VERSION ""

NS_ :

BS_:
BU_: FLR_L FRR_L mADC

BO_ 604 FLR_L_25C: 64 FLR_L
 SG_ FLR_OBJ26_LostCnt : 483|4@0+ (1.0000000000,0.0000000000) [0.0000000000|15.0000000000] ""  FRR_L,mADC
 SG_ FLR_OBJ25_LostCnt : 495|4@0+ (1.0000000000,0.0000000000) [0.0000000000|15.0000000000] ""  FRR_L,mADC
 SG_ FLR_OBJ26_Dx : 230|13@0+ (0.0625000000,-256.0000000000) [-256.0000000000|255.9380000000] "m"  FRR_L,mADC
 SG_ FLR_OBJ26_Dy : 209|11@0+ (0.1250000000,-128.0000000000) [-128.0000000000|127.8750000000] "m"  FRR_L,mADC
 SG_ FLR_OBJ25_Dx : 59|13@0+ (0.0625000000,-256.0000000000) [-256.0000000000|255.9380000000] "m"  FRR_L,mADC
 SG_ FLR_OBJ25_Dy : 54|11@0+ (0.1250000000,-128.0000000000) [-128.0000000000|127.8750000000] "m"  FRR_L,mADC
 SG_ FLR_OBJ26_Vx : 310|12@0+ (0.0625000000,-128.0000000000) [-128.0000000000|127.9380000000] "m/s"  FRR_L,mADC
 SG_ FLR_OBJ26_Vy : 288|10@0+ (0.0625000000,-32.0000000000) [-32.0000000000|31.9375000000] "m/s"  FRR_L,mADC
 SG_ FLR_OBJ26_Convergence : 458|1@0+ (1.0000000000,0.0000000000) [0.0000000000|1.0000000000] ""  FRR_L,mADC
 SG_ FLR_OBJ26_DelayTime : 453|10@0+ (1.0000000000,0.0000000000) [0.0000000000|1023.0000000000] "ms"  FRR_L,mADC
 SG_ FLR_OBJ26_HeightGround : 424|9@0+ (0.1000000000,0.0000000000) [0.0000000000|51.1000000000] "m"  FRR_L,mADC
 SG_ FLR_OBJ26_MotionStatus : 470|3@0+ (1.0000000000,0.0000000000) [0.0000000000|7.0000000000] ""  FRR_L,mADC
 SG_ FLR_OBJ26_RelVx_std : 413|12@0+ (0.0625000000,0.0000000000) [0.0000000000|255.9375000000] "m/s"  FRR_L,mADC
 SG_ FLR_OBJ26_RelVy_std : 407|10@0+ (0.1250000000,0.0000000000) [0.0000000000|127.8750000000] "m/s"  FRR_L,mADC
 SG_ FLR_OBJ26_Dx_Vnce : 389|14@0+ (0.0500000000,0.0000000000) [0.0000000000|50.0000000000] "m2"  FRR_L,mADC
 SG_ FLR_OBJ26_Dy_Vnce : 383|10@0+ (0.0200000000,0.0000000000) [0.0000000000|20.0000000000] "m2"  FRR_L,mADC
 SG_ FLR_OBJ25_Vx : 139|12@0+ (0.0625000000,-128.0000000000) [-128.0000000000|127.9380000000] "m/s"  FRR_L,mADC
 SG_ FLR_OBJ25_Vy : 133|10@0+ (0.0625000000,-32.0000000000) [-32.0000000000|31.9375000000] "m/s"  FRR_L,mADC
 SG_ FLR_OBJ25_Convergence : 459|1@0+ (1.0000000000,0.0000000000) [0.0000000000|1.0000000000] ""  FRR_L,mADC
 SG_ FLR_OBJ25_DelayTime : 447|10@0+ (1.0000000000,0.0000000000) [0.0000000000|1023.0000000000] "ms"  FRR_L,mADC
 SG_ FLR_OBJ25_HeightGround : 417|9@0+ (0.1000000000,0.0000000000) [0.0000000000|51.1000000000] "m"  FRR_L,mADC
 SG_ FLR_OBJ25_MotionStatus : 457|3@0+ (1.0000000000,0.0000000000) [0.0000000000|7.0000000000] ""  FRR_L,mADC
 SG_ FLR_OBJ25_RelVx_std : 363|12@0+ (0.0625000000,0.0000000000) [0.0000000000|255.9375000000] "m/s"  FRR_L,mADC
 SG_ FLR_OBJ25_RelVy_std : 357|10@0+ (0.1250000000,0.0000000000) [0.0000000000|127.8750000000] "m/s"  FRR_L,mADC
 SG_ FLR_OBJ25_Dx_Vnce : 339|14@0+ (0.0500000000,0.0000000000) [0.0000000000|50.0000000000] "m2"  FRR_L,mADC
 SG_ FLR_OBJ25_Dy_Vnce : 333|10@0+ (0.0200000000,0.0000000000) [0.0000000000|20.0000000000] "m2"  FRR_L,mADC
 SG_ FLR_CRCCheck_25C : 503|16@0+ (1.0000000000,0.0000000000) [0.0000000000|65535.0000000000] ""  FRR_L,mADC
 SG_ FLR_RollingCounter_25C : 491|4@0+ (1.0000000000,0.0000000000) [0.0000000000|15.0000000000] ""  FRR_L,mADC
 SG_ FLR_OBJ26_Track_Age : 325|8@0+ (1.0000000000,0.0000000000) [0.0000000000|255.0000000000] ""  FRR_L,mADC
 SG_ FLR_OBJ26_RefPointLoc : 312|3@0+ (1.0000000000,0.0000000000) [0.0000000000|7.0000000000] ""  FRR_L,mADC
 SG_ FLR_OBJ26_ObstacleProb : 294|6@0+ (2.0000000000,0.0000000000) [0.0000000000|100.0000000000] "%"  FRR_L,mADC
 SG_ FLR_OBJ26_Measured : 280|2@0+ (1.0000000000,0.0000000000) [0.0000000000|3.0000000000] ""  FRR_L,mADC
 SG_ FLR_OBJ26_ExistProb : 286|6@0+ (2.0000000000,0.0000000000) [0.0000000000|100.0000000000] "%"  FRR_L,mADC
 SG_ FLR_OBJ26_Location : 272|2@0+ (1.0000000000,0.0000000000) [0.0000000000|3.0000000000] ""  FRR_L,mADC
 SG_ FLR_OBJ26_RelAx : 265|9@0+ (0.0625000000,-16.0000000000) [-16.0000000000|15.9375000000] "m/s2"  FRR_L,mADC
 SG_ FLR_OBJ26_RelAy : 259|10@0+ (0.0312500000,-16.0000000000) [-16.0000000000|15.9688000000] "m/s2"  FRR_L,mADC
 SG_ FLR_OBJ26_RelVx : 255|12@0+ (0.0625000000,-128.0000000000) [-128.0000000000|127.9380000000] "m/s"  FRR_L,mADC
 SG_ FLR_OBJ26_RelVy : 233|10@0+ (0.0625000000,-32.0000000000) [-32.0000000000|63.8750000000] "m/s"  FRR_L,mADC
 SG_ FLR_OBJ26_HeadingAngle : 203|10@0+ (0.0100000000,-3.1400000000) [-3.1400000000|3.1400000000] "rad"  FRR_L,mADC
 SG_ FLR_OBJ26_Length : 196|9@0+ (0.0500000000,0.0000000000) [0.0000000000|25.5000000000] "m"  FRR_L,mADC
 SG_ FLR_OBJ26_Height : 189|9@0+ (0.0100000000,0.0000000000) [0.0000000000|5.1100000000] "m"  FRR_L,mADC
 SG_ FLR_OBJ26_Width : 168|11@0+ (0.0100000000,0.0000000000) [0.0000000000|12.0000000000] "m"  FRR_L,mADC
 SG_ FLR_OBJ26_Type : 171|3@0+ (1.0000000000,0.0000000000) [0.0000000000|7.0000000000] ""  FRR_L,mADC
 SG_ FLR_OBJ26_Track_ID : 162|7@0+ (1.0000000000,0.0000000000) [0.0000000000|127.0000000000] ""  FRR_L,mADC
 SG_ FLR_OBJ25_Track_Age : 154|8@0+ (1.0000000000,0.0000000000) [0.0000000000|255.0000000000] ""  FRR_L,mADC
 SG_ FLR_OBJ25_RefPointLoc : 157|3@0+ (1.0000000000,0.0000000000) [0.0000000000|7.0000000000] ""  FRR_L,mADC
 SG_ FLR_OBJ25_ObstacleProb : 123|6@0+ (2.0000000000,0.0000000000) [0.0000000000|100.0000000000] "%"  FRR_L,mADC
 SG_ FLR_OBJ25_Measured : 125|2@0+ (1.0000000000,0.0000000000) [0.0000000000|3.0000000000] ""  FRR_L,mADC
 SG_ FLR_OBJ25_ExistProb : 115|6@0+ (2.0000000000,0.0000000000) [0.0000000000|100.0000000000] "%"  FRR_L,mADC
 SG_ FLR_OBJ25_Location : 117|2@0+ (1.0000000000,0.0000000000) [0.0000000000|3.0000000000] ""  FRR_L,mADC
 SG_ FLR_OBJ25_RelAx : 110|9@0+ (0.0625000000,-16.0000000000) [-16.0000000000|15.9375000000] "m/s2"  FRR_L,mADC
 SG_ FLR_OBJ25_RelAy : 88|10@0+ (0.0312500000,-16.0000000000) [-16.0000000000|15.9688000000] "m/s2"  FRR_L,mADC
 SG_ FLR_OBJ25_RelVx : 84|12@0+ (0.0625000000,-128.0000000000) [-128.0000000000|127.9380000000] "m/s"  FRR_L,mADC
 SG_ FLR_OBJ25_RelVy : 78|10@0+ (0.0625000000,-32.0000000000) [-32.0000000000|63.8750000000] "m/s"  FRR_L,mADC
 SG_ FLR_OBJ25_HeadingAngle : 32|10@0+ (0.0100000000,-3.1400000000) [-3.1400000000|3.1400000000] "rad"  FRR_L,mADC
 SG_ FLR_OBJ25_Length : 25|9@0+ (0.0500000000,0.0000000000) [0.0000000000|25.5000000000] "m"  FRR_L,mADC
 SG_ FLR_OBJ25_Height : 18|9@0+ (0.0100000000,0.0000000000) [0.0000000000|5.1100000000] "m"  FRR_L,mADC
 SG_ FLR_OBJ25_Width : 13|11@0+ (0.0100000000,0.0000000000) [0.0000000000|12.0000000000] "m"  FRR_L,mADC
 SG_ FLR_OBJ25_Type : 0|3@0+ (1.0000000000,0.0000000000) [0.0000000000|7.0000000000] ""  FRR_L,mADC
 SG_ FLR_OBJ25_Track_ID : 7|7@0+ (1.0000000000,0.0000000000) [0.0000000000|127.0000000000] ""  FRR_L,mADC

BO_ 605 FLR_L_25D: 64 FLR_L
 SG_ FLR_OBJ28_LostCnt : 483|4@0+ (1.0000000000,0.0000000000) [0.0000000000|15.0000000000] ""  FRR_L,mADC
 SG_ FLR_OBJ27_LostCnt : 495|4@0+ (1.0000000000,0.0000000000) [0.0000000000|15.0000000000] ""  FRR_L,mADC
 SG_ FLR_OBJ28_Dx : 230|13@0+ (0.0625000000,-256.0000000000) [-256.0000000000|255.9380000000] "m"  FRR_L,mADC
 SG_ FLR_OBJ28_Dy : 209|11@0+ (0.1250000000,-128.0000000000) [-128.0000000000|127.8750000000] "m"  FRR_L,mADC
 SG_ FLR_OBJ27_Dx : 59|13@0+ (0.0625000000,-256.0000000000) [-256.0000000000|255.9380000000] "m"  FRR_L,mADC
 SG_ FLR_OBJ27_Dy : 54|11@0+ (0.1250000000,-128.0000000000) [-128.0000000000|127.8750000000] "m"  FRR_L,mADC
 SG_ FLR_OBJ28_Vx : 310|12@0+ (0.0625000000,-128.0000000000) [-128.0000000000|127.9380000000] "m/s"  FRR_L,mADC
 SG_ FLR_OBJ28_Vy : 288|10@0+ (0.0625000000,-32.0000000000) [-32.0000000000|31.9375000000] "m/s"  FRR_L,mADC
 SG_ FLR_OBJ28_Convergence : 458|1@0+ (1.0000000000,0.0000000000) [0.0000000000|1.0000000000] ""  FRR_L,mADC
 SG_ FLR_OBJ28_DelayTime : 453|10@0+ (1.0000000000,0.0000000000) [0.0000000000|1023.0000000000] "ms"  FRR_L,mADC
 SG_ FLR_OBJ28_HeightGround : 424|9@0+ (0.1000000000,0.0000000000) [0.0000000000|51.1000000000] "m"  FRR_L,mADC
 SG_ FLR_OBJ28_MotionStatus : 470|3@0+ (1.0000000000,0.0000000000) [0.0000000000|7.0000000000] ""  FRR_L,mADC
 SG_ FLR_OBJ28_RelVx_std : 413|12@0+ (0.0625000000,0.0000000000) [0.0000000000|255.9375000000] "m/s"  FRR_L,mADC
 SG_ FLR_OBJ28_RelVy_std : 407|10@0+ (0.1250000000,0.0000000000) [0.0000000000|127.8750000000] "m/s"  FRR_L,mADC
 SG_ FLR_OBJ28_Dx_Vnce : 389|14@0+ (0.0500000000,0.0000000000) [0.0000000000|50.0000000000] "m2"  FRR_L,mADC
 SG_ FLR_OBJ28_Dy_Vnce : 383|10@0+ (0.0200000000,0.0000000000) [0.0000000000|20.0000000000] "m2"  FRR_L,mADC
 SG_ FLR_OBJ27_Vx : 139|12@0+ (0.0625000000,-128.0000000000) [-128.0000000000|127.9380000000] "m/s"  FRR_L,mADC
 SG_ FLR_OBJ27_Vy : 133|10@0+ (0.0625000000,-32.0000000000) [-32.0000000000|31.9375000000] "m/s"  FRR_L,mADC
 SG_ FLR_OBJ27_Convergence : 459|1@0+ (1.0000000000,0.0000000000) [0.0000000000|1.0000000000] ""  FRR_L,mADC
 SG_ FLR_OBJ27_DelayTime : 447|10@0+ (1.0000000000,0.0000000000) [0.0000000000|1023.0000000000] "ms"  FRR_L,mADC
 SG_ FLR_OBJ27_HeightGround : 417|9@0+ (0.1000000000,0.0000000000) [0.0000000000|51.1000000000] "m"  FRR_L,mADC
 SG_ FLR_OBJ27_MotionStatus : 457|3@0+ (1.0000000000,0.0000000000) [0.0000000000|7.0000000000] ""  FRR_L,mADC
 SG_ FLR_OBJ27_RelVx_std : 363|12@0+ (0.0625000000,0.0000000000) [0.0000000000|255.9375000000] "m/s"  FRR_L,mADC
 SG_ FLR_OBJ27_RelVy_std : 357|10@0+ (0.1250000000,0.0000000000) [0.0000000000|127.8750000000] "m/s"  FRR_L,mADC
 SG_ FLR_OBJ27_Dx_Vnce : 339|14@0+ (0.0500000000,0.0000000000) [0.0000000000|50.0000000000] "m2"  FRR_L,mADC
 SG_ FLR_OBJ27_Dy_Vnce : 333|10@0+ (0.0200000000,0.0000000000) [0.0000000000|20.0000000000] "m2"  FRR_L,mADC
 SG_ FLR_CRCCheck_25D : 503|16@0+ (1.0000000000,0.0000000000) [0.0000000000|65535.0000000000] ""  FRR_L,mADC
 SG_ FLR_RollingCounter_25D : 491|4@0+ (1.0000000000,0.0000000000) [0.0000000000|15.0000000000] ""  FRR_L,mADC
 SG_ FLR_OBJ28_Track_Age : 325|8@0+ (1.0000000000,0.0000000000) [0.0000000000|255.0000000000] ""  FRR_L,mADC
 SG_ FLR_OBJ28_RefPointLoc : 312|3@0+ (1.0000000000,0.0000000000) [0.0000000000|7.0000000000] ""  FRR_L,mADC
 SG_ FLR_OBJ28_ObstacleProb : 294|6@0+ (2.0000000000,0.0000000000) [0.0000000000|100.0000000000] "%"  FRR_L,mADC
 SG_ FLR_OBJ28_Measured : 280|2@0+ (1.0000000000,0.0000000000) [0.0000000000|3.0000000000] ""  FRR_L,mADC
 SG_ FLR_OBJ28_ExistProb : 286|6@0+ (2.0000000000,0.0000000000) [0.0000000000|100.0000000000] "%"  FRR_L,mADC
 SG_ FLR_OBJ28_Location : 272|2@0+ (1.0000000000,0.0000000000) [0.0000000000|3.0000000000] ""  FRR_L,mADC
 SG_ FLR_OBJ28_RelAx : 265|9@0+ (0.0625000000,-16.0000000000) [-16.0000000000|15.9375000000] "m/s2"  FRR_L,mADC
 SG_ FLR_OBJ28_RelAy : 259|10@0+ (0.0312500000,-16.0000000000) [-16.0000000000|15.9688000000] "m/s2"  FRR_L,mADC
 SG_ FLR_OBJ28_RelVx : 255|12@0+ (0.0625000000,-128.0000000000) [-128.0000000000|127.9380000000] "m/s"  FRR_L,mADC
 SG_ FLR_OBJ28_RelVy : 233|10@0+ (0.0625000000,-32.0000000000) [-32.0000000000|63.8750000000] "m/s"  FRR_L,mADC
 SG_ FLR_OBJ28_HeadingAngle : 203|10@0+ (0.0100000000,-3.1400000000) [-3.1400000000|3.1400000000] "rad"  FRR_L,mADC
 SG_ FLR_OBJ28_Length : 196|9@0+ (0.0500000000,0.0000000000) [0.0000000000|25.5000000000] "m"  FRR_L,mADC
 SG_ FLR_OBJ28_Height : 189|9@0+ (0.0100000000,0.0000000000) [0.0000000000|5.1100000000] "m"  FRR_L,mADC
 SG_ FLR_OBJ28_Width : 168|11@0+ (0.0100000000,0.0000000000) [0.0000000000|12.0000000000] "m"  FRR_L,mADC
 SG_ FLR_OBJ28_Type : 171|3@0+ (1.0000000000,0.0000000000) [0.0000000000|7.0000000000] ""  FRR_L,mADC
 SG_ FLR_OBJ28_Track_ID : 162|7@0+ (1.0000000000,0.0000000000) [0.0000000000|127.0000000000] ""  FRR_L,mADC
 SG_ FLR_OBJ27_Track_Age : 154|8@0+ (1.0000000000,0.0000000000) [0.0000000000|255.0000000000] ""  FRR_L,mADC
 SG_ FLR_OBJ27_RefPointLoc : 157|3@0+ (1.0000000000,0.0000000000) [0.0000000000|7.0000000000] ""  FRR_L,mADC
 SG_ FLR_OBJ27_ObstacleProb : 123|6@0+ (2.0000000000,0.0000000000) [0.0000000000|100.0000000000] "%"  FRR_L,mADC
 SG_ FLR_OBJ27_Measured : 125|2@0+ (1.0000000000,0.0000000000) [0.0000000000|3.0000000000] ""  FRR_L,mADC
 SG_ FLR_OBJ27_ExistProb : 115|6@0+ (2.0000000000,0.0000000000) [0.0000000000|100.0000000000] "%"  FRR_L,mADC
 SG_ FLR_OBJ27_Location : 117|2@0+ (1.0000000000,0.0000000000) [0.0000000000|3.0000000000] ""  FRR_L,mADC
 SG_ FLR_OBJ27_RelAx : 110|9@0+ (0.0625000000,-16.0000000000) [-16.0000000000|15.9375000000] "m/s2"  FRR_L,mADC
 SG_ FLR_OBJ27_RelAy : 88|10@0+ (0.0312500000,-16.0000000000) [-16.0000000000|15.9688000000] "m/s2"  FRR_L,mADC
 SG_ FLR_OBJ27_RelVx : 84|12@0+ (0.0625000000,-128.0000000000) [-128.0000000000|127.9380000000] "m/s"  FRR_L,mADC
 SG_ FLR_OBJ27_RelVy : 78|10@0+ (0.0625000000,-32.0000000000) [-32.0000000000|63.8750000000] "m/s"  FRR_L,mADC
 SG_ FLR_OBJ27_HeadingAngle : 32|10@0+ (0.0100000000,-3.1400000000) [-3.1400000000|3.1400000000] "rad"  FRR_L,mADC
 SG_ FLR_OBJ27_Length : 25|9@0+ (0.0500000000,0.0000000000) [0.0000000000|25.5000000000] "m"  FRR_L,mADC
 SG_ FLR_OBJ27_Height : 18|9@0+ (0.0100000000,0.0000000000) [0.0000000000|5.1100000000] "m"  FRR_L,mADC
 SG_ FLR_OBJ27_Width : 13|11@0+ (0.0100000000,0.0000000000) [0.0000000000|12.0000000000] "m"  FRR_L,mADC
 SG_ FLR_OBJ27_Type : 0|3@0+ (1.0000000000,0.0000000000) [0.0000000000|7.0000000000] ""  FRR_L,mADC
 SG_ FLR_OBJ27_Track_ID : 7|7@0+ (1.0000000000,0.0000000000) [0.0000000000|127.0000000000] ""  FRR_L,mADC

BO_ 606 FLR_L_25E: 64 FLR_L
 SG_ FLR_OBJ30_LostCnt : 483|4@0+ (1.0000000000,0.0000000000) [0.0000000000|15.0000000000] ""  FRR_L,mADC
 SG_ FLR_OBJ29_LostCnt : 495|4@0+ (1.0000000000,0.0000000000) [0.0000000000|15.0000000000] ""  FRR_L,mADC
 SG_ FLR_OBJ30_Dx : 230|13@0+ (0.0625000000,-256.0000000000) [-256.0000000000|255.9380000000] "m"  FRR_L,mADC
 SG_ FLR_OBJ30_Dy : 209|11@0+ (0.1250000000,-128.0000000000) [-128.0000000000|127.8750000000] "m"  FRR_L,mADC
 SG_ FLR_OBJ29_Dx : 59|13@0+ (0.0625000000,-256.0000000000) [-256.0000000000|255.9380000000] "m"  FRR_L,mADC
 SG_ FLR_OBJ29_Dy : 54|11@0+ (0.1250000000,-128.0000000000) [-128.0000000000|127.8750000000] "m"  FRR_L,mADC
 SG_ FLR_OBJ30_Vx : 310|12@0+ (0.0625000000,-128.0000000000) [-128.0000000000|127.9380000000] "m/s"  FRR_L,mADC
 SG_ FLR_OBJ30_Vy : 288|10@0+ (0.0625000000,-32.0000000000) [-32.0000000000|31.9375000000] "m/s"  FRR_L,mADC
 SG_ FLR_OBJ30_Convergence : 458|1@0+ (1.0000000000,0.0000000000) [0.0000000000|1.0000000000] ""  FRR_L,mADC
 SG_ FLR_OBJ30_DelayTime : 453|10@0+ (1.0000000000,0.0000000000) [0.0000000000|1023.0000000000] "ms"  FRR_L,mADC
 SG_ FLR_OBJ30_HeightGround : 424|9@0+ (0.1000000000,0.0000000000) [0.0000000000|51.1000000000] "m"  FRR_L,mADC
 SG_ FLR_OBJ30_MotionStatus : 470|3@0+ (1.0000000000,0.0000000000) [0.0000000000|7.0000000000] ""  FRR_L,mADC
 SG_ FLR_OBJ30_RelVx_std : 413|12@0+ (0.0625000000,0.0000000000) [0.0000000000|255.9375000000] "m/s"  FRR_L,mADC
 SG_ FLR_OBJ30_RelVy_std : 407|10@0+ (0.1250000000,0.0000000000) [0.0000000000|127.8750000000] "m/s"  FRR_L,mADC
 SG_ FLR_OBJ30_Dx_Vnce : 389|14@0+ (0.0500000000,0.0000000000) [0.0000000000|50.0000000000] "m2"  FRR_L,mADC
 SG_ FLR_OBJ30_Dy_Vnce : 383|10@0+ (0.0200000000,0.0000000000) [0.0000000000|20.0000000000] "m2"  FRR_L,mADC
 SG_ FLR_OBJ29_Vx : 139|12@0+ (0.0625000000,-128.0000000000) [-128.0000000000|127.9380000000] "m/s"  FRR_L,mADC
 SG_ FLR_OBJ29_Vy : 133|10@0+ (0.0625000000,-32.0000000000) [-32.0000000000|31.9375000000] "m/s"  FRR_L,mADC
 SG_ FLR_OBJ29_Convergence : 459|1@0+ (1.0000000000,0.0000000000) [0.0000000000|1.0000000000] ""  FRR_L,mADC
 SG_ FLR_OBJ29_DelayTime : 447|10@0+ (1.0000000000,0.0000000000) [0.0000000000|1023.0000000000] "ms"  FRR_L,mADC
 SG_ FLR_OBJ29_HeightGround : 417|9@0+ (0.1000000000,0.0000000000) [0.0000000000|51.1000000000] "m"  FRR_L,mADC
 SG_ FLR_OBJ29_MotionStatus : 457|3@0+ (1.0000000000,0.0000000000) [0.0000000000|7.0000000000] ""  FRR_L,mADC
 SG_ FLR_OBJ29_RelVx_std : 363|12@0+ (0.0625000000,0.0000000000) [0.0000000000|255.9375000000] "m/s"  FRR_L,mADC
 SG_ FLR_OBJ29_RelVy_std : 357|10@0+ (0.1250000000,0.0000000000) [0.0000000000|127.8750000000] "m/s"  FRR_L,mADC
 SG_ FLR_OBJ29_Dx_Vnce : 339|14@0+ (0.0500000000,0.0000000000) [0.0000000000|50.0000000000] "m2"  FRR_L,mADC
 SG_ FLR_OBJ29_Dy_Vnce : 333|10@0+ (0.0200000000,0.0000000000) [0.0000000000|20.0000000000] "m2"  FRR_L,mADC
 SG_ FLR_CRCCheck_25E : 503|16@0+ (1.0000000000,0.0000000000) [0.0000000000|65535.0000000000] ""  FRR_L,mADC
 SG_ FLR_RollingCounter_25E : 491|4@0+ (1.0000000000,0.0000000000) [0.0000000000|15.0000000000] ""  FRR_L,mADC
 SG_ FLR_OBJ30_Track_Age : 325|8@0+ (1.0000000000,0.0000000000) [0.0000000000|255.0000000000] ""  FRR_L,mADC
 SG_ FLR_OBJ30_RefPointLoc : 312|3@0+ (1.0000000000,0.0000000000) [0.0000000000|7.0000000000] ""  FRR_L,mADC
 SG_ FLR_OBJ30_ObstacleProb : 294|6@0+ (2.0000000000,0.0000000000) [0.0000000000|100.0000000000] "%"  FRR_L,mADC
 SG_ FLR_OBJ30_Measured : 280|2@0+ (1.0000000000,0.0000000000) [0.0000000000|3.0000000000] ""  FRR_L,mADC
 SG_ FLR_OBJ30_ExistProb : 286|6@0+ (2.0000000000,0.0000000000) [0.0000000000|100.0000000000] "%"  FRR_L,mADC
 SG_ FLR_OBJ30_Location : 272|2@0+ (1.0000000000,0.0000000000) [0.0000000000|3.0000000000] ""  FRR_L,mADC
 SG_ FLR_OBJ30_RelAx : 265|9@0+ (0.0625000000,-16.0000000000) [-16.0000000000|15.9375000000] "m/s2"  FRR_L,mADC
 SG_ FLR_OBJ30_RelAy : 259|10@0+ (0.0312500000,-16.0000000000) [-16.0000000000|15.9688000000] "m/s2"  FRR_L,mADC
 SG_ FLR_OBJ30_RelVx : 255|12@0+ (0.0625000000,-128.0000000000) [-128.0000000000|127.9380000000] "m/s"  FRR_L,mADC
 SG_ FLR_OBJ30_RelVy : 233|10@0+ (0.0625000000,-32.0000000000) [-32.0000000000|63.8750000000] "m/s"  FRR_L,mADC
 SG_ FLR_OBJ30_HeadingAngle : 203|10@0+ (0.0100000000,-3.1400000000) [-3.1400000000|3.1400000000] "rad"  FRR_L,mADC
 SG_ FLR_OBJ30_Length : 196|9@0+ (0.0500000000,0.0000000000) [0.0000000000|25.5000000000] "m"  FRR_L,mADC
 SG_ FLR_OBJ30_Height : 189|9@0+ (0.0100000000,0.0000000000) [0.0000000000|5.1100000000] "m"  FRR_L,mADC
 SG_ FLR_OBJ30_Width : 168|11@0+ (0.0100000000,0.0000000000) [0.0000000000|12.0000000000] "m"  FRR_L,mADC
 SG_ FLR_OBJ30_Type : 171|3@0+ (1.0000000000,0.0000000000) [0.0000000000|7.0000000000] ""  FRR_L,mADC
 SG_ FLR_OBJ30_Track_ID : 162|7@0+ (1.0000000000,0.0000000000) [0.0000000000|127.0000000000] ""  FRR_L,mADC
 SG_ FLR_OBJ29_Track_Age : 154|8@0+ (1.0000000000,0.0000000000) [0.0000000000|255.0000000000] ""  FRR_L,mADC
 SG_ FLR_OBJ29_RefPointLoc : 157|3@0+ (1.0000000000,0.0000000000) [0.0000000000|7.0000000000] ""  FRR_L,mADC
 SG_ FLR_OBJ29_ObstacleProb : 123|6@0+ (2.0000000000,0.0000000000) [0.0000000000|100.0000000000] "%"  FRR_L,mADC
 SG_ FLR_OBJ29_Measured : 125|2@0+ (1.0000000000,0.0000000000) [0.0000000000|3.0000000000] ""  FRR_L,mADC
 SG_ FLR_OBJ29_ExistProb : 115|6@0+ (2.0000000000,0.0000000000) [0.0000000000|100.0000000000] "%"  FRR_L,mADC
 SG_ FLR_OBJ29_Location : 117|2@0+ (1.0000000000,0.0000000000) [0.0000000000|3.0000000000] ""  FRR_L,mADC
 SG_ FLR_OBJ29_RelAx : 110|9@0+ (0.0625000000,-16.0000000000) [-16.0000000000|15.9375000000] "m/s2"  FRR_L,mADC
 SG_ FLR_OBJ29_RelAy : 88|10@0+ (0.0312500000,-16.0000000000) [-16.0000000000|15.9688000000] "m/s2"  FRR_L,mADC
 SG_ FLR_OBJ29_RelVx : 84|12@0+ (0.0625000000,-128.0000000000) [-128.0000000000|127.9380000000] "m/s"  FRR_L,mADC
 SG_ FLR_OBJ29_RelVy : 78|10@0+ (0.0625000000,-32.0000000000) [-32.0000000000|63.8750000000] "m/s"  FRR_L,mADC
 SG_ FLR_OBJ29_HeadingAngle : 32|10@0+ (0.0100000000,-3.1400000000) [-3.1400000000|3.1400000000] "rad"  FRR_L,mADC
 SG_ FLR_OBJ29_Length : 25|9@0+ (0.0500000000,0.0000000000) [0.0000000000|25.5000000000] "m"  FRR_L,mADC
 SG_ FLR_OBJ29_Height : 18|9@0+ (0.0100000000,0.0000000000) [0.0000000000|5.1100000000] "m"  FRR_L,mADC
 SG_ FLR_OBJ29_Width : 13|11@0+ (0.0100000000,0.0000000000) [0.0000000000|12.0000000000] "m"  FRR_L,mADC
 SG_ FLR_OBJ29_Type : 0|3@0+ (1.0000000000,0.0000000000) [0.0000000000|7.0000000000] ""  FRR_L,mADC
 SG_ FLR_OBJ29_Track_ID : 7|7@0+ (1.0000000000,0.0000000000) [0.0000000000|127.0000000000] ""  FRR_L,mADC

BO_ 607 FLR_L_25F: 64 FLR_L
 SG_ FLR_OBJ32_LostCnt : 483|4@0+ (1.0000000000,0.0000000000) [0.0000000000|15.0000000000] ""  FRR_L,mADC
 SG_ FLR_OBJ31_LostCnt : 495|4@0+ (1.0000000000,0.0000000000) [0.0000000000|15.0000000000] ""  FRR_L,mADC
 SG_ FLR_OBJ32_Dx : 230|13@0+ (0.0625000000,-256.0000000000) [-256.0000000000|255.9380000000] "m"  FRR_L,mADC
 SG_ FLR_OBJ32_Dy : 209|11@0+ (0.1250000000,-128.0000000000) [-128.0000000000|127.8750000000] "m"  FRR_L,mADC
 SG_ FLR_OBJ31_Dx : 59|13@0+ (0.0625000000,-256.0000000000) [-256.0000000000|255.9380000000] "m"  FRR_L,mADC
 SG_ FLR_OBJ31_Dy : 54|11@0+ (0.1250000000,-128.0000000000) [-128.0000000000|127.8750000000] "m"  FRR_L,mADC
 SG_ FLR_OBJ32_Vx : 310|12@0+ (0.0625000000,-128.0000000000) [-128.0000000000|127.9380000000] "m/s"  FRR_L,mADC
 SG_ FLR_OBJ32_Vy : 288|10@0+ (0.0625000000,-32.0000000000) [-32.0000000000|31.9375000000] "m/s"  FRR_L,mADC
 SG_ FLR_OBJ32_Convergence : 458|1@0+ (1.0000000000,0.0000000000) [0.0000000000|1.0000000000] ""  FRR_L,mADC
 SG_ FLR_OBJ32_DelayTime : 453|10@0+ (1.0000000000,0.0000000000) [0.0000000000|1023.0000000000] "ms"  FRR_L,mADC
 SG_ FLR_OBJ32_HeightGround : 424|9@0+ (0.1000000000,0.0000000000) [0.0000000000|51.1000000000] "m"  FRR_L,mADC
 SG_ FLR_OBJ32_MotionStatus : 470|3@0+ (1.0000000000,0.0000000000) [0.0000000000|7.0000000000] ""  FRR_L,mADC
 SG_ FLR_OBJ32_RelVx_std : 413|12@0+ (0.0625000000,0.0000000000) [0.0000000000|255.9375000000] "m/s"  FRR_L,mADC
 SG_ FLR_OBJ32_RelVy_std : 407|10@0+ (0.1250000000,0.0000000000) [0.0000000000|127.8750000000] "m/s"  FRR_L,mADC
 SG_ FLR_OBJ32_Dx_Vnce : 389|14@0+ (0.0500000000,0.0000000000) [0.0000000000|50.0000000000] "m2"  FRR_L,mADC
 SG_ FLR_OBJ32_Dy_Vnce : 383|10@0+ (0.0200000000,0.0000000000) [0.0000000000|20.0000000000] "m2"  FRR_L,mADC
 SG_ FLR_OBJ31_Vx : 139|12@0+ (0.0625000000,-128.0000000000) [-128.0000000000|127.9380000000] "m/s"  FRR_L,mADC
 SG_ FLR_OBJ31_Vy : 133|10@0+ (0.0625000000,-32.0000000000) [-32.0000000000|31.9375000000] "m/s"  FRR_L,mADC
 SG_ FLR_OBJ31_Convergence : 459|1@0+ (1.0000000000,0.0000000000) [0.0000000000|1.0000000000] ""  FRR_L,mADC
 SG_ FLR_OBJ31_DelayTime : 447|10@0+ (1.0000000000,0.0000000000) [0.0000000000|1023.0000000000] "ms"  FRR_L,mADC
 SG_ FLR_OBJ31_HeightGround : 417|9@0+ (0.1000000000,0.0000000000) [0.0000000000|51.1000000000] "m"  FRR_L,mADC
 SG_ FLR_OBJ31_MotionStatus : 457|3@0+ (1.0000000000,0.0000000000) [0.0000000000|7.0000000000] ""  FRR_L,mADC
 SG_ FLR_OBJ31_RelVx_std : 363|12@0+ (0.0625000000,0.0000000000) [0.0000000000|255.9375000000] "m/s"  FRR_L,mADC
 SG_ FLR_OBJ31_RelVy_std : 357|10@0+ (0.1250000000,0.0000000000) [0.0000000000|127.8750000000] "m/s"  FRR_L,mADC
 SG_ FLR_OBJ31_Dx_Vnce : 339|14@0+ (0.0500000000,0.0000000000) [0.0000000000|50.0000000000] "m2"  FRR_L,mADC
 SG_ FLR_OBJ31_Dy_Vnce : 333|10@0+ (0.0200000000,0.0000000000) [0.0000000000|20.0000000000] "m2"  FRR_L,mADC
 SG_ FLR_CRCCheck_25F : 503|16@0+ (1.0000000000,0.0000000000) [0.0000000000|65535.0000000000] ""  FRR_L,mADC
 SG_ FLR_RollingCounter_25F : 491|4@0+ (1.0000000000,0.0000000000) [0.0000000000|15.0000000000] ""  FRR_L,mADC
 SG_ FLR_OBJ32_Track_Age : 325|8@0+ (1.0000000000,0.0000000000) [0.0000000000|255.0000000000] ""  FRR_L,mADC
 SG_ FLR_OBJ32_RefPointLoc : 312|3@0+ (1.0000000000,0.0000000000) [0.0000000000|7.0000000000] ""  FRR_L,mADC
 SG_ FLR_OBJ32_ObstacleProb : 294|6@0+ (2.0000000000,0.0000000000) [0.0000000000|100.0000000000] "%"  FRR_L,mADC
 SG_ FLR_OBJ32_Measured : 280|2@0+ (1.0000000000,0.0000000000) [0.0000000000|3.0000000000] ""  FRR_L,mADC
 SG_ FLR_OBJ32_ExistProb : 286|6@0+ (2.0000000000,0.0000000000) [0.0000000000|100.0000000000] "%"  FRR_L,mADC
 SG_ FLR_OBJ32_Location : 272|2@0+ (1.0000000000,0.0000000000) [0.0000000000|3.0000000000] ""  FRR_L,mADC
 SG_ FLR_OBJ32_RelAx : 265|9@0+ (0.0625000000,-16.0000000000) [-16.0000000000|15.9375000000] "m/s2"  FRR_L,mADC
 SG_ FLR_OBJ32_RelAy : 259|10@0+ (0.0312500000,-16.0000000000) [-16.0000000000|15.9688000000] "m/s2"  FRR_L,mADC
 SG_ FLR_OBJ32_RelVx : 255|12@0+ (0.0625000000,-128.0000000000) [-128.0000000000|127.9380000000] "m/s"  FRR_L,mADC
 SG_ FLR_OBJ32_RelVy : 233|10@0+ (0.0625000000,-32.0000000000) [-32.0000000000|63.8750000000] "m/s"  FRR_L,mADC
 SG_ FLR_OBJ32_HeadingAngle : 203|10@0+ (0.0100000000,-3.1400000000) [-3.1400000000|3.1400000000] "rad"  FRR_L,mADC
 SG_ FLR_OBJ32_Length : 196|9@0+ (0.0500000000,0.0000000000) [0.0000000000|25.5000000000] "m"  FRR_L,mADC
 SG_ FLR_OBJ32_Height : 189|9@0+ (0.0100000000,0.0000000000) [0.0000000000|5.1100000000] "m"  FRR_L,mADC
 SG_ FLR_OBJ32_Width : 168|11@0+ (0.0100000000,0.0000000000) [0.0000000000|12.0000000000] "m"  FRR_L,mADC
 SG_ FLR_OBJ32_Type : 171|3@0+ (1.0000000000,0.0000000000) [0.0000000000|7.0000000000] ""  FRR_L,mADC
 SG_ FLR_OBJ32_Track_ID : 162|7@0+ (1.0000000000,0.0000000000) [0.0000000000|127.0000000000] ""  FRR_L,mADC
 SG_ FLR_OBJ31_Track_Age : 154|8@0+ (1.0000000000,0.0000000000) [0.0000000000|255.0000000000] ""  FRR_L,mADC
 SG_ FLR_OBJ31_RefPointLoc : 157|3@0+ (1.0000000000,0.0000000000) [0.0000000000|7.0000000000] ""  FRR_L,mADC
 SG_ FLR_OBJ31_ObstacleProb : 123|6@0+ (2.0000000000,0.0000000000) [0.0000000000|100.0000000000] "%"  FRR_L,mADC
 SG_ FLR_OBJ31_Measured : 125|2@0+ (1.0000000000,0.0000000000) [0.0000000000|3.0000000000] ""  FRR_L,mADC
 SG_ FLR_OBJ31_ExistProb : 115|6@0+ (2.0000000000,0.0000000000) [0.0000000000|100.0000000000] "%"  FRR_L,mADC
 SG_ FLR_OBJ31_Location : 117|2@0+ (1.0000000000,0.0000000000) [0.0000000000|3.0000000000] ""  FRR_L,mADC
 SG_ FLR_OBJ31_RelAx : 110|9@0+ (0.0625000000,-16.0000000000) [-16.0000000000|15.9375000000] "m/s2"  FRR_L,mADC
 SG_ FLR_OBJ31_RelAy : 88|10@0+ (0.0312500000,-16.0000000000) [-16.0000000000|15.9688000000] "m/s2"  FRR_L,mADC
 SG_ FLR_OBJ31_RelVx : 84|12@0+ (0.0625000000,-128.0000000000) [-128.0000000000|127.9380000000] "m/s"  FRR_L,mADC
 SG_ FLR_OBJ31_RelVy : 78|10@0+ (0.0625000000,-32.0000000000) [-32.0000000000|63.8750000000] "m/s"  FRR_L,mADC
 SG_ FLR_OBJ31_HeadingAngle : 32|10@0+ (0.0100000000,-3.1400000000) [-3.1400000000|3.1400000000] "rad"  FRR_L,mADC
 SG_ FLR_OBJ31_Length : 25|9@0+ (0.0500000000,0.0000000000) [0.0000000000|25.5000000000] "m"  FRR_L,mADC
 SG_ FLR_OBJ31_Height : 18|9@0+ (0.0100000000,0.0000000000) [0.0000000000|5.1100000000] "m"  FRR_L,mADC
 SG_ FLR_OBJ31_Width : 13|11@0+ (0.0100000000,0.0000000000) [0.0000000000|12.0000000000] "m"  FRR_L,mADC
 SG_ FLR_OBJ31_Type : 0|3@0+ (1.0000000000,0.0000000000) [0.0000000000|7.0000000000] ""  FRR_L,mADC
 SG_ FLR_OBJ31_Track_ID : 7|7@0+ (1.0000000000,0.0000000000) [0.0000000000|127.0000000000] ""  FRR_L,mADC

BO_ 642 FLR_L_282: 64 FLR_L
 SG_ FRGuardrailReadyFlag : 333|1@0+ (1.0000000000,0.0000000000) [0.0000000000|1.0000000000] ""  FRR_L,mADC
 SG_ FLGuardrailReadyFlag : 332|1@0+ (1.0000000000,0.0000000000) [0.0000000000|1.0000000000] ""  FRR_L,mADC
 SG_ FLR_CRCCheck_282 : 503|16@0+ (1.0000000000,0.0000000000) [0.0000000000|65535.0000000000] ""  FRR_L,mADC
 SG_ FLR_RollingCounter_282 : 491|4@0+ (1.0000000000,0.0000000000) [0.0000000000|15.0000000000] ""  FRR_L,mADC
 SG_ FLR_FrontRightGuardrailConfidenc : 473|2@0+ (1.0000000000,0.0000000000) [0.0000000000|3.0000000000] "-"  FRR_L,mADC
 SG_ FLR__FronRightGuardrail_End : 469|12@0+ (0.0250000000,-20.0000000000) [-20.0000000000|82.3750000000] "m"  FRR_L,mADC
 SG_ FLR__FronRightGuardrail_Start : 449|12@0+ (0.0250000000,-20.0000000000) [-20.0000000000|82.3750000000] "m"  FRR_L,mADC
 SG_ FLR_FrontRightGuardrailC3 : 445|12@0+ (0.0000004800,-0.0010000000) [-0.0010000000|0.0009760860] "-"  FRR_L,mADC
 SG_ FLR_FrontRightGuardrailC2 : 425|12@0+ (0.0000150000,-0.0312000000) [-0.0312000000|0.0312347410] "-"  FRR_L,mADC
 SG_ FLR_FrontRightGuardrailC1 : 421|12@0+ (0.0004900000,-1.0000000000) [-1.0000000000|0.9990234380] "-"  FRR_L,mADC
 SG_ FLR_FrontRightGuardrailC0 : 401|12@0+ (0.0156300000,-32.0000000000) [-32.0000000000|31.9843750000] "m"  FRR_L,mADC
 SG_ FLR_FrontLeftGuardrailConfidence : 403|2@0+ (1.0000000000,0.0000000000) [0.0000000000|3.0000000000] "-"  FRR_L,mADC
 SG_ FLR__FrontLeftGuardrail_End : 399|12@0+ (0.0250000000,-20.0000000000) [-20.0000000000|82.3750000000] "m"  FRR_L,mADC
 SG_ FLR__FrontLeftGuardrail_Start : 379|12@0+ (0.0250000000,-20.0000000000) [-20.0000000000|82.3750000000] "m"  FRR_L,mADC
 SG_ FLR_FrontLeftGuardrailC3 : 375|12@0+ (0.0000004800,-0.0010000000) [-0.0010000000|0.0009760860] "-"  FRR_L,mADC
 SG_ FLR_FrontLeftGuardrailC2 : 355|12@0+ (0.0000150000,-0.0312000000) [-0.0312000000|0.0312347410] "-"  FRR_L,mADC
 SG_ FLR_FrontLeftGuardrailC1 : 351|12@0+ (0.0004900000,-1.0000000000) [-1.0000000000|0.9990234380] "-"  FRR_L,mADC
 SG_ FLR_FrontLeftGuardrailC0 : 331|12@0+ (0.0156300000,-32.0000000000) [-32.0000000000|31.9843750000] "m"  FRR_L,mADC
 SG_ FLR_LocHeader_RollingCounter : 155|4@0+ (1.0000000000,0.0000000000) [0.0000000000|15.0000000000] ""  FRR_L,mADC

BO_ 687 FLR_L_2AF: 64 FLR_L
 SG_ FRR_HwVers6 : 255|8@0+ (1.0000000000,0.0000000000) [0.0000000000|255.0000000000] ""  FRR_L,mADC
 SG_ FRR_HwVers5 : 247|8@0+ (1.0000000000,0.0000000000) [0.0000000000|255.0000000000] ""  FRR_L,mADC
 SG_ FRR_HwVers4 : 231|16@0+ (1.0000000000,0.0000000000) [0.0000000000|65535.0000000000] ""  FRR_L,mADC
 SG_ FRR_HwVers3 : 223|8@0+ (1.0000000000,0.0000000000) [0.0000000000|255.0000000000] ""  FRR_L,mADC
 SG_ FRR_HwVers2 : 215|8@0+ (1.0000000000,0.0000000000) [0.0000000000|255.0000000000] ""  FRR_L,mADC
 SG_ FRR_HwVers1 : 207|8@0+ (1.0000000000,0.0000000000) [0.0000000000|255.0000000000] ""  FRR_L,mADC
 SG_ FRR_HwVers0 : 199|8@0+ (1.0000000000,0.0000000000) [0.0000000000|255.0000000000] ""  FRR_L,mADC
 SG_ FRR_SwVers6 : 191|8@0+ (1.0000000000,0.0000000000) [0.0000000000|255.0000000000] ""  FRR_L,mADC
 SG_ FRR_SwVers5 : 183|8@0+ (1.0000000000,0.0000000000) [0.0000000000|255.0000000000] ""  FRR_L,mADC
 SG_ FRR_SwVers4 : 167|16@0+ (1.0000000000,0.0000000000) [0.0000000000|65535.0000000000] ""  FRR_L,mADC
 SG_ FRR_SwVers3 : 159|8@0+ (1.0000000000,0.0000000000) [0.0000000000|255.0000000000] ""  FRR_L,mADC
 SG_ FRR_SwVers2 : 151|8@0+ (1.0000000000,0.0000000000) [0.0000000000|255.0000000000] ""  FRR_L,mADC
 SG_ FRR_SwVers1 : 143|8@0+ (1.0000000000,0.0000000000) [0.0000000000|255.0000000000] ""  FRR_L,mADC
 SG_ FRR_SwVers0 : 135|8@0+ (1.0000000000,0.0000000000) [0.0000000000|255.0000000000] ""  FRR_L,mADC
 SG_ FLR_HwVers6 : 127|8@0+ (1.0000000000,0.0000000000) [0.0000000000|255.0000000000] ""  FRR_L,mADC
 SG_ FLR_HwVers5 : 119|8@0+ (1.0000000000,0.0000000000) [0.0000000000|255.0000000000] ""  FRR_L,mADC
 SG_ FLR_HwVers4 : 103|16@0+ (1.0000000000,0.0000000000) [0.0000000000|65535.0000000000] ""  FRR_L,mADC
 SG_ FLR_HwVers3 : 95|8@0+ (1.0000000000,0.0000000000) [0.0000000000|255.0000000000] ""  FRR_L,mADC
 SG_ FLR_HwVers2 : 87|8@0+ (1.0000000000,0.0000000000) [0.0000000000|255.0000000000] ""  FRR_L,mADC
 SG_ FLR_HwVers1 : 79|8@0+ (1.0000000000,0.0000000000) [0.0000000000|255.0000000000] ""  FRR_L,mADC
 SG_ FLR_HwVers0 : 71|8@0+ (1.0000000000,0.0000000000) [0.0000000000|255.0000000000] ""  FRR_L,mADC
 SG_ FLR_SwVers6 : 63|8@0+ (1.0000000000,0.0000000000) [0.0000000000|255.0000000000] ""  FRR_L,mADC
 SG_ FLR_SwVers5 : 55|8@0+ (1.0000000000,0.0000000000) [0.0000000000|255.0000000000] ""  FRR_L,mADC
 SG_ FLR_SwVers4 : 39|16@0+ (1.0000000000,0.0000000000) [0.0000000000|65535.0000000000] ""  FRR_L,mADC
 SG_ FLR_SwVers3 : 31|8@0+ (1.0000000000,0.0000000000) [0.0000000000|255.0000000000] ""  FRR_L,mADC
 SG_ FLR_SwVers2 : 23|8@0+ (1.0000000000,0.0000000000) [0.0000000000|255.0000000000] ""  FRR_L,mADC
 SG_ FLR_SwVers1 : 15|8@0+ (1.0000000000,0.0000000000) [0.0000000000|255.0000000000] ""  FRR_L,mADC
 SG_ FLR_SwVers0 : 7|8@0+ (1.0000000000,0.0000000000) [0.0000000000|255.0000000000] ""  FRR_L,mADC

BO_ 690 FLR_L_2B2: 64 FLR_L
 SG_ RLR_CRCCheck_2B2 : 503|16@0+ (1.0000000000,0.0000000000) [0.0000000000|65535.0000000000] ""  FRR_L,mADC
 SG_ RLR_RollingCounter_2B2 : 491|4@0+ (1.0000000000,0.0000000000) [0.0000000000|15.0000000000] ""  FRR_L,mADC
 SG_ FLR_ResetSts : 250|3@0+ (1.0000000000,0.0000000000) [0.0000000000|7.0000000000] ""  FRR_L,mADC
 SG_ FuncDegradeType_FL : 223|32@0+ (1.0000000000,0.0000000000) [0.0000000000|4294967295.0000000000] ""  FRR_L,mADC
 SG_ FUSION_TimeoutCnt_FL : 215|8@0+ (1.0000000000,0.0000000000) [0.0000000000|255.0000000000] ""  FRR_L,mADC
 SG_ VALIDATION_TimeoutCnt_FL : 207|8@0+ (1.0000000000,0.0000000000) [0.0000000000|255.0000000000] ""  FRR_L,mADC
 SG_ CurFrameCycle_FL : 199|8@0+ (1.0000000000,0.0000000000) [0.0000000000|255.0000000000] ""  FRR_L,mADC
 SG_ ProcessTimeoutCnt_FL : 191|8@0+ (1.0000000000,0.0000000000) [0.0000000000|255.0000000000] ""  FRR_L,mADC
 SG_ RevFrameCnt_FL : 159|32@0+ (1.0000000000,0.0000000000) [0.0000000000|4294967295.0000000000] ""  FRR_L,mADC
 SG_ Local_Pointcloud_Number_FL : 151|8@0+ (1.0000000000,0.0000000000) [0.0000000000|255.0000000000] ""  FRR_L,mADC
 SG_ RealTimeCal_PrcssBar_FL : 142|7@0+ (1.0000000000,0.0000000000) [0.0000000000|100.0000000000] "%"  FRR_L,mADC
 SG_ RealTimeCal_VelErrOutput_FL : 134|7@0+ (0.1000000000,-5.0000000000) [-5.0000000000|5.0000000000] "%"  FRR_L,mADC
 SG_ RealTimeCal_HoriMntErrOutput_FL : 112|9@0+ (0.0200000000,-5.0000000000) [-5.0000000000|5.0000000000] "бу"  FRR_L,mADC
 SG_ RealTimeCal_FailReasonCode_FL : 116|3@0+ (1.0000000000,0.0000000000) [0.0000000000|7.0000000000] ""  FRR_L,mADC
 SG_ RealTimeCal_Status_FL : 119|3@0+ (1.0000000000,0.0000000000) [0.0000000000|7.0000000000] ""  FRR_L,mADC
 SG_ DiagCal_PrcssBar_FL : 110|7@0+ (1.0000000000,0.0000000000) [0.0000000000|100.0000000000] "%"  FRR_L,mADC
 SG_ DiagCal_VelErrOutput_FL : 102|7@0+ (0.1000000000,-5.0000000000) [-5.0000000000|5.0000000000] "%"  FRR_L,mADC
 SG_ DiagCal_HoriMntErrOutput_FL : 80|9@0+ (0.0200000000,-5.0000000000) [-5.0000000000|5.0000000000] "бу"  FRR_L,mADC
 SG_ DiagCal_FailReasonCode_FL : 84|3@0+ (1.0000000000,0.0000000000) [0.0000000000|7.0000000000] ""  FRR_L,mADC
 SG_ DiagCal_Status_FL : 87|3@0+ (1.0000000000,0.0000000000) [0.0000000000|7.0000000000] ""  FRR_L,mADC
 SG_ EolCal_PrcssBar_FL : 78|7@0+ (1.0000000000,0.0000000000) [0.0000000000|100.0000000000] "%"  FRR_L,mADC
 SG_ EolCal_VelErrOutput_FL : 70|7@0+ (0.1000000000,-5.0000000000) [-5.0000000000|5.0000000000] "%"  FRR_L,mADC
 SG_ EolCal_HoriMntErrOutput_FL : 48|9@0+ (0.0200000000,-5.0000000000) [-5.0000000000|5.0000000000] "бу"  FRR_L,mADC
 SG_ EolCal_FailReasonCode_FL : 52|3@0+ (1.0000000000,0.0000000000) [0.0000000000|7.0000000000] ""  FRR_L,mADC
 SG_ EolCal_Status_FL : 55|3@0+ (1.0000000000,0.0000000000) [0.0000000000|7.0000000000] ""  FRR_L,mADC
 SG_ PriCounter_FL : 31|24@0+ (1.0000000000,0.0000000000) [0.0000000000|16777215.0000000000] ""  FRR_L,mADC
 SG_ MsgCounter_FL : 7|24@0+ (1.0000000000,0.0000000000) [0.0000000000|16777215.0000000000] ""  FRR_L,mADC

BO_ 579 FLR_L_243: 64 FLR_L
 SG_ Transmitcnt6_F : 455|32@0+ (1.0000000000,0.0000000000) [0.0000000000|4294967295.0000000000] ""  FRR_L,mADC
 SG_ Transmitcnt5_F : 423|32@0+ (1.0000000000,0.0000000000) [0.0000000000|4294967295.0000000000] ""  FRR_L,mADC
 SG_ Transmitcnt4_F : 391|32@0+ (1.0000000000,0.0000000000) [0.0000000000|4294967295.0000000000] ""  FRR_L,mADC
 SG_ Transmitcnt3_F : 359|32@0+ (1.0000000000,0.0000000000) [0.0000000000|4294967295.0000000000] ""  FRR_L,mADC
 SG_ Transmitcnt2_F : 327|32@0+ (1.0000000000,0.0000000000) [0.0000000000|4294967295.0000000000] ""  FRR_L,mADC
 SG_ Transmitcnt1_F : 295|32@0+ (1.0000000000,0.0000000000) [0.0000000000|4294967295.0000000000] ""  FRR_L,mADC
 SG_ FLR_Track_ID_R : 270|7@0+ (1.0000000000,0.0000000000) [0.0000000000|127.0000000000] ""  FRR_L,mADC
 SG_ FLR_Measured_R : 273|2@0+ (1.0000000000,0.0000000000) [0.0000000000|3.0000000000] ""  FRR_L,mADC
 SG_ FLR_Location_R : 199|2@0+ (1.0000000000,0.0000000000) [0.0000000000|3.0000000000] ""  FRR_L,mADC
 SG_ FLR_ClassComfrmFlg_R : 271|1@0+ (1.0000000000,0.0000000000) [0.0000000000|1.0000000000] ""  FRR_L,mADC
 SG_ FLR_TrckrType_R : 197|3@0+ (1.0000000000,0.0000000000) [0.0000000000|7.0000000000] ""  FRR_L,mADC
 SG_ FLR_TrckrAge_R : 263|8@0+ (1.0000000000,0.0000000000) [0.0000000000|255.0000000000] ""  FRR_L,mADC
 SG_ FLR_MotionStatus_R : 194|3@0+ (1.0000000000,0.0000000000) [0.0000000000|7.0000000000] ""  FRR_L,mADC
 SG_ FLR_AbsVy_R : 207|12@0+ (0.0625000000,-128.0000000000) [-128.0000000000|127.9380000000] "m/s"  FRR_L,mADC
 SG_ FLR_AbsoVx_R : 211|10@0+ (0.1250000000,-64.0000000000) [-64.0000000000|63.8750000000] "m/s"  FRR_L,mADC
 SG_ FLR_LocDx_R : 217|13@0+ (0.0625000000,-256.0000000000) [-256.0000000000|255.9380000000] "m"  FRR_L,mADC
 SG_ FLR_LocDy_R : 236|11@0+ (0.1250000000,-128.0000000000) [-128.0000000000|127.8750000000] "m"  FRR_L,mADC
 SG_ FLR_HeadingAngle_R : 241|10@0+ (0.0100000000,-3.1400000000) [-3.1400000000|3.1400000000] "rad"  FRR_L,mADC
 SG_ FLR_Length_R : 132|9@0+ (0.0500000000,0.0000000000) [0.0000000000|25.5000000000] "m"  FRR_L,mADC
 SG_ FLR_Width_R : 139|11@0+ (0.0100000000,0.0000000000) [0.0000000000|12.0000000000] "m"  FRR_L,mADC
 SG_ FLR_Track_ID_L : 144|7@0+ (1.0000000000,0.0000000000) [0.0000000000|127.0000000000] ""  FRR_L,mADC
 SG_ FLR_Measured_L : 153|2@0+ (1.0000000000,0.0000000000) [0.0000000000|3.0000000000] ""  FRR_L,mADC
 SG_ FLR_Location_L : 167|2@0+ (1.0000000000,0.0000000000) [0.0000000000|3.0000000000] ""  FRR_L,mADC
 SG_ FLR_ClassComfrmFlg_L : 164|1@0+ (1.0000000000,0.0000000000) [0.0000000000|1.0000000000] ""  FRR_L,mADC
 SG_ FLR_TrckrType_L : 163|3@0+ (1.0000000000,0.0000000000) [0.0000000000|7.0000000000] ""  FRR_L,mADC
 SG_ FLR_TrckrAge_L : 71|8@0+ (1.0000000000,0.0000000000) [0.0000000000|255.0000000000] ""  FRR_L,mADC
 SG_ FLR_MotionStatus_L : 160|3@0+ (1.0000000000,0.0000000000) [0.0000000000|7.0000000000] ""  FRR_L,mADC
 SG_ FLR_AbsVy_L : 173|12@0+ (0.0625000000,-128.0000000000) [-128.0000000000|127.9380000000] "m/s"  FRR_L,mADC
 SG_ FLR_AbsoVx_L : 177|10@0+ (0.1250000000,-64.0000000000) [-64.0000000000|63.8750000000] "m/s"  FRR_L,mADC
 SG_ FLR_LocDx_L : 79|13@0+ (0.0625000000,-256.0000000000) [-256.0000000000|255.9380000000] "m"  FRR_L,mADC
 SG_ FLR_LocDy_L : 82|11@0+ (0.1250000000,-128.0000000000) [-128.0000000000|127.8750000000] "m"  FRR_L,mADC
 SG_ FLR_HeadingAngle_L : 103|10@0+ (0.0100000000,-3.1400000000) [-3.1400000000|3.1400000000] "rad"  FRR_L,mADC
 SG_ FLR_Length_L : 109|9@0+ (0.0500000000,0.0000000000) [0.0000000000|25.5000000000] "m"  FRR_L,mADC
 SG_ FLR_Width_L : 116|11@0+ (0.0100000000,0.0000000000) [0.0000000000|12.0000000000] "m"  FRR_L,mADC
 SG_ FLR_TrckrNum : 121|2@0+ (1.0000000000,0.0000000000) [3.0000000000|3.0000000000] ""  FRR_L,mADC
 SG_ FLR_TrackerTimeStamp : 7|64@0+ (0.0001000000,0.0000000000) [0.0000000000|429496.7295000000] "s"  FRR_L,mADC

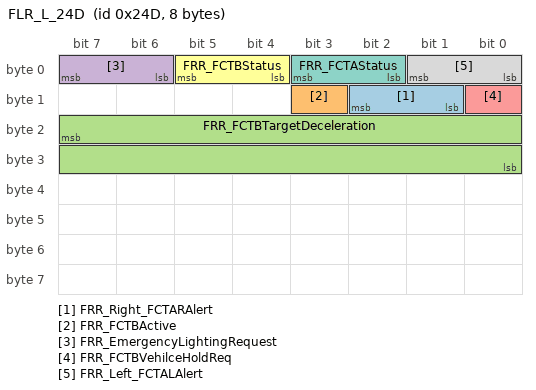
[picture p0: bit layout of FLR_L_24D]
BO_ 589 FLR_L_24D: 8 FLR_L
 SG_ FRR_Right_FCTARAlert : 10|2@0+ (1.0000000000,0.0000000000) [0.0000000000|3.0000000000] ""  FRR_L,mADC
 SG_ FRR_FCTBActive : 11|1@0+ (1.0000000000,0.0000000000) [0.0000000000|1.0000000000] ""  FRR_L,mADC
 SG_ FRR_FCTBTargetDeceleration : 23|16@0+ (0.0005000000,-16.0000000000) [-16.0000000000|16.0000000000] "m/s2"  FRR_L,mADC
 SG_ FRR_EmergencyLightingRequest : 7|2@0+ (1.0000000000,0.0000000000) [0.0000000000|3.0000000000] ""  FRR_L,mADC
 SG_ FRR_FCTBVehilceHoldReq : 8|1@0+ (1.0000000000,0.0000000000) [0.0000000000|1.0000000000] ""  FRR_L,mADC
 SG_ FRR_FCTBStatus : 5|2@0+ (1.0000000000,0.0000000000) [0.0000000000|3.0000000000] ""  FRR_L,mADC
 SG_ FRR_FCTAStatus : 3|2@0+ (1.0000000000,0.0000000000) [0.0000000000|3.0000000000] ""  FRR_L,mADC
 SG_ FRR_Left_FCTALAlert : 1|2@0+ (1.0000000000,0.0000000000) [0.0000000000|3.0000000000] ""  FRR_L,mADC

BO_ 694 FLR_L_2B6: 64 FLR_L
 SG_ RLR_CRCCheck_2B6 : 503|16@0+ (1.0000000000,0.0000000000) [0.0000000000|65535.0000000000] ""  FRR_L,mADC
 SG_ RLR_RollingCounter_2B6 : 491|4@0+ (1.0000000000,0.0000000000) [0.0000000000|15.0000000000] ""  FRR_L,mADC
 SG_ FLR_OBJ32_lAy : 333|10@0+ (0.0312500000,-16.0000000000) [-16.0000000000|15.9688000000] "m/s2"  FRR_L,mADC
 SG_ FLR_OBJ31_lAy : 327|10@0+ (0.0312500000,-16.0000000000) [-16.0000000000|15.9688000000] "m/s2"  FRR_L,mADC
 SG_ FLR_OBJ30_lAy : 309|10@0+ (0.0312500000,-16.0000000000) [-16.0000000000|15.9688000000] "m/s2"  FRR_L,mADC
 SG_ FLR_OBJ29_lAy : 303|10@0+ (0.0312500000,-16.0000000000) [-16.0000000000|15.9688000000] "m/s2"  FRR_L,mADC
 SG_ FLR_OBJ28_lAy : 281|10@0+ (0.0312500000,-16.0000000000) [-16.0000000000|15.9688000000] "m/s2"  FRR_L,mADC
 SG_ FLR_OBJ27_lAy : 275|10@0+ (0.0312500000,-16.0000000000) [-16.0000000000|15.9688000000] "m/s2"  FRR_L,mADC
 SG_ FLR_OBJ26_lAy : 269|10@0+ (0.0312500000,-16.0000000000) [-16.0000000000|15.9688000000] "m/s2"  FRR_L,mADC
 SG_ FLR_OBJ25_lAy : 263|10@0+ (0.0312500000,-16.0000000000) [-16.0000000000|15.9688000000] "m/s2"  FRR_L,mADC
 SG_ FLR_OBJ24_lAy : 245|10@0+ (0.0312500000,-16.0000000000) [-16.0000000000|15.9688000000] "m/s2"  FRR_L,mADC
 SG_ FLR_OBJ23_lAy : 239|10@0+ (0.0312500000,-16.0000000000) [-16.0000000000|15.9688000000] "m/s2"  FRR_L,mADC
 SG_ FLR_OBJ22_lAy : 217|10@0+ (0.0312500000,-16.0000000000) [-16.0000000000|15.9688000000] "m/s2"  FRR_L,mADC
 SG_ FLR_OBJ21_lAy : 211|10@0+ (0.0312500000,-16.0000000000) [-16.0000000000|15.9688000000] "m/s2"  FRR_L,mADC
 SG_ FLR_OBJ20_lAy : 205|10@0+ (0.0312500000,-16.0000000000) [-16.0000000000|15.9688000000] "m/s2"  FRR_L,mADC
 SG_ FLR_OBJ19_lAy : 199|10@0+ (0.0312500000,-16.0000000000) [-16.0000000000|15.9688000000] "m/s2"  FRR_L,mADC
 SG_ FLR_OBJ18_lAy : 181|10@0+ (0.0312500000,-16.0000000000) [-16.0000000000|15.9688000000] "m/s2"  FRR_L,mADC
 SG_ FLR_OBJ17_lAy : 175|10@0+ (0.0312500000,-16.0000000000) [-16.0000000000|15.9688000000] "m/s2"  FRR_L,mADC
 SG_ FLR_OBJ16_lAy : 153|10@0+ (0.0312500000,-16.0000000000) [-16.0000000000|15.9688000000] "m/s2"  FRR_L,mADC
 SG_ FLR_OBJ15_lAy : 147|10@0+ (0.0312500000,-16.0000000000) [-16.0000000000|15.9688000000] "m/s2"  FRR_L,mADC
 SG_ FLR_OBJ14_lAy : 141|10@0+ (0.0312500000,-16.0000000000) [-16.0000000000|15.9688000000] "m/s2"  FRR_L,mADC
 SG_ FLR_OBJ13_lAy : 135|10@0+ (0.0312500000,-16.0000000000) [-16.0000000000|15.9688000000] "m/s2"  FRR_L,mADC
 SG_ FLR_OBJ12_lAy : 117|10@0+ (0.0312500000,-16.0000000000) [-16.0000000000|15.9688000000] "m/s2"  FRR_L,mADC
 SG_ FLR_OBJ11_lAy : 111|10@0+ (0.0312500000,-16.0000000000) [-16.0000000000|15.9688000000] "m/s2"  FRR_L,mADC
 SG_ FLR_OBJ10_lAy : 89|10@0+ (0.0312500000,-16.0000000000) [-16.0000000000|15.9688000000] "m/s2"  FRR_L,mADC
 SG_ FLR_OBJ9_lAy : 83|10@0+ (0.0312500000,-16.0000000000) [-16.0000000000|15.9688000000] "m/s2"  FRR_L,mADC
 SG_ FLR_OBJ8_lAy : 77|10@0+ (0.0312500000,-16.0000000000) [-16.0000000000|15.9688000000] "m/s2"  FRR_L,mADC
 SG_ FLR_OBJ7_lAy : 71|10@0+ (0.0312500000,-16.0000000000) [-16.0000000000|15.9688000000] "m/s2"  FRR_L,mADC
 SG_ FLR_OBJ6_lAy : 53|10@0+ (0.0312500000,-16.0000000000) [-16.0000000000|15.9688000000] "m/s2"  FRR_L,mADC
 SG_ FLR_OBJ5_lAy : 47|10@0+ (0.0312500000,-16.0000000000) [-16.0000000000|15.9688000000] "m/s2"  FRR_L,mADC
 SG_ FLR_OBJ4_lAy : 25|10@0+ (0.0312500000,-16.0000000000) [-16.0000000000|15.9688000000] "m/s2"  FRR_L,mADC
 SG_ FLR_OBJ3_lAy : 19|10@0+ (0.0312500000,-16.0000000000) [-16.0000000000|15.9688000000] "m/s2"  FRR_L,mADC
 SG_ FLR_OBJ2_lAy : 13|10@0+ (0.0312500000,-16.0000000000) [-16.0000000000|15.9688000000] "m/s2"  FRR_L,mADC
 SG_ FLR_OBJ1_lAy : 7|10@0+ (0.0312500000,-16.0000000000) [-16.0000000000|15.9688000000] "m/s2"  FRR_L,mADC

BO_ 585 FRR_L_249: 64 FRR_L
 SG_ FRR_Suppliers : 187|4@0+ (1.0000000000,0.0000000000) [0.0000000000|15.0000000000] ""  FLR_L,mADC
 SG_ FRR_FS_TiOut : 165|1@0+ (1.0000000000,0.0000000000) [0.0000000000|1.0000000000] "-"  FLR_L,mADC
 SG_ FRR_FS_TiLeap : 164|1@0+ (1.0000000000,0.0000000000) [0.0000000000|1.0000000000] "-"  FLR_L,mADC
 SG_ FRR_FS_TiBas : 163|1@0+ (1.0000000000,0.0000000000) [0.0000000000|1.0000000000] "-"  FLR_L,mADC
 SG_ FRR_FS_TiStamp : 199|64@0+ (0.0001000000,0.0000000000) [0.0000000000|1844674407370950.0000000000] "s"  FLR_L,mADC
 SG_ FRR_CRCCheck_249 : 503|16@0+ (1.0000000000,0.0000000000) [0.0000000000|65535.0000000000] ""  FLR_L,mADC
 SG_ FRR_RollingCounter_249 : 491|4@0+ (1.0000000000,0.0000000000) [0.0000000000|15.0000000000] ""  FLR_L,mADC
 SG_ FRR_ECU_TiOut : 147|1@0+ (1.0000000000,0.0000000000) [0.0000000000|1.0000000000] "-"  FLR_L,mADC
 SG_ FRR_ECU_TiLeap : 148|1@0+ (1.0000000000,0.0000000000) [0.0000000000|1.0000000000] "-"  FLR_L,mADC
 SG_ FRR_ECU_TiBas : 149|1@0+ (1.0000000000,0.0000000000) [0.0000000000|1.0000000000] "-"  FLR_L,mADC
 SG_ FRR_ECU_TiStamp : 117|32@0+ (0.0001000000,0.0000000000) [0.0000000000|429496.7295000000] "s"  FLR_L,mADC
 SG_ FRR_MCUTiStamp : 101|16@0+ (1.0000000000,0.0000000000) [0.0000000000|65536.0000000000] "um"  FLR_L,mADC
 SG_ FRR_SyncTiStamp : 12|64@0+ (0.0001000000,0.0000000000) [0.0000000000|1844674407370950.0000000000] "s"  FLR_L,mADC
 SG_ FRR_WorkMode : 162|2@0+ (1.0000000000,0.0000000000) [0.0000000000|3.0000000000] ""  FLR_L,mADC
 SG_ FRR_ObjDelay : 4|8@0+ (1.0000000000,0.0000000000) [0.0000000000|255.0000000000] "ms"  FLR_L,mADC
 SG_ FRR_SystemStatus : 7|3@0+ (1.0000000000,0.0000000000) [0.0000000000|7.0000000000] ""  FLR_L,mADC

BO_ 666 FRR_L_29A: 64 FRR_L
 SG_ FLR_CRCCheck_29A : 503|16@0+ (1.0000000000,0.0000000000) [0.0000000000|65535.0000000000] ""  FLR_L,mADC
 SG_ FLR_RollingCounter_29A : 491|4@0+ (1.0000000000,0.0000000000) [0.0000000000|15.0000000000] ""  FLR_L,mADC
 SG_ FLR_FreespaceSectorKinestate34 : 477|2@0+ (1.0000000000,0.0000000000) [0.0000000000|3.0000000000] "-"  FLR_L,mADC
 SG_ FLR_FreespaceSectorConfidence34 : 479|2@0+ (1.0000000000,0.0000000000) [0.0000000000|3.0000000000] "-"  FLR_L,mADC
 SG_ FLR_FreespaceSectorDistance34 : 457|10@0+ (0.1000000000,0.0000000000) [0.0000000000|100.0000000000] "-"  FLR_L,mADC
 SG_ FLR_FreespaceSectorKinestate33 : 459|2@0+ (1.0000000000,0.0000000000) [0.0000000000|3.0000000000] "-"  FLR_L,mADC
 SG_ FLR_FreespaceSectorConfidence33 : 461|2@0+ (1.0000000000,0.0000000000) [0.0000000000|3.0000000000] "-"  FLR_L,mADC
 SG_ FLR_FreespaceSectorDistance33 : 455|10@0+ (0.1000000000,0.0000000000) [0.0000000000|100.0000000000] "-"  FLR_L,mADC
 SG_ FLR_FreespaceSectorKinestate32 : 441|2@0+ (1.0000000000,0.0000000000) [0.0000000000|3.0000000000] "-"  FLR_L,mADC
 SG_ FLR_FreespaceSectorConfidence32 : 443|2@0+ (1.0000000000,0.0000000000) [0.0000000000|3.0000000000] "-"  FLR_L,mADC
 SG_ FLR_FreespaceSectorDistance32 : 437|10@0+ (0.1000000000,0.0000000000) [0.0000000000|100.0000000000] "-"  FLR_L,mADC
 SG_ FLR_FreespaceSectorKinestate31 : 439|2@0+ (1.0000000000,0.0000000000) [0.0000000000|3.0000000000] "-"  FLR_L,mADC
 SG_ FLR_FreespaceSectorConfidence31 : 425|2@0+ (1.0000000000,0.0000000000) [0.0000000000|3.0000000000] "-"  FLR_L,mADC
 SG_ FLR_FreespaceSectorDistance31 : 419|10@0+ (0.1000000000,0.0000000000) [0.0000000000|100.0000000000] "-"  FLR_L,mADC
 SG_ FLR_FreespaceSectorKinestate30 : 421|2@0+ (1.0000000000,0.0000000000) [0.0000000000|3.0000000000] "-"  FLR_L,mADC
 SG_ FLR_FreespaceSectorConfidence30 : 423|2@0+ (1.0000000000,0.0000000000) [0.0000000000|3.0000000000] "-"  FLR_L,mADC
 SG_ FLR_FreespaceSectorDistance30 : 401|10@0+ (0.1000000000,0.0000000000) [0.0000000000|100.0000000000] "-"  FLR_L,mADC
 SG_ FLR_FreespaceSectorKinestate29 : 403|2@0+ (1.0000000000,0.0000000000) [0.0000000000|3.0000000000] "-"  FLR_L,mADC
 SG_ FLR_FreespaceSectorConfidence29 : 405|2@0+ (1.0000000000,0.0000000000) [0.0000000000|3.0000000000] "-"  FLR_L,mADC
 SG_ FLR_FreespaceSectorDistance29 : 399|10@0+ (0.1000000000,0.0000000000) [0.0000000000|100.0000000000] "-"  FLR_L,mADC
 SG_ FLR_FreespaceSectorKinestate28 : 385|2@0+ (1.0000000000,0.0000000000) [0.0000000000|3.0000000000] "-"  FLR_L,mADC
 SG_ FLR_FreespaceSectorConfidence28 : 387|2@0+ (1.0000000000,0.0000000000) [0.0000000000|3.0000000000] "-"  FLR_L,mADC
 SG_ FLR_FreespaceSectorDistance28 : 381|10@0+ (0.1000000000,0.0000000000) [0.0000000000|100.0000000000] "-"  FLR_L,mADC
 SG_ FLR_FreespaceSectorKinestate27 : 383|2@0+ (1.0000000000,0.0000000000) [0.0000000000|3.0000000000] "-"  FLR_L,mADC
 SG_ FLR_FreespaceSectorConfidence27 : 369|2@0+ (1.0000000000,0.0000000000) [0.0000000000|3.0000000000] "-"  FLR_L,mADC
 SG_ FLR_FreespaceSectorDistance27 : 363|10@0+ (0.1000000000,0.0000000000) [0.0000000000|100.0000000000] "-"  FLR_L,mADC
 SG_ FLR_FreespaceSectorKinestate26 : 365|2@0+ (1.0000000000,0.0000000000) [0.0000000000|3.0000000000] "-"  FLR_L,mADC
 SG_ FLR_FreespaceSectorConfidence26 : 367|2@0+ (1.0000000000,0.0000000000) [0.0000000000|3.0000000000] "-"  FLR_L,mADC
 SG_ FLR_FreespaceSectorDistance26 : 345|10@0+ (0.1000000000,0.0000000000) [0.0000000000|100.0000000000] "-"  FLR_L,mADC
 SG_ FLR_FreespaceSectorKinestate25 : 347|2@0+ (1.0000000000,0.0000000000) [0.0000000000|3.0000000000] "-"  FLR_L,mADC
 SG_ FLR_FreespaceSectorConfidence25 : 349|2@0+ (1.0000000000,0.0000000000) [0.0000000000|3.0000000000] "-"  FLR_L,mADC
 SG_ FLR_FreespaceSectorDistance25 : 343|10@0+ (0.1000000000,0.0000000000) [0.0000000000|100.0000000000] "-"  FLR_L,mADC
 SG_ FLR_FreespaceSectorKinestate24 : 329|2@0+ (1.0000000000,0.0000000000) [0.0000000000|3.0000000000] "-"  FLR_L,mADC
 SG_ FLR_FreespaceSectorConfidence24 : 331|2@0+ (1.0000000000,0.0000000000) [0.0000000000|3.0000000000] "-"  FLR_L,mADC
 SG_ FLR_FreespaceSectorDistance24 : 325|10@0+ (0.1000000000,0.0000000000) [0.0000000000|100.0000000000] "-"  FLR_L,mADC
 SG_ FLR_FreespaceSectorKinestate23 : 327|2@0+ (1.0000000000,0.0000000000) [0.0000000000|3.0000000000] "-"  FLR_L,mADC
 SG_ FLR_FreespaceSectorConfidence23 : 313|2@0+ (1.0000000000,0.0000000000) [0.0000000000|3.0000000000] "-"  FLR_L,mADC
 SG_ FLR_FreespaceSectorDistance23 : 307|10@0+ (0.1000000000,0.0000000000) [0.0000000000|100.0000000000] "-"  FLR_L,mADC
 SG_ FLR_FreespaceSectorKinestate22 : 309|2@0+ (1.0000000000,0.0000000000) [0.0000000000|3.0000000000] "-"  FLR_L,mADC
 SG_ FLR_FreespaceSectorConfidence22 : 311|2@0+ (1.0000000000,0.0000000000) [0.0000000000|3.0000000000] "-"  FLR_L,mADC
 SG_ FLR_FreespaceSectorDistance22 : 289|10@0+ (0.1000000000,0.0000000000) [0.0000000000|100.0000000000] "-"  FLR_L,mADC
 SG_ FLR_FreespaceSectorKinestate21 : 291|2@0+ (1.0000000000,0.0000000000) [0.0000000000|3.0000000000] "-"  FLR_L,mADC
 SG_ FLR_FreespaceSectorConfidence21 : 293|2@0+ (1.0000000000,0.0000000000) [0.0000000000|3.0000000000] "-"  FLR_L,mADC
 SG_ FLR_FreespaceSectorDistance21 : 287|10@0+ (0.1000000000,0.0000000000) [0.0000000000|100.0000000000] "-"  FLR_L,mADC
 SG_ FLR_FreespaceSectorKinestate20 : 273|2@0+ (1.0000000000,0.0000000000) [0.0000000000|3.0000000000] "-"  FLR_L,mADC
 SG_ FLR_FreespaceSectorConfidence20 : 275|2@0+ (1.0000000000,0.0000000000) [0.0000000000|3.0000000000] "-"  FLR_L,mADC
 SG_ FLR_FreespaceSectorDistance20 : 269|10@0+ (0.1000000000,0.0000000000) [0.0000000000|100.0000000000] "-"  FLR_L,mADC
 SG_ FLR_FreespaceSectorKinestate19 : 271|2@0+ (1.0000000000,0.0000000000) [0.0000000000|3.0000000000] "-"  FLR_L,mADC
 SG_ FLR_FreespaceSectorConfidence19 : 257|2@0+ (1.0000000000,0.0000000000) [0.0000000000|3.0000000000] "-"  FLR_L,mADC
 SG_ FLR_FreespaceSectorDistance19 : 251|10@0+ (0.1000000000,0.0000000000) [0.0000000000|100.0000000000] "-"  FLR_L,mADC
 SG_ FLR_FreespaceSectorKinestate18 : 253|2@0+ (1.0000000000,0.0000000000) [0.0000000000|3.0000000000] "-"  FLR_L,mADC
 SG_ FLR_FreespaceSectorConfidence18 : 255|2@0+ (1.0000000000,0.0000000000) [0.0000000000|3.0000000000] "-"  FLR_L,mADC
 SG_ FLR_FreespaceSectorDistance18 : 233|10@0+ (0.1000000000,0.0000000000) [0.0000000000|100.0000000000] "-"  FLR_L,mADC
 SG_ FLR_FreespaceSectorKinestate17 : 235|2@0+ (1.0000000000,0.0000000000) [0.0000000000|3.0000000000] "-"  FLR_L,mADC
 SG_ FLR_FreespaceSectorConfidence17 : 237|2@0+ (1.0000000000,0.0000000000) [0.0000000000|3.0000000000] "-"  FLR_L,mADC
 SG_ FLR_FreespaceSectorDistance17 : 231|10@0+ (0.1000000000,0.0000000000) [0.0000000000|100.0000000000] "-"  FLR_L,mADC
 SG_ FLR_FreespaceSectorKinestate16 : 217|2@0+ (1.0000000000,0.0000000000) [0.0000000000|3.0000000000] "-"  FLR_L,mADC
 SG_ FLR_FreespaceSectorConfidence16 : 219|2@0+ (1.0000000000,0.0000000000) [0.0000000000|3.0000000000] "-"  FLR_L,mADC
 SG_ FLR_FreespaceSectorDistance16 : 213|10@0+ (0.1000000000,0.0000000000) [0.0000000000|100.0000000000] "-"  FLR_L,mADC
 SG_ FLR_FreespaceSectorKinestate15 : 215|2@0+ (1.0000000000,0.0000000000) [0.0000000000|3.0000000000] "-"  FLR_L,mADC
 SG_ FLR_FreespaceSectorConfidence15 : 201|2@0+ (1.0000000000,0.0000000000) [0.0000000000|3.0000000000] "-"  FLR_L,mADC
 SG_ FLR_FreespaceSectorDistance15 : 195|10@0+ (0.1000000000,0.0000000000) [0.0000000000|100.0000000000] "-"  FLR_L,mADC
 SG_ FLR_FreespaceSectorKinestate14 : 197|2@0+ (1.0000000000,0.0000000000) [0.0000000000|3.0000000000] "-"  FLR_L,mADC
 SG_ FLR_FreespaceSectorConfidence14 : 199|2@0+ (1.0000000000,0.0000000000) [0.0000000000|3.0000000000] "-"  FLR_L,mADC
 SG_ FLR_FreespaceSectorDistance14 : 177|10@0+ (0.1000000000,0.0000000000) [0.0000000000|100.0000000000] "-"  FLR_L,mADC
 SG_ FLR_FreespaceSectorKinestate13 : 179|2@0+ (1.0000000000,0.0000000000) [0.0000000000|3.0000000000] "-"  FLR_L,mADC
 SG_ FLR_FreespaceSectorConfidence13 : 181|2@0+ (1.0000000000,0.0000000000) [0.0000000000|3.0000000000] "-"  FLR_L,mADC
 SG_ FLR_FreespaceSectorDistance13 : 175|10@0+ (0.1000000000,0.0000000000) [0.0000000000|100.0000000000] "-"  FLR_L,mADC
 SG_ FLR_FreespaceSectorKinestate12 : 161|2@0+ (1.0000000000,0.0000000000) [0.0000000000|3.0000000000] "-"  FLR_L,mADC
 SG_ FLR_FreespaceSectorConfidence12 : 163|2@0+ (1.0000000000,0.0000000000) [0.0000000000|3.0000000000] "-"  FLR_L,mADC
 SG_ FLR_FreespaceSectorDistance12 : 157|10@0+ (0.1000000000,0.0000000000) [0.0000000000|100.0000000000] "-"  FLR_L,mADC
 SG_ FLR_FreespaceSectorKinestate11 : 159|2@0+ (1.0000000000,0.0000000000) [0.0000000000|3.0000000000] "-"  FLR_L,mADC
 SG_ FLR_FreespaceSectorConfidence11 : 145|2@0+ (1.0000000000,0.0000000000) [0.0000000000|3.0000000000] "-"  FLR_L,mADC
 SG_ FLR_FreespaceSectorDistance11 : 139|10@0+ (0.1000000000,0.0000000000) [0.0000000000|100.0000000000] "-"  FLR_L,mADC
 SG_ FLR_FreespaceSectorKinestate10 : 141|2@0+ (1.0000000000,0.0000000000) [0.0000000000|3.0000000000] "-"  FLR_L,mADC
 SG_ FLR_FreespaceSectorConfidence10 : 143|2@0+ (1.0000000000,0.0000000000) [0.0000000000|3.0000000000] "-"  FLR_L,mADC
 SG_ FLR_FreespaceSectorDistance10 : 121|10@0+ (0.1000000000,0.0000000000) [0.0000000000|100.0000000000] "-"  FLR_L,mADC
 SG_ FLR_FreespaceSectorKinestate9 : 123|2@0+ (1.0000000000,0.0000000000) [0.0000000000|3.0000000000] "-"  FLR_L,mADC
 SG_ FLR_FreespaceSectorConfidence9 : 125|2@0+ (1.0000000000,0.0000000000) [0.0000000000|3.0000000000] "-"  FLR_L,mADC
 SG_ FLR_FreespaceSectorDistance9 : 119|10@0+ (0.1000000000,0.0000000000) [0.0000000000|100.0000000000] "-"  FLR_L,mADC
 SG_ FLR_FreespaceSectorKinestate8 : 105|2@0+ (1.0000000000,0.0000000000) [0.0000000000|3.0000000000] "-"  FLR_L,mADC
 SG_ FLR_FreespaceSectorConfidence8 : 107|2@0+ (1.0000000000,0.0000000000) [0.0000000000|3.0000000000] "-"  FLR_L,mADC
 SG_ FLR_FreespaceSectorDistance8 : 101|10@0+ (0.1000000000,0.0000000000) [0.0000000000|100.0000000000] "-"  FLR_L,mADC
 SG_ FLR_FreespaceSectorKinestate7 : 103|2@0+ (1.0000000000,0.0000000000) [0.0000000000|3.0000000000] "-"  FLR_L,mADC
 SG_ FLR_FreespaceSectorConfidence7 : 89|2@0+ (1.0000000000,0.0000000000) [0.0000000000|3.0000000000] "-"  FLR_L,mADC
 SG_ FLR_FreespaceSectorDistance7 : 83|10@0+ (0.1000000000,0.0000000000) [0.0000000000|100.0000000000] "-"  FLR_L,mADC
 SG_ FLR_FreespaceSectorKinestate6 : 85|2@0+ (1.0000000000,0.0000000000) [0.0000000000|3.0000000000] "-"  FLR_L,mADC
 SG_ FLR_FreespaceSectorConfidence6 : 87|2@0+ (1.0000000000,0.0000000000) [0.0000000000|3.0000000000] "-"  FLR_L,mADC
 SG_ FLR_FreespaceSectorDistance6 : 65|10@0+ (0.1000000000,0.0000000000) [0.0000000000|100.0000000000] "-"  FLR_L,mADC
 SG_ FLR_FreespaceSectorKinestate5 : 67|2@0+ (1.0000000000,0.0000000000) [0.0000000000|3.0000000000] "-"  FLR_L,mADC
 SG_ FLR_FreespaceSectorConfidence5 : 69|2@0+ (1.0000000000,0.0000000000) [0.0000000000|3.0000000000] "-"  FLR_L,mADC
 SG_ FLR_FreespaceSectorDistance5 : 63|10@0+ (0.1000000000,0.0000000000) [0.0000000000|100.0000000000] "-"  FLR_L,mADC
 SG_ FLR_FreespaceSectorKinestate4 : 49|2@0+ (1.0000000000,0.0000000000) [0.0000000000|3.0000000000] "-"  FLR_L,mADC
 SG_ FLR_FreespaceSectorConfidence4 : 51|2@0+ (1.0000000000,0.0000000000) [0.0000000000|3.0000000000] "-"  FLR_L,mADC
 SG_ FLR_FreespaceSectorDistance4 : 45|10@0+ (0.1000000000,0.0000000000) [0.0000000000|100.0000000000] "-"  FLR_L,mADC
 SG_ FLR_FreespaceSectorKinestate3 : 47|2@0+ (1.0000000000,0.0000000000) [0.0000000000|3.0000000000] "-"  FLR_L,mADC
 SG_ FLR_FreespaceSectorConfidence3 : 33|2@0+ (1.0000000000,0.0000000000) [0.0000000000|3.0000000000] "-"  FLR_L,mADC
 SG_ FLR_FreespaceSectorDistance3 : 27|10@0+ (0.1000000000,0.0000000000) [0.0000000000|100.0000000000] "-"  FLR_L,mADC
 SG_ FLR_FreespaceSectorKinestate2 : 29|2@0+ (1.0000000000,0.0000000000) [0.0000000000|3.0000000000] "-"  FLR_L,mADC
 SG_ FLR_FreespaceSectorConfidence2 : 31|2@0+ (1.0000000000,0.0000000000) [0.0000000000|3.0000000000] "-"  FLR_L,mADC
 SG_ FLR_FreespaceSectorDistance2 : 9|10@0+ (0.1000000000,0.0000000000) [0.0000000000|100.0000000000] "-"  FLR_L,mADC
 SG_ FLR_FreespaceSectorKinestate1 : 11|2@0+ (1.0000000000,0.0000000000) [0.0000000000|3.0000000000] "-"  FLR_L,mADC
 SG_ FLR_FreespaceSectorConfidence1 : 13|2@0+ (1.0000000000,0.0000000000) [0.0000000000|3.0000000000] "-"  FLR_L,mADC
 SG_ FLR_FreespaceSectorDistance1 : 7|10@0+ (0.1000000000,0.0000000000) [0.0000000000|100.0000000000] "-"  FLR_L,mADC

BO_ 667 FRR_L_29B: 64 FRR_L
 SG_ FLR_CRCCheck_29B : 503|16@0+ (1.0000000000,0.0000000000) [0.0000000000|65535.0000000000] ""  FLR_L,mADC
 SG_ FLR_RollingCounter_29B : 491|4@0+ (1.0000000000,0.0000000000) [0.0000000000|15.0000000000] ""  FLR_L,mADC
 SG_ FLR_FreespaceSectorKinestate68 : 477|2@0+ (1.0000000000,0.0000000000) [0.0000000000|3.0000000000] "-"  FLR_L,mADC
 SG_ FLR_FreespaceSectorConfidence68 : 479|2@0+ (1.0000000000,0.0000000000) [0.0000000000|3.0000000000] "-"  FLR_L,mADC
 SG_ FLR_FreespaceSectorDistance68 : 457|10@0+ (0.1000000000,0.0000000000) [0.0000000000|100.0000000000] "-"  FLR_L,mADC
 SG_ FLR_FreespaceSectorKinestate67 : 459|2@0+ (1.0000000000,0.0000000000) [0.0000000000|3.0000000000] "-"  FLR_L,mADC
 SG_ FLR_FreespaceSectorConfidence67 : 461|2@0+ (1.0000000000,0.0000000000) [0.0000000000|3.0000000000] "-"  FLR_L,mADC
 SG_ FLR_FreespaceSectorDistance67 : 455|10@0+ (0.1000000000,0.0000000000) [0.0000000000|100.0000000000] "-"  FLR_L,mADC
 SG_ FLR_FreespaceSectorKinestate66 : 441|2@0+ (1.0000000000,0.0000000000) [0.0000000000|3.0000000000] "-"  FLR_L,mADC
 SG_ FLR_FreespaceSectorConfidence66 : 443|2@0+ (1.0000000000,0.0000000000) [0.0000000000|3.0000000000] "-"  FLR_L,mADC
 SG_ FLR_FreespaceSectorDistance66 : 437|10@0+ (0.1000000000,0.0000000000) [0.0000000000|100.0000000000] "-"  FLR_L,mADC
 SG_ FLR_FreespaceSectorKinestate65 : 439|2@0+ (1.0000000000,0.0000000000) [0.0000000000|3.0000000000] "-"  FLR_L,mADC
 SG_ FLR_FreespaceSectorConfidence65 : 425|2@0+ (1.0000000000,0.0000000000) [0.0000000000|3.0000000000] "-"  FLR_L,mADC
 SG_ FLR_FreespaceSectorDistance65 : 419|10@0+ (0.1000000000,0.0000000000) [0.0000000000|100.0000000000] "-"  FLR_L,mADC
 SG_ FLR_FreespaceSectorKinestate64 : 421|2@0+ (1.0000000000,0.0000000000) [0.0000000000|3.0000000000] "-"  FLR_L,mADC
 SG_ FLR_FreespaceSectorConfidence64 : 423|2@0+ (1.0000000000,0.0000000000) [0.0000000000|3.0000000000] "-"  FLR_L,mADC
 SG_ FLR_FreespaceSectorDistance64 : 401|10@0+ (0.1000000000,0.0000000000) [0.0000000000|100.0000000000] "-"  FLR_L,mADC
 SG_ FLR_FreespaceSectorKinestate63 : 403|2@0+ (1.0000000000,0.0000000000) [0.0000000000|3.0000000000] "-"  FLR_L,mADC
 SG_ FLR_FreespaceSectorConfidence63 : 405|2@0+ (1.0000000000,0.0000000000) [0.0000000000|3.0000000000] "-"  FLR_L,mADC
 SG_ FLR_FreespaceSectorDistance63 : 399|10@0+ (0.1000000000,0.0000000000) [0.0000000000|100.0000000000] "-"  FLR_L,mADC
 SG_ FLR_FreespaceSectorKinestate62 : 385|2@0+ (1.0000000000,0.0000000000) [0.0000000000|3.0000000000] "-"  FLR_L,mADC
 SG_ FLR_FreespaceSectorConfidence62 : 387|2@0+ (1.0000000000,0.0000000000) [0.0000000000|3.0000000000] "-"  FLR_L,mADC
 SG_ FLR_FreespaceSectorDistance62 : 381|10@0+ (0.1000000000,0.0000000000) [0.0000000000|100.0000000000] "-"  FLR_L,mADC
 SG_ FLR_FreespaceSectorKinestate61 : 383|2@0+ (1.0000000000,0.0000000000) [0.0000000000|3.0000000000] "-"  FLR_L,mADC
 SG_ FLR_FreespaceSectorConfidence61 : 369|2@0+ (1.0000000000,0.0000000000) [0.0000000000|3.0000000000] "-"  FLR_L,mADC
 SG_ FLR_FreespaceSectorDistance61 : 363|10@0+ (0.1000000000,0.0000000000) [0.0000000000|100.0000000000] "-"  FLR_L,mADC
 SG_ FLR_FreespaceSectorKinestate60 : 365|2@0+ (1.0000000000,0.0000000000) [0.0000000000|3.0000000000] "-"  FLR_L,mADC
 SG_ FLR_FreespaceSectorConfidence60 : 367|2@0+ (1.0000000000,0.0000000000) [0.0000000000|3.0000000000] "-"  FLR_L,mADC
 SG_ FLR_FreespaceSectorDistance60 : 345|10@0+ (0.1000000000,0.0000000000) [0.0000000000|100.0000000000] "-"  FLR_L,mADC
 SG_ FLR_FreespaceSectorKinestate59 : 347|2@0+ (1.0000000000,0.0000000000) [0.0000000000|3.0000000000] "-"  FLR_L,mADC
 SG_ FLR_FreespaceSectorConfidence59 : 349|2@0+ (1.0000000000,0.0000000000) [0.0000000000|3.0000000000] "-"  FLR_L,mADC
 SG_ FLR_FreespaceSectorDistance59 : 343|10@0+ (0.1000000000,0.0000000000) [0.0000000000|100.0000000000] "-"  FLR_L,mADC
 SG_ FLR_FreespaceSectorKinestate58 : 329|2@0+ (1.0000000000,0.0000000000) [0.0000000000|3.0000000000] "-"  FLR_L,mADC
 SG_ FLR_FreespaceSectorConfidence58 : 331|2@0+ (1.0000000000,0.0000000000) [0.0000000000|3.0000000000] "-"  FLR_L,mADC
 SG_ FLR_FreespaceSectorDistance58 : 325|10@0+ (0.1000000000,0.0000000000) [0.0000000000|100.0000000000] "-"  FLR_L,mADC
 SG_ FLR_FreespaceSectorKinestate57 : 327|2@0+ (1.0000000000,0.0000000000) [0.0000000000|3.0000000000] "-"  FLR_L,mADC
 SG_ FLR_FreespaceSectorConfidence57 : 313|2@0+ (1.0000000000,0.0000000000) [0.0000000000|3.0000000000] "-"  FLR_L,mADC
 SG_ FLR_FreespaceSectorDistance57 : 307|10@0+ (0.1000000000,0.0000000000) [0.0000000000|100.0000000000] "-"  FLR_L,mADC
 SG_ FLR_FreespaceSectorKinestate56 : 309|2@0+ (1.0000000000,0.0000000000) [0.0000000000|3.0000000000] "-"  FLR_L,mADC
 SG_ FLR_FreespaceSectorConfidence56 : 311|2@0+ (1.0000000000,0.0000000000) [0.0000000000|3.0000000000] "-"  FLR_L,mADC
 SG_ FLR_FreespaceSectorDistance56 : 289|10@0+ (0.1000000000,0.0000000000) [0.0000000000|100.0000000000] "-"  FLR_L,mADC
 SG_ FLR_FreespaceSectorKinestate55 : 291|2@0+ (1.0000000000,0.0000000000) [0.0000000000|3.0000000000] "-"  FLR_L,mADC
 SG_ FLR_FreespaceSectorConfidence55 : 293|2@0+ (1.0000000000,0.0000000000) [0.0000000000|3.0000000000] "-"  FLR_L,mADC
 SG_ FLR_FreespaceSectorDistance55 : 287|10@0+ (0.1000000000,0.0000000000) [0.0000000000|100.0000000000] "-"  FLR_L,mADC
 SG_ FLR_FreespaceSectorKinestate54 : 273|2@0+ (1.0000000000,0.0000000000) [0.0000000000|3.0000000000] "-"  FLR_L,mADC
 SG_ FLR_FreespaceSectorConfidence54 : 275|2@0+ (1.0000000000,0.0000000000) [0.0000000000|3.0000000000] "-"  FLR_L,mADC
 SG_ FLR_FreespaceSectorDistance54 : 269|10@0+ (0.1000000000,0.0000000000) [0.0000000000|100.0000000000] "-"  FLR_L,mADC
 SG_ FLR_FreespaceSectorKinestate53 : 271|2@0+ (1.0000000000,0.0000000000) [0.0000000000|3.0000000000] "-"  FLR_L,mADC
 SG_ FLR_FreespaceSectorConfidence53 : 257|2@0+ (1.0000000000,0.0000000000) [0.0000000000|3.0000000000] "-"  FLR_L,mADC
 SG_ FLR_FreespaceSectorDistance53 : 251|10@0+ (0.1000000000,0.0000000000) [0.0000000000|100.0000000000] "-"  FLR_L,mADC
 SG_ FLR_FreespaceSectorKinestate52 : 253|2@0+ (1.0000000000,0.0000000000) [0.0000000000|3.0000000000] "-"  FLR_L,mADC
 SG_ FLR_FreespaceSectorConfidence52 : 255|2@0+ (1.0000000000,0.0000000000) [0.0000000000|3.0000000000] "-"  FLR_L,mADC
 SG_ FLR_FreespaceSectorDistance52 : 233|10@0+ (0.1000000000,0.0000000000) [0.0000000000|100.0000000000] "-"  FLR_L,mADC
 SG_ FLR_FreespaceSectorKinestate51 : 235|2@0+ (1.0000000000,0.0000000000) [0.0000000000|3.0000000000] "-"  FLR_L,mADC
 SG_ FLR_FreespaceSectorConfidence51 : 237|2@0+ (1.0000000000,0.0000000000) [0.0000000000|3.0000000000] "-"  FLR_L,mADC
 SG_ FLR_FreespaceSectorDistance51 : 231|10@0+ (0.1000000000,0.0000000000) [0.0000000000|100.0000000000] "-"  FLR_L,mADC
 SG_ FLR_FreespaceSectorKinestate50 : 217|2@0+ (1.0000000000,0.0000000000) [0.0000000000|3.0000000000] "-"  FLR_L,mADC
 SG_ FLR_FreespaceSectorConfidence50 : 219|2@0+ (1.0000000000,0.0000000000) [0.0000000000|3.0000000000] "-"  FLR_L,mADC
 SG_ FLR_FreespaceSectorDistance50 : 213|10@0+ (0.1000000000,0.0000000000) [0.0000000000|100.0000000000] "-"  FLR_L,mADC
 SG_ FLR_FreespaceSectorKinestate49 : 215|2@0+ (1.0000000000,0.0000000000) [0.0000000000|3.0000000000] "-"  FLR_L,mADC
 SG_ FLR_FreespaceSectorConfidence49 : 201|2@0+ (1.0000000000,0.0000000000) [0.0000000000|3.0000000000] "-"  FLR_L,mADC
 SG_ FLR_FreespaceSectorDistance49 : 195|10@0+ (0.1000000000,0.0000000000) [0.0000000000|100.0000000000] "-"  FLR_L,mADC
 SG_ FLR_FreespaceSectorKinestate48 : 197|2@0+ (1.0000000000,0.0000000000) [0.0000000000|3.0000000000] "-"  FLR_L,mADC
 SG_ FLR_FreespaceSectorConfidence48 : 199|2@0+ (1.0000000000,0.0000000000) [0.0000000000|3.0000000000] "-"  FLR_L,mADC
 SG_ FLR_FreespaceSectorDistance48 : 177|10@0+ (0.1000000000,0.0000000000) [0.0000000000|100.0000000000] "-"  FLR_L,mADC
 SG_ FLR_FreespaceSectorKinestate47 : 179|2@0+ (1.0000000000,0.0000000000) [0.0000000000|3.0000000000] "-"  FLR_L,mADC
 SG_ FLR_FreespaceSectorConfidence47 : 181|2@0+ (1.0000000000,0.0000000000) [0.0000000000|3.0000000000] "-"  FLR_L,mADC
 SG_ FLR_FreespaceSectorDistance47 : 175|10@0+ (0.1000000000,0.0000000000) [0.0000000000|100.0000000000] "-"  FLR_L,mADC
 SG_ FLR_FreespaceSectorKinestate46 : 161|2@0+ (1.0000000000,0.0000000000) [0.0000000000|3.0000000000] "-"  FLR_L,mADC
 SG_ FLR_FreespaceSectorConfidence46 : 163|2@0+ (1.0000000000,0.0000000000) [0.0000000000|3.0000000000] "-"  FLR_L,mADC
 SG_ FLR_FreespaceSectorDistance46 : 157|10@0+ (0.1000000000,0.0000000000) [0.0000000000|100.0000000000] "-"  FLR_L,mADC
 SG_ FLR_FreespaceSectorKinestate45 : 159|2@0+ (1.0000000000,0.0000000000) [0.0000000000|3.0000000000] "-"  FLR_L,mADC
 SG_ FLR_FreespaceSectorConfidence45 : 145|2@0+ (1.0000000000,0.0000000000) [0.0000000000|3.0000000000] "-"  FLR_L,mADC
 SG_ FLR_FreespaceSectorDistance45 : 139|10@0+ (0.1000000000,0.0000000000) [0.0000000000|100.0000000000] "-"  FLR_L,mADC
 SG_ FLR_FreespaceSectorKinestate44 : 141|2@0+ (1.0000000000,0.0000000000) [0.0000000000|3.0000000000] "-"  FLR_L,mADC
 SG_ FLR_FreespaceSectorConfidence44 : 143|2@0+ (1.0000000000,0.0000000000) [0.0000000000|3.0000000000] "-"  FLR_L,mADC
 SG_ FLR_FreespaceSectorDistance44 : 121|10@0+ (0.1000000000,0.0000000000) [0.0000000000|100.0000000000] "-"  FLR_L,mADC
 SG_ FLR_FreespaceSectorKinestate43 : 123|2@0+ (1.0000000000,0.0000000000) [0.0000000000|3.0000000000] "-"  FLR_L,mADC
 SG_ FLR_FreespaceSectorConfidence43 : 125|2@0+ (1.0000000000,0.0000000000) [0.0000000000|3.0000000000] "-"  FLR_L,mADC
 SG_ FLR_FreespaceSectorDistance43 : 119|10@0+ (0.1000000000,0.0000000000) [0.0000000000|100.0000000000] "-"  FLR_L,mADC
 SG_ FLR_FreespaceSectorKinestate42 : 105|2@0+ (1.0000000000,0.0000000000) [0.0000000000|3.0000000000] "-"  FLR_L,mADC
 SG_ FLR_FreespaceSectorConfidence42 : 107|2@0+ (1.0000000000,0.0000000000) [0.0000000000|3.0000000000] "-"  FLR_L,mADC
 SG_ FLR_FreespaceSectorDistance42 : 101|10@0+ (0.1000000000,0.0000000000) [0.0000000000|100.0000000000] "-"  FLR_L,mADC
 SG_ FLR_FreespaceSectorKinestate41 : 103|2@0+ (1.0000000000,0.0000000000) [0.0000000000|3.0000000000] "-"  FLR_L,mADC
 SG_ FLR_FreespaceSectorConfidence41 : 89|2@0+ (1.0000000000,0.0000000000) [0.0000000000|3.0000000000] "-"  FLR_L,mADC
 SG_ FLR_FreespaceSectorDistance41 : 83|10@0+ (0.1000000000,0.0000000000) [0.0000000000|100.0000000000] "-"  FLR_L,mADC
 SG_ FLR_FreespaceSectorKinestate40 : 85|2@0+ (1.0000000000,0.0000000000) [0.0000000000|3.0000000000] "-"  FLR_L,mADC
 SG_ FLR_FreespaceSectorConfidence40 : 87|2@0+ (1.0000000000,0.0000000000) [0.0000000000|3.0000000000] "-"  FLR_L,mADC
 SG_ FLR_FreespaceSectorDistance40 : 65|10@0+ (0.1000000000,0.0000000000) [0.0000000000|100.0000000000] "-"  FLR_L,mADC
 SG_ FLR_FreespaceSectorKinestate39 : 67|2@0+ (1.0000000000,0.0000000000) [0.0000000000|3.0000000000] "-"  FLR_L,mADC
 SG_ FLR_FreespaceSectorConfidence39 : 69|2@0+ (1.0000000000,0.0000000000) [0.0000000000|3.0000000000] "-"  FLR_L,mADC
 SG_ FLR_FreespaceSectorDistance39 : 63|10@0+ (0.1000000000,0.0000000000) [0.0000000000|100.0000000000] "-"  FLR_L,mADC
 SG_ FLR_FreespaceSectorKinestate38 : 49|2@0+ (1.0000000000,0.0000000000) [0.0000000000|3.0000000000] "-"  FLR_L,mADC
 SG_ FLR_FreespaceSectorConfidence38 : 51|2@0+ (1.0000000000,0.0000000000) [0.0000000000|3.0000000000] "-"  FLR_L,mADC
 SG_ FLR_FreespaceSectorDistance38 : 45|10@0+ (0.1000000000,0.0000000000) [0.0000000000|100.0000000000] "-"  FLR_L,mADC
 SG_ FLR_FreespaceSectorKinestate37 : 47|2@0+ (1.0000000000,0.0000000000) [0.0000000000|3.0000000000] "-"  FLR_L,mADC
 SG_ FLR_FreespaceSectorConfidence37 : 33|2@0+ (1.0000000000,0.0000000000) [0.0000000000|3.0000000000] "-"  FLR_L,mADC
 SG_ FLR_FreespaceSectorDistance37 : 27|10@0+ (0.1000000000,0.0000000000) [0.0000000000|100.0000000000] "-"  FLR_L,mADC
 SG_ FLR_FreespaceSectorKinestate36 : 29|2@0+ (1.0000000000,0.0000000000) [0.0000000000|3.0000000000] "-"  FLR_L,mADC
 SG_ FLR_FreespaceSectorConfidence36 : 31|2@0+ (1.0000000000,0.0000000000) [0.0000000000|3.0000000000] "-"  FLR_L,mADC
 SG_ FLR_FreespaceSectorDistance36 : 9|10@0+ (0.1000000000,0.0000000000) [0.0000000000|100.0000000000] "-"  FLR_L,mADC
 SG_ FLR_FreespaceSectorKinestate35 : 11|2@0+ (1.0000000000,0.0000000000) [0.0000000000|3.0000000000] "-"  FLR_L,mADC
 SG_ FLR_FreespaceSectorConfidence35 : 13|2@0+ (1.0000000000,0.0000000000) [0.0000000000|3.0000000000] "-"  FLR_L,mADC
 SG_ FLR_FreespaceSectorDistance35 : 7|10@0+ (0.1000000000,0.0000000000) [0.0000000000|100.0000000000] "-"  FLR_L,mADC

BO_ 668 FRR_L_29C: 64 FRR_L
 SG_ FLR_CRCCheck_29C : 503|16@0+ (1.0000000000,0.0000000000) [0.0000000000|65535.0000000000] ""  FLR_L,mADC
 SG_ FLR_RollingCounter_29C : 491|4@0+ (1.0000000000,0.0000000000) [0.0000000000|15.0000000000] ""  FLR_L,mADC
 SG_ FLR_FreespaceSectorKinestate102 : 477|2@0+ (1.0000000000,0.0000000000) [0.0000000000|3.0000000000] "-"  FLR_L,mADC
 SG_ FLR_FreespaceSectorConfidence102 : 479|2@0+ (1.0000000000,0.0000000000) [0.0000000000|3.0000000000] "-"  FLR_L,mADC
 SG_ FLR_FreespaceSectorDistance102 : 457|10@0+ (0.1000000000,0.0000000000) [0.0000000000|100.0000000000] "-"  FLR_L,mADC
 SG_ FLR_FreespaceSectorKinestate101 : 459|2@0+ (1.0000000000,0.0000000000) [0.0000000000|3.0000000000] "-"  FLR_L,mADC
 SG_ FLR_FreespaceSectorConfidence101 : 461|2@0+ (1.0000000000,0.0000000000) [0.0000000000|3.0000000000] "-"  FLR_L,mADC
 SG_ FLR_FreespaceSectorDistance101 : 455|10@0+ (0.1000000000,0.0000000000) [0.0000000000|100.0000000000] "-"  FLR_L,mADC
 SG_ FLR_FreespaceSectorKinestate100 : 441|2@0+ (1.0000000000,0.0000000000) [0.0000000000|3.0000000000] "-"  FLR_L,mADC
 SG_ FLR_FreespaceSectorConfidence100 : 443|2@0+ (1.0000000000,0.0000000000) [0.0000000000|3.0000000000] "-"  FLR_L,mADC
 SG_ FLR_FreespaceSectorDistance100 : 437|10@0+ (0.1000000000,0.0000000000) [0.0000000000|100.0000000000] "-"  FLR_L,mADC
 SG_ FLR_FreespaceSectorKinestate99 : 439|2@0+ (1.0000000000,0.0000000000) [0.0000000000|3.0000000000] "-"  FLR_L,mADC
 SG_ FLR_FreespaceSectorConfidence99 : 425|2@0+ (1.0000000000,0.0000000000) [0.0000000000|3.0000000000] "-"  FLR_L,mADC
 SG_ FLR_FreespaceSectorDistance99 : 419|10@0+ (0.1000000000,0.0000000000) [0.0000000000|100.0000000000] "-"  FLR_L,mADC
 SG_ FLR_FreespaceSectorKinestate98 : 421|2@0+ (1.0000000000,0.0000000000) [0.0000000000|3.0000000000] "-"  FLR_L,mADC
 SG_ FLR_FreespaceSectorConfidence98 : 423|2@0+ (1.0000000000,0.0000000000) [0.0000000000|3.0000000000] "-"  FLR_L,mADC
 SG_ FLR_FreespaceSectorDistance98 : 401|10@0+ (0.1000000000,0.0000000000) [0.0000000000|100.0000000000] "-"  FLR_L,mADC
 SG_ FLR_FreespaceSectorKinestate97 : 403|2@0+ (1.0000000000,0.0000000000) [0.0000000000|3.0000000000] "-"  FLR_L,mADC
 SG_ FLR_FreespaceSectorConfidence97 : 405|2@0+ (1.0000000000,0.0000000000) [0.0000000000|3.0000000000] "-"  FLR_L,mADC
 SG_ FLR_FreespaceSectorDistance97 : 399|10@0+ (0.1000000000,0.0000000000) [0.0000000000|100.0000000000] "-"  FLR_L,mADC
 SG_ FLR_FreespaceSectorKinestate96 : 385|2@0+ (1.0000000000,0.0000000000) [0.0000000000|3.0000000000] "-"  FLR_L,mADC
 SG_ FLR_FreespaceSectorConfidence96 : 387|2@0+ (1.0000000000,0.0000000000) [0.0000000000|3.0000000000] "-"  FLR_L,mADC
 SG_ FLR_FreespaceSectorDistance96 : 381|10@0+ (0.1000000000,0.0000000000) [0.0000000000|100.0000000000] "-"  FLR_L,mADC
 SG_ FLR_FreespaceSectorKinestate95 : 383|2@0+ (1.0000000000,0.0000000000) [0.0000000000|3.0000000000] "-"  FLR_L,mADC
 SG_ FLR_FreespaceSectorConfidence95 : 369|2@0+ (1.0000000000,0.0000000000) [0.0000000000|3.0000000000] "-"  FLR_L,mADC
 SG_ FLR_FreespaceSectorDistance95 : 363|10@0+ (0.1000000000,0.0000000000) [0.0000000000|100.0000000000] "-"  FLR_L,mADC
 SG_ FLR_FreespaceSectorKinestate94 : 365|2@0+ (1.0000000000,0.0000000000) [0.0000000000|3.0000000000] "-"  FLR_L,mADC
 SG_ FLR_FreespaceSectorConfidence94 : 367|2@0+ (1.0000000000,0.0000000000) [0.0000000000|3.0000000000] "-"  FLR_L,mADC
 SG_ FLR_FreespaceSectorDistance94 : 345|10@0+ (0.1000000000,0.0000000000) [0.0000000000|100.0000000000] "-"  FLR_L,mADC
 SG_ FLR_FreespaceSectorKinestate93 : 347|2@0+ (1.0000000000,0.0000000000) [0.0000000000|3.0000000000] "-"  FLR_L,mADC
 SG_ FLR_FreespaceSectorConfidence93 : 349|2@0+ (1.0000000000,0.0000000000) [0.0000000000|3.0000000000] "-"  FLR_L,mADC
 SG_ FLR_FreespaceSectorDistance93 : 343|10@0+ (0.1000000000,0.0000000000) [0.0000000000|100.0000000000] "-"  FLR_L,mADC
 SG_ FLR_FreespaceSectorKinestate92 : 329|2@0+ (1.0000000000,0.0000000000) [0.0000000000|3.0000000000] "-"  FLR_L,mADC
 SG_ FLR_FreespaceSectorConfidence92 : 331|2@0+ (1.0000000000,0.0000000000) [0.0000000000|3.0000000000] "-"  FLR_L,mADC
 SG_ FLR_FreespaceSectorDistance92 : 325|10@0+ (0.1000000000,0.0000000000) [0.0000000000|100.0000000000] "-"  FLR_L,mADC
 SG_ FLR_FreespaceSectorKinestate91 : 327|2@0+ (1.0000000000,0.0000000000) [0.0000000000|3.0000000000] "-"  FLR_L,mADC
 SG_ FLR_FreespaceSectorConfidence91 : 313|2@0+ (1.0000000000,0.0000000000) [0.0000000000|3.0000000000] "-"  FLR_L,mADC
 SG_ FLR_FreespaceSectorDistance91 : 307|10@0+ (0.1000000000,0.0000000000) [0.0000000000|100.0000000000] "-"  FLR_L,mADC
 SG_ FLR_FreespaceSectorKinestate90 : 309|2@0+ (1.0000000000,0.0000000000) [0.0000000000|3.0000000000] "-"  FLR_L,mADC
 SG_ FLR_FreespaceSectorConfidence90 : 311|2@0+ (1.0000000000,0.0000000000) [0.0000000000|3.0000000000] "-"  FLR_L,mADC
 SG_ FLR_FreespaceSectorDistance90 : 289|10@0+ (0.1000000000,0.0000000000) [0.0000000000|100.0000000000] "-"  FLR_L,mADC
 SG_ FLR_FreespaceSectorKinestate89 : 291|2@0+ (1.0000000000,0.0000000000) [0.0000000000|3.0000000000] "-"  FLR_L,mADC
 SG_ FLR_FreespaceSectorConfidence89 : 293|2@0+ (1.0000000000,0.0000000000) [0.0000000000|3.0000000000] "-"  FLR_L,mADC
 SG_ FLR_FreespaceSectorDistance89 : 287|10@0+ (0.1000000000,0.0000000000) [0.0000000000|100.0000000000] "-"  FLR_L,mADC
 SG_ FLR_FreespaceSectorKinestate88 : 273|2@0+ (1.0000000000,0.0000000000) [0.0000000000|3.0000000000] "-"  FLR_L,mADC
 SG_ FLR_FreespaceSectorConfidence88 : 275|2@0+ (1.0000000000,0.0000000000) [0.0000000000|3.0000000000] "-"  FLR_L,mADC
 SG_ FLR_FreespaceSectorDistance88 : 269|10@0+ (0.1000000000,0.0000000000) [0.0000000000|100.0000000000] "-"  FLR_L,mADC
 SG_ FLR_FreespaceSectorKinestate87 : 271|2@0+ (1.0000000000,0.0000000000) [0.0000000000|3.0000000000] "-"  FLR_L,mADC
 SG_ FLR_FreespaceSectorConfidence87 : 257|2@0+ (1.0000000000,0.0000000000) [0.0000000000|3.0000000000] "-"  FLR_L,mADC
 SG_ FLR_FreespaceSectorDistance87 : 251|10@0+ (0.1000000000,0.0000000000) [0.0000000000|100.0000000000] "-"  FLR_L,mADC
 SG_ FLR_FreespaceSectorKinestate86 : 253|2@0+ (1.0000000000,0.0000000000) [0.0000000000|3.0000000000] "-"  FLR_L,mADC
 SG_ FLR_FreespaceSectorConfidence86 : 255|2@0+ (1.0000000000,0.0000000000) [0.0000000000|3.0000000000] "-"  FLR_L,mADC
 SG_ FLR_FreespaceSectorDistance86 : 233|10@0+ (0.1000000000,0.0000000000) [0.0000000000|100.0000000000] "-"  FLR_L,mADC
 SG_ FLR_FreespaceSectorKinestate85 : 235|2@0+ (1.0000000000,0.0000000000) [0.0000000000|3.0000000000] "-"  FLR_L,mADC
 SG_ FLR_FreespaceSectorConfidence85 : 237|2@0+ (1.0000000000,0.0000000000) [0.0000000000|3.0000000000] "-"  FLR_L,mADC
 SG_ FLR_FreespaceSectorDistance85 : 231|10@0+ (0.1000000000,0.0000000000) [0.0000000000|100.0000000000] "-"  FLR_L,mADC
 SG_ FLR_FreespaceSectorKinestate84 : 217|2@0+ (1.0000000000,0.0000000000) [0.0000000000|3.0000000000] "-"  FLR_L,mADC
 SG_ FLR_FreespaceSectorConfidence84 : 219|2@0+ (1.0000000000,0.0000000000) [0.0000000000|3.0000000000] "-"  FLR_L,mADC
 SG_ FLR_FreespaceSectorDistance84 : 213|10@0+ (0.1000000000,0.0000000000) [0.0000000000|100.0000000000] "-"  FLR_L,mADC
 SG_ FLR_FreespaceSectorKinestate83 : 215|2@0+ (1.0000000000,0.0000000000) [0.0000000000|3.0000000000] "-"  FLR_L,mADC
 SG_ FLR_FreespaceSectorConfidence83 : 201|2@0+ (1.0000000000,0.0000000000) [0.0000000000|3.0000000000] "-"  FLR_L,mADC
 SG_ FLR_FreespaceSectorDistance83 : 195|10@0+ (0.1000000000,0.0000000000) [0.0000000000|100.0000000000] "-"  FLR_L,mADC
 SG_ FLR_FreespaceSectorKinestate82 : 197|2@0+ (1.0000000000,0.0000000000) [0.0000000000|3.0000000000] "-"  FLR_L,mADC
 SG_ FLR_FreespaceSectorConfidence82 : 199|2@0+ (1.0000000000,0.0000000000) [0.0000000000|3.0000000000] "-"  FLR_L,mADC
 SG_ FLR_FreespaceSectorDistance82 : 177|10@0+ (0.1000000000,0.0000000000) [0.0000000000|100.0000000000] "-"  FLR_L,mADC
 SG_ FLR_FreespaceSectorKinestate81 : 179|2@0+ (1.0000000000,0.0000000000) [0.0000000000|3.0000000000] "-"  FLR_L,mADC
 SG_ FLR_FreespaceSectorConfidence81 : 181|2@0+ (1.0000000000,0.0000000000) [0.0000000000|3.0000000000] "-"  FLR_L,mADC
 SG_ FLR_FreespaceSectorDistance81 : 175|10@0+ (0.1000000000,0.0000000000) [0.0000000000|100.0000000000] "-"  FLR_L,mADC
 SG_ FLR_FreespaceSectorKinestate80 : 161|2@0+ (1.0000000000,0.0000000000) [0.0000000000|3.0000000000] "-"  FLR_L,mADC
 SG_ FLR_FreespaceSectorConfidence80 : 163|2@0+ (1.0000000000,0.0000000000) [0.0000000000|3.0000000000] "-"  FLR_L,mADC
 SG_ FLR_FreespaceSectorDistance80 : 157|10@0+ (0.1000000000,0.0000000000) [0.0000000000|100.0000000000] "-"  FLR_L,mADC
 SG_ FLR_FreespaceSectorKinestate79 : 159|2@0+ (1.0000000000,0.0000000000) [0.0000000000|3.0000000000] "-"  FLR_L,mADC
 SG_ FLR_FreespaceSectorConfidence79 : 145|2@0+ (1.0000000000,0.0000000000) [0.0000000000|3.0000000000] "-"  FLR_L,mADC
 SG_ FLR_FreespaceSectorDistance79 : 139|10@0+ (0.1000000000,0.0000000000) [0.0000000000|100.0000000000] "-"  FLR_L,mADC
 SG_ FLR_FreespaceSectorKinestate78 : 141|2@0+ (1.0000000000,0.0000000000) [0.0000000000|3.0000000000] "-"  FLR_L,mADC
 SG_ FLR_FreespaceSectorConfidence78 : 143|2@0+ (1.0000000000,0.0000000000) [0.0000000000|3.0000000000] "-"  FLR_L,mADC
 SG_ FLR_FreespaceSectorDistance78 : 121|10@0+ (0.1000000000,0.0000000000) [0.0000000000|100.0000000000] "-"  FLR_L,mADC
 SG_ FLR_FreespaceSectorKinestate77 : 123|2@0+ (1.0000000000,0.0000000000) [0.0000000000|3.0000000000] "-"  FLR_L,mADC
 SG_ FLR_FreespaceSectorConfidence77 : 125|2@0+ (1.0000000000,0.0000000000) [0.0000000000|3.0000000000] "-"  FLR_L,mADC
 SG_ FLR_FreespaceSectorDistance77 : 119|10@0+ (0.1000000000,0.0000000000) [0.0000000000|100.0000000000] "-"  FLR_L,mADC
 SG_ FLR_FreespaceSectorKinestate76 : 105|2@0+ (1.0000000000,0.0000000000) [0.0000000000|3.0000000000] "-"  FLR_L,mADC
 SG_ FLR_FreespaceSectorConfidence76 : 107|2@0+ (1.0000000000,0.0000000000) [0.0000000000|3.0000000000] "-"  FLR_L,mADC
 SG_ FLR_FreespaceSectorDistance76 : 101|10@0+ (0.1000000000,0.0000000000) [0.0000000000|100.0000000000] "-"  FLR_L,mADC
 SG_ FLR_FreespaceSectorKinestate75 : 103|2@0+ (1.0000000000,0.0000000000) [0.0000000000|3.0000000000] "-"  FLR_L,mADC
 SG_ FLR_FreespaceSectorConfidence75 : 89|2@0+ (1.0000000000,0.0000000000) [0.0000000000|3.0000000000] "-"  FLR_L,mADC
 SG_ FLR_FreespaceSectorDistance75 : 83|10@0+ (0.1000000000,0.0000000000) [0.0000000000|100.0000000000] "-"  FLR_L,mADC
 SG_ FLR_FreespaceSectorKinestate74 : 85|2@0+ (1.0000000000,0.0000000000) [0.0000000000|3.0000000000] "-"  FLR_L,mADC
 SG_ FLR_FreespaceSectorConfidence74 : 87|2@0+ (1.0000000000,0.0000000000) [0.0000000000|3.0000000000] "-"  FLR_L,mADC
 SG_ FLR_FreespaceSectorDistance74 : 65|10@0+ (0.1000000000,0.0000000000) [0.0000000000|100.0000000000] "-"  FLR_L,mADC
 SG_ FLR_FreespaceSectorKinestate73 : 67|2@0+ (1.0000000000,0.0000000000) [0.0000000000|3.0000000000] "-"  FLR_L,mADC
 SG_ FLR_FreespaceSectorConfidence73 : 69|2@0+ (1.0000000000,0.0000000000) [0.0000000000|3.0000000000] "-"  FLR_L,mADC
 SG_ FLR_FreespaceSectorDistance73 : 63|10@0+ (0.1000000000,0.0000000000) [0.0000000000|100.0000000000] "-"  FLR_L,mADC
 SG_ FLR_FreespaceSectorKinestate72 : 49|2@0+ (1.0000000000,0.0000000000) [0.0000000000|3.0000000000] "-"  FLR_L,mADC
 SG_ FLR_FreespaceSectorConfidence72 : 51|2@0+ (1.0000000000,0.0000000000) [0.0000000000|3.0000000000] "-"  FLR_L,mADC
 SG_ FLR_FreespaceSectorDistance72 : 45|10@0+ (0.1000000000,0.0000000000) [0.0000000000|100.0000000000] "-"  FLR_L,mADC
 SG_ FLR_FreespaceSectorKinestate71 : 47|2@0+ (1.0000000000,0.0000000000) [0.0000000000|3.0000000000] "-"  FLR_L,mADC
 SG_ FLR_FreespaceSectorConfidence71 : 33|2@0+ (1.0000000000,0.0000000000) [0.0000000000|3.0000000000] "-"  FLR_L,mADC
 SG_ FLR_FreespaceSectorDistance71 : 27|10@0+ (0.1000000000,0.0000000000) [0.0000000000|100.0000000000] "-"  FLR_L,mADC
 SG_ FLR_FreespaceSectorKinestate70 : 29|2@0+ (1.0000000000,0.0000000000) [0.0000000000|3.0000000000] "-"  FLR_L,mADC
 SG_ FLR_FreespaceSectorConfidence70 : 31|2@0+ (1.0000000000,0.0000000000) [0.0000000000|3.0000000000] "-"  FLR_L,mADC
 SG_ FLR_FreespaceSectorDistance70 : 9|10@0+ (0.1000000000,0.0000000000) [0.0000000000|100.0000000000] "-"  FLR_L,mADC
 SG_ FLR_FreespaceSectorKinestate69 : 11|2@0+ (1.0000000000,0.0000000000) [0.0000000000|3.0000000000] "-"  FLR_L,mADC
 SG_ FLR_FreespaceSectorConfidence69 : 13|2@0+ (1.0000000000,0.0000000000) [0.0000000000|3.0000000000] "-"  FLR_L,mADC
 SG_ FLR_FreespaceSectorDistance69 : 7|10@0+ (0.1000000000,0.0000000000) [0.0000000000|100.0000000000] "-"  FLR_L,mADC

CM_ BO_ 604  " ";
CM_ SG_ 604 FLR_OBJ26_LostCnt  " ";
CM_ SG_ 604 FLR_OBJ25_LostCnt  " ";
CM_ SG_ 604 FLR_OBJ26_Dx  " ";
CM_ SG_ 604 FLR_OBJ26_Dy  " ";
CM_ SG_ 604 FLR_OBJ25_Dx  " ";
CM_ SG_ 604 FLR_OBJ25_Dy  " ";
CM_ SG_ 604 FLR_OBJ26_Vx  " ";
CM_ SG_ 604 FLR_OBJ26_Vy  " ";
CM_ SG_ 604 FLR_OBJ26_Convergence  " ";
CM_ SG_ 604 FLR_OBJ26_DelayTime  " ";
CM_ SG_ 604 FLR_OBJ26_HeightGround  " ";
CM_ SG_ 604 FLR_OBJ26_MotionStatus  " ";
CM_ SG_ 604 FLR_OBJ26_RelVx_std  " ";
CM_ SG_ 604 FLR_OBJ26_RelVy_std  " ";
CM_ SG_ 604 FLR_OBJ26_Dx_Vnce  " ";
CM_ SG_ 604 FLR_OBJ26_Dy_Vnce  " ";
CM_ SG_ 604 FLR_OBJ25_Vx  " ";
CM_ SG_ 604 FLR_OBJ25_Vy  " ";
CM_ SG_ 604 FLR_OBJ25_Convergence  " ";
CM_ SG_ 604 FLR_OBJ25_DelayTime  " ";
CM_ SG_ 604 FLR_OBJ25_HeightGround  " ";
CM_ SG_ 604 FLR_OBJ25_MotionStatus  " ";
CM_ SG_ 604 FLR_OBJ25_RelVx_std  " ";
CM_ SG_ 604 FLR_OBJ25_RelVy_std  " ";
CM_ SG_ 604 FLR_OBJ25_Dx_Vnce  " ";
CM_ SG_ 604 FLR_OBJ25_Dy_Vnce  " ";
CM_ SG_ 604 FLR_CRCCheck_25C  " ";
CM_ SG_ 604 FLR_RollingCounter_25C  " ";
CM_ SG_ 604 FLR_OBJ26_Track_Age  " ";
CM_ SG_ 604 FLR_OBJ26_RefPointLoc  " ";
CM_ SG_ 604 FLR_OBJ26_ObstacleProb  " ";
CM_ SG_ 604 FLR_OBJ26_Measured  " ";
CM_ SG_ 604 FLR_OBJ26_ExistProb  " ";
CM_ SG_ 604 FLR_OBJ26_Location  " ";
CM_ SG_ 604 FLR_OBJ26_RelAx  " ";
CM_ SG_ 604 FLR_OBJ26_RelAy  " ";
CM_ SG_ 604 FLR_OBJ26_RelVx  " ";
CM_ SG_ 604 FLR_OBJ26_RelVy  " ";
CM_ SG_ 604 FLR_OBJ26_HeadingAngle  " ";
CM_ SG_ 604 FLR_OBJ26_Length  " ";
CM_ SG_ 604 FLR_OBJ26_Height  " ";
CM_ SG_ 604 FLR_OBJ26_Width  " ";
CM_ SG_ 604 FLR_OBJ26_Type  " ";
CM_ SG_ 604 FLR_OBJ26_Track_ID  " ";
CM_ SG_ 604 FLR_OBJ25_Track_Age  " ";
CM_ SG_ 604 FLR_OBJ25_RefPointLoc  " ";
CM_ SG_ 604 FLR_OBJ25_ObstacleProb  " ";
CM_ SG_ 604 FLR_OBJ25_Measured  " ";
CM_ SG_ 604 FLR_OBJ25_ExistProb  " ";
CM_ SG_ 604 FLR_OBJ25_Location  " ";
CM_ SG_ 604 FLR_OBJ25_RelAx  " ";
CM_ SG_ 604 FLR_OBJ25_RelAy  " ";
CM_ SG_ 604 FLR_OBJ25_RelVx  " ";
CM_ SG_ 604 FLR_OBJ25_RelVy  " ";
CM_ SG_ 604 FLR_OBJ25_HeadingAngle  " ";
CM_ SG_ 604 FLR_OBJ25_Length  " ";
CM_ SG_ 604 FLR_OBJ25_Height  " ";
CM_ SG_ 604 FLR_OBJ25_Width  " ";
CM_ SG_ 604 FLR_OBJ25_Type  " ";
CM_ SG_ 604 FLR_OBJ25_Track_ID  " ";

CM_ BO_ 605  " ";
CM_ SG_ 605 FLR_OBJ28_LostCnt  " ";
CM_ SG_ 605 FLR_OBJ27_LostCnt  " ";
CM_ SG_ 605 FLR_OBJ28_Dx  " ";
CM_ SG_ 605 FLR_OBJ28_Dy  " ";
CM_ SG_ 605 FLR_OBJ27_Dx  " ";
CM_ SG_ 605 FLR_OBJ27_Dy  " ";
CM_ SG_ 605 FLR_OBJ28_Vx  " ";
CM_ SG_ 605 FLR_OBJ28_Vy  " ";
CM_ SG_ 605 FLR_OBJ28_Convergence  " ";
CM_ SG_ 605 FLR_OBJ28_DelayTime  " ";
CM_ SG_ 605 FLR_OBJ28_HeightGround  " ";
CM_ SG_ 605 FLR_OBJ28_MotionStatus  " ";
CM_ SG_ 605 FLR_OBJ28_RelVx_std  " ";
CM_ SG_ 605 FLR_OBJ28_RelVy_std  " ";
CM_ SG_ 605 FLR_OBJ28_Dx_Vnce  " ";
CM_ SG_ 605 FLR_OBJ28_Dy_Vnce  " ";
CM_ SG_ 605 FLR_OBJ27_Vx  " ";
CM_ SG_ 605 FLR_OBJ27_Vy  " ";
CM_ SG_ 605 FLR_OBJ27_Convergence  " ";
CM_ SG_ 605 FLR_OBJ27_DelayTime  " ";
CM_ SG_ 605 FLR_OBJ27_HeightGround  " ";
CM_ SG_ 605 FLR_OBJ27_MotionStatus  " ";
CM_ SG_ 605 FLR_OBJ27_RelVx_std  " ";
CM_ SG_ 605 FLR_OBJ27_RelVy_std  " ";
CM_ SG_ 605 FLR_OBJ27_Dx_Vnce  " ";
CM_ SG_ 605 FLR_OBJ27_Dy_Vnce  " ";
CM_ SG_ 605 FLR_CRCCheck_25D  " ";
CM_ SG_ 605 FLR_RollingCounter_25D  " ";
CM_ SG_ 605 FLR_OBJ28_Track_Age  " ";
CM_ SG_ 605 FLR_OBJ28_RefPointLoc  " ";
CM_ SG_ 605 FLR_OBJ28_ObstacleProb  " ";
CM_ SG_ 605 FLR_OBJ28_Measured  " ";
CM_ SG_ 605 FLR_OBJ28_ExistProb  " ";
CM_ SG_ 605 FLR_OBJ28_Location  " ";
CM_ SG_ 605 FLR_OBJ28_RelAx  " ";
CM_ SG_ 605 FLR_OBJ28_RelAy  " ";
CM_ SG_ 605 FLR_OBJ28_RelVx  " ";
CM_ SG_ 605 FLR_OBJ28_RelVy  " ";
CM_ SG_ 605 FLR_OBJ28_HeadingAngle  " ";
CM_ SG_ 605 FLR_OBJ28_Length  " ";
CM_ SG_ 605 FLR_OBJ28_Height  " ";
CM_ SG_ 605 FLR_OBJ28_Width  " ";
CM_ SG_ 605 FLR_OBJ28_Type  " ";
CM_ SG_ 605 FLR_OBJ28_Track_ID  " ";
CM_ SG_ 605 FLR_OBJ27_Track_Age  " ";
CM_ SG_ 605 FLR_OBJ27_RefPointLoc  " ";
CM_ SG_ 605 FLR_OBJ27_ObstacleProb  " ";
CM_ SG_ 605 FLR_OBJ27_Measured  " ";
CM_ SG_ 605 FLR_OBJ27_ExistProb  " ";
CM_ SG_ 605 FLR_OBJ27_Location  " ";
CM_ SG_ 605 FLR_OBJ27_RelAx  " ";
CM_ SG_ 605 FLR_OBJ27_RelAy  " ";
CM_ SG_ 605 FLR_OBJ27_RelVx  " ";
CM_ SG_ 605 FLR_OBJ27_RelVy  " ";
CM_ SG_ 605 FLR_OBJ27_HeadingAngle  " ";
CM_ SG_ 605 FLR_OBJ27_Length  " ";
CM_ SG_ 605 FLR_OBJ27_Height  " ";
CM_ SG_ 605 FLR_OBJ27_Width  " ";
CM_ SG_ 605 FLR_OBJ27_Type  " ";
CM_ SG_ 605 FLR_OBJ27_Track_ID  " ";

CM_ BO_ 606  " ";
CM_ SG_ 606 FLR_OBJ30_LostCnt  " ";
CM_ SG_ 606 FLR_OBJ29_LostCnt  " ";
CM_ SG_ 606 FLR_OBJ30_Dx  " ";
CM_ SG_ 606 FLR_OBJ30_Dy  " ";
CM_ SG_ 606 FLR_OBJ29_Dx  " ";
CM_ SG_ 606 FLR_OBJ29_Dy  " ";
CM_ SG_ 606 FLR_OBJ30_Vx  " ";
CM_ SG_ 606 FLR_OBJ30_Vy  " ";
CM_ SG_ 606 FLR_OBJ30_Convergence  " ";
CM_ SG_ 606 FLR_OBJ30_DelayTime  " ";
CM_ SG_ 606 FLR_OBJ30_HeightGround  " ";
CM_ SG_ 606 FLR_OBJ30_MotionStatus  " ";
CM_ SG_ 606 FLR_OBJ30_RelVx_std  " ";
CM_ SG_ 606 FLR_OBJ30_RelVy_std  " ";
CM_ SG_ 606 FLR_OBJ30_Dx_Vnce  " ";
CM_ SG_ 606 FLR_OBJ30_Dy_Vnce  " ";
CM_ SG_ 606 FLR_OBJ29_Vx  " ";
CM_ SG_ 606 FLR_OBJ29_Vy  " ";
CM_ SG_ 606 FLR_OBJ29_Convergence  " ";
CM_ SG_ 606 FLR_OBJ29_DelayTime  " ";
CM_ SG_ 606 FLR_OBJ29_HeightGround  " ";
CM_ SG_ 606 FLR_OBJ29_MotionStatus  " ";
CM_ SG_ 606 FLR_OBJ29_RelVx_std  " ";
CM_ SG_ 606 FLR_OBJ29_RelVy_std  " ";
CM_ SG_ 606 FLR_OBJ29_Dx_Vnce  " ";
CM_ SG_ 606 FLR_OBJ29_Dy_Vnce  " ";
CM_ SG_ 606 FLR_CRCCheck_25E  " ";
CM_ SG_ 606 FLR_RollingCounter_25E  " ";
CM_ SG_ 606 FLR_OBJ30_Track_Age  " ";
CM_ SG_ 606 FLR_OBJ30_RefPointLoc  " ";
CM_ SG_ 606 FLR_OBJ30_ObstacleProb  " ";
CM_ SG_ 606 FLR_OBJ30_Measured  " ";
CM_ SG_ 606 FLR_OBJ30_ExistProb  " ";
CM_ SG_ 606 FLR_OBJ30_Location  " ";
CM_ SG_ 606 FLR_OBJ30_RelAx  " ";
CM_ SG_ 606 FLR_OBJ30_RelAy  " ";
CM_ SG_ 606 FLR_OBJ30_RelVx  " ";
CM_ SG_ 606 FLR_OBJ30_RelVy  " ";
CM_ SG_ 606 FLR_OBJ30_HeadingAngle  " ";
CM_ SG_ 606 FLR_OBJ30_Length  " ";
CM_ SG_ 606 FLR_OBJ30_Height  " ";
CM_ SG_ 606 FLR_OBJ30_Width  " ";
CM_ SG_ 606 FLR_OBJ30_Type  " ";
CM_ SG_ 606 FLR_OBJ30_Track_ID  " ";
CM_ SG_ 606 FLR_OBJ29_Track_Age  " ";
CM_ SG_ 606 FLR_OBJ29_RefPointLoc  " ";
CM_ SG_ 606 FLR_OBJ29_ObstacleProb  " ";
CM_ SG_ 606 FLR_OBJ29_Measured  " ";
CM_ SG_ 606 FLR_OBJ29_ExistProb  " ";
CM_ SG_ 606 FLR_OBJ29_Location  " ";
CM_ SG_ 606 FLR_OBJ29_RelAx  " ";
CM_ SG_ 606 FLR_OBJ29_RelAy  " ";
CM_ SG_ 606 FLR_OBJ29_RelVx  " ";
CM_ SG_ 606 FLR_OBJ29_RelVy  " ";
CM_ SG_ 606 FLR_OBJ29_HeadingAngle  " ";
CM_ SG_ 606 FLR_OBJ29_Length  " ";
CM_ SG_ 606 FLR_OBJ29_Height  " ";
CM_ SG_ 606 FLR_OBJ29_Width  " ";
CM_ SG_ 606 FLR_OBJ29_Type  " ";
CM_ SG_ 606 FLR_OBJ29_Track_ID  " ";

CM_ BO_ 607  " ";
CM_ SG_ 607 FLR_OBJ32_LostCnt  " ";
CM_ SG_ 607 FLR_OBJ31_LostCnt  " ";
CM_ SG_ 607 FLR_OBJ32_Dx  " ";
CM_ SG_ 607 FLR_OBJ32_Dy  " ";
CM_ SG_ 607 FLR_OBJ31_Dx  " ";
CM_ SG_ 607 FLR_OBJ31_Dy  " ";
CM_ SG_ 607 FLR_OBJ32_Vx  " ";
CM_ SG_ 607 FLR_OBJ32_Vy  " ";
CM_ SG_ 607 FLR_OBJ32_Convergence  " ";
CM_ SG_ 607 FLR_OBJ32_DelayTime  " ";
CM_ SG_ 607 FLR_OBJ32_HeightGround  " ";
CM_ SG_ 607 FLR_OBJ32_MotionStatus  " ";
CM_ SG_ 607 FLR_OBJ32_RelVx_std  " ";
CM_ SG_ 607 FLR_OBJ32_RelVy_std  " ";
CM_ SG_ 607 FLR_OBJ32_Dx_Vnce  " ";
CM_ SG_ 607 FLR_OBJ32_Dy_Vnce  " ";
CM_ SG_ 607 FLR_OBJ31_Vx  " ";
CM_ SG_ 607 FLR_OBJ31_Vy  " ";
CM_ SG_ 607 FLR_OBJ31_Convergence  " ";
CM_ SG_ 607 FLR_OBJ31_DelayTime  " ";
CM_ SG_ 607 FLR_OBJ31_HeightGround  " ";
CM_ SG_ 607 FLR_OBJ31_MotionStatus  " ";
CM_ SG_ 607 FLR_OBJ31_RelVx_std  " ";
CM_ SG_ 607 FLR_OBJ31_RelVy_std  " ";
CM_ SG_ 607 FLR_OBJ31_Dx_Vnce  " ";
CM_ SG_ 607 FLR_OBJ31_Dy_Vnce  " ";
CM_ SG_ 607 FLR_CRCCheck_25F  " ";
CM_ SG_ 607 FLR_RollingCounter_25F  " ";
CM_ SG_ 607 FLR_OBJ32_Track_Age  " ";
CM_ SG_ 607 FLR_OBJ32_RefPointLoc  " ";
CM_ SG_ 607 FLR_OBJ32_ObstacleProb  " ";
CM_ SG_ 607 FLR_OBJ32_Measured  " ";
CM_ SG_ 607 FLR_OBJ32_ExistProb  " ";
CM_ SG_ 607 FLR_OBJ32_Location  " ";
CM_ SG_ 607 FLR_OBJ32_RelAx  " ";
CM_ SG_ 607 FLR_OBJ32_RelAy  " ";
CM_ SG_ 607 FLR_OBJ32_RelVx  " ";
CM_ SG_ 607 FLR_OBJ32_RelVy  " ";
CM_ SG_ 607 FLR_OBJ32_HeadingAngle  " ";
CM_ SG_ 607 FLR_OBJ32_Length  " ";
CM_ SG_ 607 FLR_OBJ32_Height  " ";
CM_ SG_ 607 FLR_OBJ32_Width  " ";
CM_ SG_ 607 FLR_OBJ32_Type  " ";
CM_ SG_ 607 FLR_OBJ32_Track_ID  " ";
CM_ SG_ 607 FLR_OBJ31_Track_Age  " ";
CM_ SG_ 607 FLR_OBJ31_RefPointLoc  " ";
CM_ SG_ 607 FLR_OBJ31_ObstacleProb  " ";
CM_ SG_ 607 FLR_OBJ31_Measured  " ";
CM_ SG_ 607 FLR_OBJ31_ExistProb  " ";
CM_ SG_ 607 FLR_OBJ31_Location  " ";
CM_ SG_ 607 FLR_OBJ31_RelAx  " ";
CM_ SG_ 607 FLR_OBJ31_RelAy  " ";
CM_ SG_ 607 FLR_OBJ31_RelVx  " ";
CM_ SG_ 607 FLR_OBJ31_RelVy  " ";
CM_ SG_ 607 FLR_OBJ31_HeadingAngle  " ";
CM_ SG_ 607 FLR_OBJ31_Length  " ";
CM_ SG_ 607 FLR_OBJ31_Height  " ";
CM_ SG_ 607 FLR_OBJ31_Width  " ";
CM_ SG_ 607 FLR_OBJ31_Type  " ";
CM_ SG_ 607 FLR_OBJ31_Track_ID  " ";

CM_ BO_ 642  "╫є╟░└╫┤я128╕Ў╡у╘╞
╫є╟░└╫┤я╩ф│Ў╫є╙╥╗д└╕ ";
CM_ SG_ 642 FRGuardrailReadyFlag  " ";
CM_ SG_ 642 FLGuardrailReadyFlag  " ";
CM_ SG_ 642 FLR_CRCCheck_282  " ";
CM_ SG_ 642 FLR_RollingCounter_282  " ";
CM_ SG_ 642 FLR_FrontRightGuardrailConfidenc  " ";
CM_ SG_ 642 FLR__FronRightGuardrail_End  " ";
CM_ SG_ 642 FLR__FronRightGuardrail_Start  " ";
CM_ SG_ 642 FLR_FrontRightGuardrailC3  " ";
CM_ SG_ 642 FLR_FrontRightGuardrailC2  " ";
CM_ SG_ 642 FLR_FrontRightGuardrailC1  " ";
CM_ SG_ 642 FLR_FrontRightGuardrailC0  " ";
CM_ SG_ 642 FLR_FrontLeftGuardrailConfidence  " ";
CM_ SG_ 642 FLR__FrontLeftGuardrail_End  " ";
CM_ SG_ 642 FLR__FrontLeftGuardrail_Start  " ";
CM_ SG_ 642 FLR_FrontLeftGuardrailC3  " ";
CM_ SG_ 642 FLR_FrontLeftGuardrailC2  " ";
CM_ SG_ 642 FLR_FrontLeftGuardrailC1  " ";
CM_ SG_ 642 FLR_FrontLeftGuardrailC0  " ";
CM_ SG_ 642 FLR_LocHeader_RollingCounter  " ";

CM_ BO_ 687  " ";
CM_ SG_ 687 FRR_HwVers6  "ASCII┬ыгм├№├√╣ц╘Є░┤╒╒б╢QJDT037-2019╞√│╡▓·╞╖┴у▓┐╝■╝■║┼║═├√│╞▒р╓╞╣ц╖╢б╖ ";
CM_ SG_ 687 FRR_HwVers5  "ASCII┬ыгм├№├√╣ц╘Є░┤╒╒б╢QJDT037-2019╞√│╡▓·╞╖┴у▓┐╝■╝■║┼║═├√│╞▒р╓╞╣ц╖╢б╖ ";
CM_ SG_ 687 FRR_HwVers4  "ASCII┬ыгм├№├√╣ц╘Є░┤╒╒б╢QJDT037-2019╞√│╡▓·╞╖┴у▓┐╝■╝■║┼║═├√│╞▒р╓╞╣ц╖╢б╖ ";
CM_ SG_ 687 FRR_HwVers3  "ASCII┬ыгм├№├√╣ц╘Є░┤╒╒б╢QJDT037-2019╞√│╡▓·╞╖┴у▓┐╝■╝■║┼║═├√│╞▒р╓╞╣ц╖╢б╖ ";
CM_ SG_ 687 FRR_HwVers2  "ASCII┬ыгм├№├√╣ц╘Є░┤╒╒б╢QJDT037-2019╞√│╡▓·╞╖┴у▓┐╝■╝■║┼║═├√│╞▒р╓╞╣ц╖╢б╖ ";
CM_ SG_ 687 FRR_HwVers1  "ASCII┬ыгм├№├√╣ц╘Є░┤╒╒б╢QJDT037-2019╞√│╡▓·╞╖┴у▓┐╝■╝■║┼║═├√│╞▒р╓╞╣ц╖╢б╖ ";
CM_ SG_ 687 FRR_HwVers0  "ASCII┬ыгм├№├√╣ц╘Є░┤╒╒б╢QJDT037-2019╞√│╡▓·╞╖┴у▓┐╝■╝■║┼║═├√│╞▒р╓╞╣ц╖╢б╖ ";
CM_ SG_ 687 FRR_SwVers6  "ASCII┬ыгм├№├√╣ц╘Є░┤╒╒б╢QJDT037-2019╞√│╡▓·╞╖┴у▓┐╝■╝■║┼║═├√│╞▒р╓╞╣ц╖╢б╖ ";
CM_ SG_ 687 FRR_SwVers5  "ASCII┬ыгм├№├√╣ц╘Є░┤╒╒б╢QJDT037-2019╞√│╡▓·╞╖┴у▓┐╝■╝■║┼║═├√│╞▒р╓╞╣ц╖╢б╖ ";
CM_ SG_ 687 FRR_SwVers4  "ASCII┬ыгм├№├√╣ц╘Є░┤╒╒б╢QJDT037-2019╞√│╡▓·╞╖┴у▓┐╝■╝■║┼║═├√│╞▒р╓╞╣ц╖╢б╖ ";
CM_ SG_ 687 FRR_SwVers3  "ASCII┬ыгм├№├√╣ц╘Є░┤╒╒б╢QJDT037-2019╞√│╡▓·╞╖┴у▓┐╝■╝■║┼║═├√│╞▒р╓╞╣ц╖╢б╖ ";
CM_ SG_ 687 FRR_SwVers2  "ASCII┬ыгм├№├√╣ц╘Є░┤╒╒б╢QJDT037-2019╞√│╡▓·╞╖┴у▓┐╝■╝■║┼║═├√│╞▒р╓╞╣ц╖╢б╖ ";
CM_ SG_ 687 FRR_SwVers1  "ASCII┬ыгм├№├√╣ц╘Є░┤╒╒б╢QJDT037-2019╞√│╡▓·╞╖┴у▓┐╝■╝■║┼║═├√│╞▒р╓╞╣ц╖╢б╖ ";
CM_ SG_ 687 FRR_SwVers0  "ASCII┬ыгм├№├√╣ц╘Є░┤╒╒б╢QJDT037-2019╞√│╡▓·╞╖┴у▓┐╝■╝■║┼║═├√│╞▒р╓╞╣ц╖╢б╖ ";
CM_ SG_ 687 FLR_HwVers6  "ASCII┬ыгм├№├√╣ц╘Є░┤╒╒б╢QJDT037-2019╞√│╡▓·╞╖┴у▓┐╝■╝■║┼║═├√│╞▒р╓╞╣ц╖╢б╖ ";
CM_ SG_ 687 FLR_HwVers5  "ASCII┬ыгм├№├√╣ц╘Є░┤╒╒б╢QJDT037-2019╞√│╡▓·╞╖┴у▓┐╝■╝■║┼║═├√│╞▒р╓╞╣ц╖╢б╖ ";
CM_ SG_ 687 FLR_HwVers4  "ASCII┬ыгм├№├√╣ц╘Є░┤╒╒б╢QJDT037-2019╞√│╡▓·╞╖┴у▓┐╝■╝■║┼║═├√│╞▒р╓╞╣ц╖╢б╖ ";
CM_ SG_ 687 FLR_HwVers3  "ASCII┬ыгм├№├√╣ц╘Є░┤╒╒б╢QJDT037-2019╞√│╡▓·╞╖┴у▓┐╝■╝■║┼║═├√│╞▒р╓╞╣ц╖╢б╖ ";
CM_ SG_ 687 FLR_HwVers2  "ASCII┬ыгм├№├√╣ц╘Є░┤╒╒б╢QJDT037-2019╞√│╡▓·╞╖┴у▓┐╝■╝■║┼║═├√│╞▒р╓╞╣ц╖╢б╖ ";
CM_ SG_ 687 FLR_HwVers1  "ASCII┬ыгм├№├√╣ц╘Є░┤╒╒б╢QJDT037-2019╞√│╡▓·╞╖┴у▓┐╝■╝■║┼║═├√│╞▒р╓╞╣ц╖╢б╖ ";
CM_ SG_ 687 FLR_HwVers0  "ASCII┬ыгм├№├√╣ц╘Є░┤╒╒б╢QJDT037-2019╞√│╡▓·╞╖┴у▓┐╝■╝■║┼║═├√│╞▒р╓╞╣ц╖╢б╖ ";
CM_ SG_ 687 FLR_SwVers6  "ASCII┬ыгм├№├√╣ц╘Є░┤╒╒б╢QJDT037-2019╞√│╡▓·╞╖┴у▓┐╝■╝■║┼║═├√│╞▒р╓╞╣ц╖╢б╖ ";
CM_ SG_ 687 FLR_SwVers5  "ASCII┬ыгм├№├√╣ц╘Є░┤╒╒б╢QJDT037-2019╞√│╡▓·╞╖┴у▓┐╝■╝■║┼║═├√│╞▒р╓╞╣ц╖╢б╖ ";
CM_ SG_ 687 FLR_SwVers4  "ASCII┬ыгм├№├√╣ц╘Є░┤╒╒б╢QJDT037-2019╞√│╡▓·╞╖┴у▓┐╝■╝■║┼║═├√│╞▒р╓╞╣ц╖╢б╖ ";
CM_ SG_ 687 FLR_SwVers3  "ASCII┬ыгм├№├√╣ц╘Є░┤╒╒б╢QJDT037-2019╞√│╡▓·╞╖┴у▓┐╝■╝■║┼║═├√│╞▒р╓╞╣ц╖╢б╖ ";
CM_ SG_ 687 FLR_SwVers2  "ASCII┬ыгм├№├√╣ц╘Є░┤╒╒б╢QJDT037-2019╞√│╡▓·╞╖┴у▓┐╝■╝■║┼║═├√│╞▒р╓╞╣ц╖╢б╖ ";
CM_ SG_ 687 FLR_SwVers1  "ASCII┬ыгм├№├√╣ц╘Є░┤╒╒б╢QJDT037-2019╞√│╡▓·╞╖┴у▓┐╝■╝■║┼║═├√│╞▒р╓╞╣ц╖╢б╖ ";
CM_ SG_ 687 FLR_SwVers0  "ASCII┬ыгм├№├√╣ц╘Є░┤╒╒б╢QJDT037-2019╞√│╡▓·╞╖┴у▓┐╝■╝■║┼║═├√│╞▒р╓╞╣ц╖╢б╖ ";

CM_ BO_ 690  " ";
CM_ SG_ 690 RLR_CRCCheck_2B2  " ";
CM_ SG_ 690 RLR_RollingCounter_2B2  " ";
CM_ SG_ 690 FuncDegradeType_FL  " ";
CM_ SG_ 690 FUSION_TimeoutCnt_FL  " ";
CM_ SG_ 690 VALIDATION_TimeoutCnt_FL  " ";
CM_ SG_ 690 CurFrameCycle_FL  " ";
CM_ SG_ 690 ProcessTimeoutCnt_FL  " ";
CM_ SG_ 690 RevFrameCnt_FL  " ";
CM_ SG_ 690 Local_Pointcloud_Number_FL  " ";
CM_ SG_ 690 RealTimeCal_PrcssBar_FL  " ";
CM_ SG_ 690 RealTimeCal_VelErrOutput_FL  " ";
CM_ SG_ 690 RealTimeCal_HoriMntErrOutput_FL  " ";
CM_ SG_ 690 RealTimeCal_FailReasonCode_FL  " ";
CM_ SG_ 690 RealTimeCal_Status_FL  " ";
CM_ SG_ 690 DiagCal_PrcssBar_FL  " ";
CM_ SG_ 690 DiagCal_VelErrOutput_FL  " ";
CM_ SG_ 690 DiagCal_HoriMntErrOutput_FL  " ";
CM_ SG_ 690 DiagCal_FailReasonCode_FL  " ";
CM_ SG_ 690 DiagCal_Status_FL  " ";
CM_ SG_ 690 EolCal_PrcssBar_FL  " ";
CM_ SG_ 690 EolCal_VelErrOutput_FL  " ";
CM_ SG_ 690 EolCal_HoriMntErrOutput_FL  " ";
CM_ SG_ 690 EolCal_FailReasonCode_FL  " ";
CM_ SG_ 690 EolCal_Status_FL  " ";
CM_ SG_ 690 PriCounter_FL  " ";
CM_ SG_ 690 MsgCounter_FL  " ";

CM_ BO_ 579  " ";
CM_ SG_ 579 Transmitcnt6_F  " ";
CM_ SG_ 579 Transmitcnt5_F  " ";
CM_ SG_ 579 Transmitcnt4_F  " ";
CM_ SG_ 579 Transmitcnt3_F  " ";
CM_ SG_ 579 Transmitcnt2_F  " ";
CM_ SG_ 579 Transmitcnt1_F  " ";
CM_ SG_ 579 FLR_Track_ID_R  " ";
CM_ SG_ 579 FLR_Measured_R  " ";
CM_ SG_ 579 FLR_Location_R  " ";
CM_ SG_ 579 FLR_ClassComfrmFlg_R  " ";
CM_ SG_ 579 FLR_TrckrType_R  " ";
CM_ SG_ 579 FLR_TrckrAge_R  " ";
CM_ SG_ 579 FLR_MotionStatus_R  " ";
CM_ SG_ 579 FLR_AbsVy_R  " ";
CM_ SG_ 579 FLR_AbsoVx_R  " ";
CM_ SG_ 579 FLR_LocDx_R  " ";
CM_ SG_ 579 FLR_LocDy_R  " ";
CM_ SG_ 579 FLR_HeadingAngle_R  " ";
CM_ SG_ 579 FLR_Length_R  " ";
CM_ SG_ 579 FLR_Width_R  " ";
CM_ SG_ 579 FLR_Track_ID_L  " ";
CM_ SG_ 579 FLR_Measured_L  " ";
CM_ SG_ 579 FLR_Location_L  " ";
CM_ SG_ 579 FLR_ClassComfrmFlg_L  " ";
CM_ SG_ 579 FLR_TrckrType_L  " ";
CM_ SG_ 579 FLR_TrckrAge_L  " ";
CM_ SG_ 579 FLR_MotionStatus_L  " ";
CM_ SG_ 579 FLR_AbsVy_L  " ";
CM_ SG_ 579 FLR_AbsoVx_L  " ";
CM_ SG_ 579 FLR_LocDx_L  " ";
CM_ SG_ 579 FLR_LocDy_L  " ";
CM_ SG_ 579 FLR_HeadingAngle_L  " ";
CM_ SG_ 579 FLR_Length_L  " ";
CM_ SG_ 579 FLR_Width_L  " ";
CM_ SG_ 579 FLR_TrckrNum  " ";
CM_ SG_ 579 FLR_TrackerTimeStamp  " ";

CM_ BO_ 589  " ";
CM_ SG_ 589 FRR_Right_FCTARAlert  " ";
CM_ SG_ 589 FRR_FCTBActive  " ";
CM_ SG_ 589 FRR_FCTBTargetDeceleration  " ";
CM_ SG_ 589 FRR_EmergencyLightingRequest  "╘д┴Ї ";
CM_ SG_ 589 FRR_FCTBVehilceHoldReq  " ";
CM_ SG_ 589 FRR_FCTBStatus  " ";
CM_ SG_ 589 FRR_FCTAStatus  " ";
CM_ SG_ 589 FRR_Left_FCTALAlert  " ";

CM_ BO_ 694  " ";
CM_ SG_ 694 RLR_CRCCheck_2B6  " ";
CM_ SG_ 694 RLR_RollingCounter_2B6  " ";
CM_ SG_ 694 FLR_OBJ32_lAy  " ";
CM_ SG_ 694 FLR_OBJ31_lAy  " ";
CM_ SG_ 694 FLR_OBJ30_lAy  " ";
CM_ SG_ 694 FLR_OBJ29_lAy  " ";
CM_ SG_ 694 FLR_OBJ28_lAy  " ";
CM_ SG_ 694 FLR_OBJ27_lAy  " ";
CM_ SG_ 694 FLR_OBJ26_lAy  " ";
CM_ SG_ 694 FLR_OBJ25_lAy  " ";
CM_ SG_ 694 FLR_OBJ24_lAy  " ";
CM_ SG_ 694 FLR_OBJ23_lAy  " ";
CM_ SG_ 694 FLR_OBJ22_lAy  " ";
CM_ SG_ 694 FLR_OBJ21_lAy  " ";
CM_ SG_ 694 FLR_OBJ20_lAy  " ";
CM_ SG_ 694 FLR_OBJ19_lAy  " ";
CM_ SG_ 694 FLR_OBJ18_lAy  " ";
CM_ SG_ 694 FLR_OBJ17_lAy  " ";
CM_ SG_ 694 FLR_OBJ16_lAy  " ";
CM_ SG_ 694 FLR_OBJ15_lAy  " ";
CM_ SG_ 694 FLR_OBJ14_lAy  " ";
CM_ SG_ 694 FLR_OBJ13_lAy  " ";
CM_ SG_ 694 FLR_OBJ12_lAy  " ";
CM_ SG_ 694 FLR_OBJ11_lAy  " ";
CM_ SG_ 694 FLR_OBJ10_lAy  " ";
CM_ SG_ 694 FLR_OBJ9_lAy  " ";
CM_ SG_ 694 FLR_OBJ8_lAy  " ";
CM_ SG_ 694 FLR_OBJ7_lAy  " ";
CM_ SG_ 694 FLR_OBJ6_lAy  " ";
CM_ SG_ 694 FLR_OBJ5_lAy  " ";
CM_ SG_ 694 FLR_OBJ4_lAy  " ";
CM_ SG_ 694 FLR_OBJ3_lAy  " ";
CM_ SG_ 694 FLR_OBJ2_lAy  " ";
CM_ SG_ 694 FLR_OBJ1_lAy  " ";

CM_ BO_ 585  " ";
CM_ SG_ 585 FRR_Suppliers  " ";
CM_ SG_ 585 FRR_FS_TiOut  " ";
CM_ SG_ 585 FRR_FS_TiLeap  " ";
CM_ SG_ 585 FRR_FS_TiBas  " ";
CM_ SG_ 585 FRR_FS_TiStamp  " ";
CM_ SG_ 585 FRR_CRCCheck_249  " ";
CM_ SG_ 585 FRR_RollingCounter_249  " ";
CM_ SG_ 585 FRR_ECU_TiOut  " ";
CM_ SG_ 585 FRR_ECU_TiLeap  " ";
CM_ SG_ 585 FRR_ECU_TiBas  " ";
CM_ SG_ 585 FRR_ECU_TiStamp  " ";
CM_ SG_ 585 FRR_MCUTiStamp  " ";
CM_ SG_ 585 FRR_SyncTiStamp  " ";
CM_ SG_ 585 FRR_WorkMode  " ";
CM_ SG_ 585 FRR_ObjDelay  " ";
CM_ SG_ 585 FRR_SystemStatus  " ";

CM_ BO_ 666  " ";
CM_ SG_ 666 FLR_CRCCheck_29A  " ";
CM_ SG_ 666 FLR_RollingCounter_29A  " ";
CM_ SG_ 666 FLR_FreespaceSectorKinestate34  " ";
CM_ SG_ 666 FLR_FreespaceSectorConfidence34  " ";
CM_ SG_ 666 FLR_FreespaceSectorDistance34  " ";
CM_ SG_ 666 FLR_FreespaceSectorKinestate33  " ";
CM_ SG_ 666 FLR_FreespaceSectorConfidence33  " ";
CM_ SG_ 666 FLR_FreespaceSectorDistance33  " ";
CM_ SG_ 666 FLR_FreespaceSectorKinestate32  " ";
CM_ SG_ 666 FLR_FreespaceSectorConfidence32  " ";
CM_ SG_ 666 FLR_FreespaceSectorDistance32  " ";
CM_ SG_ 666 FLR_FreespaceSectorKinestate31  " ";
CM_ SG_ 666 FLR_FreespaceSectorConfidence31  " ";
CM_ SG_ 666 FLR_FreespaceSectorDistance31  " ";
CM_ SG_ 666 FLR_FreespaceSectorKinestate30  " ";
CM_ SG_ 666 FLR_FreespaceSectorConfidence30  " ";
CM_ SG_ 666 FLR_FreespaceSectorDistance30  " ";
CM_ SG_ 666 FLR_FreespaceSectorKinestate29  " ";
CM_ SG_ 666 FLR_FreespaceSectorConfidence29  " ";
CM_ SG_ 666 FLR_FreespaceSectorDistance29  " ";
CM_ SG_ 666 FLR_FreespaceSectorKinestate28  " ";
CM_ SG_ 666 FLR_FreespaceSectorConfidence28  " ";
CM_ SG_ 666 FLR_FreespaceSectorDistance28  " ";
CM_ SG_ 666 FLR_FreespaceSectorKinestate27  " ";
CM_ SG_ 666 FLR_FreespaceSectorConfidence27  " ";
CM_ SG_ 666 FLR_FreespaceSectorDistance27  " ";
CM_ SG_ 666 FLR_FreespaceSectorKinestate26  " ";
CM_ SG_ 666 FLR_FreespaceSectorConfidence26  " ";
CM_ SG_ 666 FLR_FreespaceSectorDistance26  " ";
CM_ SG_ 666 FLR_FreespaceSectorKinestate25  " ";
CM_ SG_ 666 FLR_FreespaceSectorConfidence25  " ";
CM_ SG_ 666 FLR_FreespaceSectorDistance25  " ";
CM_ SG_ 666 FLR_FreespaceSectorKinestate24  " ";
CM_ SG_ 666 FLR_FreespaceSectorConfidence24  " ";
CM_ SG_ 666 FLR_FreespaceSectorDistance24  " ";
CM_ SG_ 666 FLR_FreespaceSectorKinestate23  " ";
CM_ SG_ 666 FLR_FreespaceSectorConfidence23  " ";
CM_ SG_ 666 FLR_FreespaceSectorDistance23  " ";
CM_ SG_ 666 FLR_FreespaceSectorKinestate22  " ";
CM_ SG_ 666 FLR_FreespaceSectorConfidence22  " ";
CM_ SG_ 666 FLR_FreespaceSectorDistance22  " ";
CM_ SG_ 666 FLR_FreespaceSectorKinestate21  " ";
CM_ SG_ 666 FLR_FreespaceSectorConfidence21  " ";
CM_ SG_ 666 FLR_FreespaceSectorDistance21  " ";
CM_ SG_ 666 FLR_FreespaceSectorKinestate20  " ";
CM_ SG_ 666 FLR_FreespaceSectorConfidence20  " ";
CM_ SG_ 666 FLR_FreespaceSectorDistance20  " ";
CM_ SG_ 666 FLR_FreespaceSectorKinestate19  " ";
CM_ SG_ 666 FLR_FreespaceSectorConfidence19  " ";
CM_ SG_ 666 FLR_FreespaceSectorDistance19  " ";
CM_ SG_ 666 FLR_FreespaceSectorKinestate18  " ";
CM_ SG_ 666 FLR_FreespaceSectorConfidence18  " ";
CM_ SG_ 666 FLR_FreespaceSectorDistance18  " ";
CM_ SG_ 666 FLR_FreespaceSectorKinestate17  " ";
CM_ SG_ 666 FLR_FreespaceSectorConfidence17  " ";
CM_ SG_ 666 FLR_FreespaceSectorDistance17  " ";
CM_ SG_ 666 FLR_FreespaceSectorKinestate16  " ";
CM_ SG_ 666 FLR_FreespaceSectorConfidence16  " ";
CM_ SG_ 666 FLR_FreespaceSectorDistance16  " ";
CM_ SG_ 666 FLR_FreespaceSectorKinestate15  " ";
CM_ SG_ 666 FLR_FreespaceSectorConfidence15  " ";
CM_ SG_ 666 FLR_FreespaceSectorDistance15  " ";
CM_ SG_ 666 FLR_FreespaceSectorKinestate14  " ";
CM_ SG_ 666 FLR_FreespaceSectorConfidence14  " ";
CM_ SG_ 666 FLR_FreespaceSectorDistance14  " ";
CM_ SG_ 666 FLR_FreespaceSectorKinestate13  " ";
CM_ SG_ 666 FLR_FreespaceSectorConfidence13  " ";
CM_ SG_ 666 FLR_FreespaceSectorDistance13  " ";
CM_ SG_ 666 FLR_FreespaceSectorKinestate12  " ";
CM_ SG_ 666 FLR_FreespaceSectorConfidence12  " ";
CM_ SG_ 666 FLR_FreespaceSectorDistance12  " ";
CM_ SG_ 666 FLR_FreespaceSectorKinestate11  " ";
CM_ SG_ 666 FLR_FreespaceSectorConfidence11  " ";
CM_ SG_ 666 FLR_FreespaceSectorDistance11  " ";
CM_ SG_ 666 FLR_FreespaceSectorKinestate10  " ";
CM_ SG_ 666 FLR_FreespaceSectorConfidence10  " ";
CM_ SG_ 666 FLR_FreespaceSectorDistance10  " ";
CM_ SG_ 666 FLR_FreespaceSectorKinestate9  " ";
CM_ SG_ 666 FLR_FreespaceSectorConfidence9  " ";
CM_ SG_ 666 FLR_FreespaceSectorDistance9  " ";
CM_ SG_ 666 FLR_FreespaceSectorKinestate8  " ";
CM_ SG_ 666 FLR_FreespaceSectorConfidence8  " ";
CM_ SG_ 666 FLR_FreespaceSectorDistance8  " ";
CM_ SG_ 666 FLR_FreespaceSectorKinestate7  " ";
CM_ SG_ 666 FLR_FreespaceSectorConfidence7  " ";
CM_ SG_ 666 FLR_FreespaceSectorDistance7  " ";
CM_ SG_ 666 FLR_FreespaceSectorKinestate6  " ";
CM_ SG_ 666 FLR_FreespaceSectorConfidence6  " ";
CM_ SG_ 666 FLR_FreespaceSectorDistance6  " ";
CM_ SG_ 666 FLR_FreespaceSectorKinestate5  " ";
CM_ SG_ 666 FLR_FreespaceSectorConfidence5  " ";
CM_ SG_ 666 FLR_FreespaceSectorDistance5  " ";
CM_ SG_ 666 FLR_FreespaceSectorKinestate4  " ";
CM_ SG_ 666 FLR_FreespaceSectorConfidence4  " ";
CM_ SG_ 666 FLR_FreespaceSectorDistance4  " ";
CM_ SG_ 666 FLR_FreespaceSectorKinestate3  " ";
CM_ SG_ 666 FLR_FreespaceSectorConfidence3  " ";
CM_ SG_ 666 FLR_FreespaceSectorDistance3  " ";
CM_ SG_ 666 FLR_FreespaceSectorKinestate2  " ";
CM_ SG_ 666 FLR_FreespaceSectorConfidence2  " ";
CM_ SG_ 666 FLR_FreespaceSectorDistance2  " ";
CM_ SG_ 666 FLR_FreespaceSectorKinestate1  " ";
CM_ SG_ 666 FLR_FreespaceSectorConfidence1  " ";
CM_ SG_ 666 FLR_FreespaceSectorDistance1  " ";

CM_ BO_ 667  " ";
CM_ SG_ 667 FLR_CRCCheck_29B  " ";
CM_ SG_ 667 FLR_RollingCounter_29B  " ";
CM_ SG_ 667 FLR_FreespaceSectorKinestate68  " ";
CM_ SG_ 667 FLR_FreespaceSectorConfidence68  " ";
CM_ SG_ 667 FLR_FreespaceSectorDistance68  " ";
CM_ SG_ 667 FLR_FreespaceSectorKinestate67  " ";
CM_ SG_ 667 FLR_FreespaceSectorConfidence67  " ";
CM_ SG_ 667 FLR_FreespaceSectorDistance67  " ";
CM_ SG_ 667 FLR_FreespaceSectorKinestate66  " ";
CM_ SG_ 667 FLR_FreespaceSectorConfidence66  " ";
CM_ SG_ 667 FLR_FreespaceSectorDistance66  " ";
CM_ SG_ 667 FLR_FreespaceSectorKinestate65  " ";
CM_ SG_ 667 FLR_FreespaceSectorConfidence65  " ";
CM_ SG_ 667 FLR_FreespaceSectorDistance65  " ";
CM_ SG_ 667 FLR_FreespaceSectorKinestate64  " ";
CM_ SG_ 667 FLR_FreespaceSectorConfidence64  " ";
CM_ SG_ 667 FLR_FreespaceSectorDistance64  " ";
CM_ SG_ 667 FLR_FreespaceSectorKinestate63  " ";
CM_ SG_ 667 FLR_FreespaceSectorConfidence63  " ";
CM_ SG_ 667 FLR_FreespaceSectorDistance63  " ";
CM_ SG_ 667 FLR_FreespaceSectorKinestate62  " ";
CM_ SG_ 667 FLR_FreespaceSectorConfidence62  " ";
CM_ SG_ 667 FLR_FreespaceSectorDistance62  " ";
CM_ SG_ 667 FLR_FreespaceSectorKinestate61  " ";
CM_ SG_ 667 FLR_FreespaceSectorConfidence61  " ";
CM_ SG_ 667 FLR_FreespaceSectorDistance61  " ";
CM_ SG_ 667 FLR_FreespaceSectorKinestate60  " ";
CM_ SG_ 667 FLR_FreespaceSectorConfidence60  " ";
CM_ SG_ 667 FLR_FreespaceSectorDistance60  " ";
CM_ SG_ 667 FLR_FreespaceSectorKinestate59  " ";
CM_ SG_ 667 FLR_FreespaceSectorConfidence59  " ";
CM_ SG_ 667 FLR_FreespaceSectorDistance59  " ";
CM_ SG_ 667 FLR_FreespaceSectorKinestate58  " ";
CM_ SG_ 667 FLR_FreespaceSectorConfidence58  " ";
CM_ SG_ 667 FLR_FreespaceSectorDistance58  " ";
CM_ SG_ 667 FLR_FreespaceSectorKinestate57  " ";
CM_ SG_ 667 FLR_FreespaceSectorConfidence57  " ";
CM_ SG_ 667 FLR_FreespaceSectorDistance57  " ";
CM_ SG_ 667 FLR_FreespaceSectorKinestate56  " ";
CM_ SG_ 667 FLR_FreespaceSectorConfidence56  " ";
CM_ SG_ 667 FLR_FreespaceSectorDistance56  " ";
CM_ SG_ 667 FLR_FreespaceSectorKinestate55  " ";
CM_ SG_ 667 FLR_FreespaceSectorConfidence55  " ";
CM_ SG_ 667 FLR_FreespaceSectorDistance55  " ";
CM_ SG_ 667 FLR_FreespaceSectorKinestate54  " ";
CM_ SG_ 667 FLR_FreespaceSectorConfidence54  " ";
CM_ SG_ 667 FLR_FreespaceSectorDistance54  " ";
CM_ SG_ 667 FLR_FreespaceSectorKinestate53  " ";
CM_ SG_ 667 FLR_FreespaceSectorConfidence53  " ";
CM_ SG_ 667 FLR_FreespaceSectorDistance53  " ";
CM_ SG_ 667 FLR_FreespaceSectorKinestate52  " ";
CM_ SG_ 667 FLR_FreespaceSectorConfidence52  " ";
CM_ SG_ 667 FLR_FreespaceSectorDistance52  " ";
CM_ SG_ 667 FLR_FreespaceSectorKinestate51  " ";
CM_ SG_ 667 FLR_FreespaceSectorConfidence51  " ";
CM_ SG_ 667 FLR_FreespaceSectorDistance51  " ";
CM_ SG_ 667 FLR_FreespaceSectorKinestate50  " ";
CM_ SG_ 667 FLR_FreespaceSectorConfidence50  " ";
CM_ SG_ 667 FLR_FreespaceSectorDistance50  " ";
CM_ SG_ 667 FLR_FreespaceSectorKinestate49  " ";
CM_ SG_ 667 FLR_FreespaceSectorConfidence49  " ";
CM_ SG_ 667 FLR_FreespaceSectorDistance49  " ";
CM_ SG_ 667 FLR_FreespaceSectorKinestate48  " ";
CM_ SG_ 667 FLR_FreespaceSectorConfidence48  " ";
CM_ SG_ 667 FLR_FreespaceSectorDistance48  " ";
CM_ SG_ 667 FLR_FreespaceSectorKinestate47  " ";
CM_ SG_ 667 FLR_FreespaceSectorConfidence47  " ";
CM_ SG_ 667 FLR_FreespaceSectorDistance47  " ";
CM_ SG_ 667 FLR_FreespaceSectorKinestate46  " ";
CM_ SG_ 667 FLR_FreespaceSectorConfidence46  " ";
CM_ SG_ 667 FLR_FreespaceSectorDistance46  " ";
CM_ SG_ 667 FLR_FreespaceSectorKinestate45  " ";
CM_ SG_ 667 FLR_FreespaceSectorConfidence45  " ";
CM_ SG_ 667 FLR_FreespaceSectorDistance45  " ";
CM_ SG_ 667 FLR_FreespaceSectorKinestate44  " ";
CM_ SG_ 667 FLR_FreespaceSectorConfidence44  " ";
CM_ SG_ 667 FLR_FreespaceSectorDistance44  " ";
CM_ SG_ 667 FLR_FreespaceSectorKinestate43  " ";
CM_ SG_ 667 FLR_FreespaceSectorConfidence43  " ";
CM_ SG_ 667 FLR_FreespaceSectorDistance43  " ";
CM_ SG_ 667 FLR_FreespaceSectorKinestate42  " ";
CM_ SG_ 667 FLR_FreespaceSectorConfidence42  " ";
CM_ SG_ 667 FLR_FreespaceSectorDistance42  " ";
CM_ SG_ 667 FLR_FreespaceSectorKinestate41  " ";
CM_ SG_ 667 FLR_FreespaceSectorConfidence41  " ";
CM_ SG_ 667 FLR_FreespaceSectorDistance41  " ";
CM_ SG_ 667 FLR_FreespaceSectorKinestate40  " ";
CM_ SG_ 667 FLR_FreespaceSectorConfidence40  " ";
CM_ SG_ 667 FLR_FreespaceSectorDistance40  " ";
CM_ SG_ 667 FLR_FreespaceSectorKinestate39  " ";
CM_ SG_ 667 FLR_FreespaceSectorConfidence39  " ";
CM_ SG_ 667 FLR_FreespaceSectorDistance39  " ";
CM_ SG_ 667 FLR_FreespaceSectorKinestate38  " ";
CM_ SG_ 667 FLR_FreespaceSectorConfidence38  " ";
CM_ SG_ 667 FLR_FreespaceSectorDistance38  " ";
CM_ SG_ 667 FLR_FreespaceSectorKinestate37  " ";
CM_ SG_ 667 FLR_FreespaceSectorConfidence37  " ";
CM_ SG_ 667 FLR_FreespaceSectorDistance37  " ";
CM_ SG_ 667 FLR_FreespaceSectorKinestate36  " ";
CM_ SG_ 667 FLR_FreespaceSectorConfidence36  " ";
CM_ SG_ 667 FLR_FreespaceSectorDistance36  " ";
CM_ SG_ 667 FLR_FreespaceSectorKinestate35  " ";
CM_ SG_ 667 FLR_FreespaceSectorConfidence35  " ";
CM_ SG_ 667 FLR_FreespaceSectorDistance35  " ";

CM_ BO_ 668  " ";
CM_ SG_ 668 FLR_CRCCheck_29C  " ";
CM_ SG_ 668 FLR_RollingCounter_29C  " ";
CM_ SG_ 668 FLR_FreespaceSectorKinestate102  " ";
CM_ SG_ 668 FLR_FreespaceSectorConfidence102  " ";
CM_ SG_ 668 FLR_FreespaceSectorDistance102  " ";
CM_ SG_ 668 FLR_FreespaceSectorKinestate101  " ";
CM_ SG_ 668 FLR_FreespaceSectorConfidence101  " ";
CM_ SG_ 668 FLR_FreespaceSectorDistance101  " ";
CM_ SG_ 668 FLR_FreespaceSectorKinestate100  " ";
CM_ SG_ 668 FLR_FreespaceSectorConfidence100  " ";
CM_ SG_ 668 FLR_FreespaceSectorDistance100  " ";
CM_ SG_ 668 FLR_FreespaceSectorKinestate99  " ";
CM_ SG_ 668 FLR_FreespaceSectorConfidence99  " ";
CM_ SG_ 668 FLR_FreespaceSectorDistance99  " ";
CM_ SG_ 668 FLR_FreespaceSectorKinestate98  " ";
CM_ SG_ 668 FLR_FreespaceSectorConfidence98  " ";
CM_ SG_ 668 FLR_FreespaceSectorDistance98  " ";
CM_ SG_ 668 FLR_FreespaceSectorKinestate97  " ";
CM_ SG_ 668 FLR_FreespaceSectorConfidence97  " ";
CM_ SG_ 668 FLR_FreespaceSectorDistance97  " ";
CM_ SG_ 668 FLR_FreespaceSectorKinestate96  " ";
CM_ SG_ 668 FLR_FreespaceSectorConfidence96  " ";
CM_ SG_ 668 FLR_FreespaceSectorDistance96  " ";
CM_ SG_ 668 FLR_FreespaceSectorKinestate95  " ";
CM_ SG_ 668 FLR_FreespaceSectorConfidence95  " ";
CM_ SG_ 668 FLR_FreespaceSectorDistance95  " ";
CM_ SG_ 668 FLR_FreespaceSectorKinestate94  " ";
CM_ SG_ 668 FLR_FreespaceSectorConfidence94  " ";
CM_ SG_ 668 FLR_FreespaceSectorDistance94  " ";
CM_ SG_ 668 FLR_FreespaceSectorKinestate93  " ";
CM_ SG_ 668 FLR_FreespaceSectorConfidence93  " ";
CM_ SG_ 668 FLR_FreespaceSectorDistance93  " ";
CM_ SG_ 668 FLR_FreespaceSectorKinestate92  " ";
CM_ SG_ 668 FLR_FreespaceSectorConfidence92  " ";
CM_ SG_ 668 FLR_FreespaceSectorDistance92  " ";
CM_ SG_ 668 FLR_FreespaceSectorKinestate91  " ";
CM_ SG_ 668 FLR_FreespaceSectorConfidence91  " ";
CM_ SG_ 668 FLR_FreespaceSectorDistance91  " ";
CM_ SG_ 668 FLR_FreespaceSectorKinestate90  " ";
CM_ SG_ 668 FLR_FreespaceSectorConfidence90  " ";
CM_ SG_ 668 FLR_FreespaceSectorDistance90  " ";
CM_ SG_ 668 FLR_FreespaceSectorKinestate89  " ";
CM_ SG_ 668 FLR_FreespaceSectorConfidence89  " ";
CM_ SG_ 668 FLR_FreespaceSectorDistance89  " ";
CM_ SG_ 668 FLR_FreespaceSectorKinestate88  " ";
CM_ SG_ 668 FLR_FreespaceSectorConfidence88  " ";
CM_ SG_ 668 FLR_FreespaceSectorDistance88  " ";
CM_ SG_ 668 FLR_FreespaceSectorKinestate87  " ";
CM_ SG_ 668 FLR_FreespaceSectorConfidence87  " ";
CM_ SG_ 668 FLR_FreespaceSectorDistance87  " ";
CM_ SG_ 668 FLR_FreespaceSectorKinestate86  " ";
CM_ SG_ 668 FLR_FreespaceSectorConfidence86  " ";
CM_ SG_ 668 FLR_FreespaceSectorDistance86  " ";
CM_ SG_ 668 FLR_FreespaceSectorKinestate85  " ";
CM_ SG_ 668 FLR_FreespaceSectorConfidence85  " ";
CM_ SG_ 668 FLR_FreespaceSectorDistance85  " ";
CM_ SG_ 668 FLR_FreespaceSectorKinestate84  " ";
CM_ SG_ 668 FLR_FreespaceSectorConfidence84  " ";
CM_ SG_ 668 FLR_FreespaceSectorDistance84  " ";
CM_ SG_ 668 FLR_FreespaceSectorKinestate83  " ";
CM_ SG_ 668 FLR_FreespaceSectorConfidence83  " ";
CM_ SG_ 668 FLR_FreespaceSectorDistance83  " ";
CM_ SG_ 668 FLR_FreespaceSectorKinestate82  " ";
CM_ SG_ 668 FLR_FreespaceSectorConfidence82  " ";
CM_ SG_ 668 FLR_FreespaceSectorDistance82  " ";
CM_ SG_ 668 FLR_FreespaceSectorKinestate81  " ";
CM_ SG_ 668 FLR_FreespaceSectorConfidence81  " ";
CM_ SG_ 668 FLR_FreespaceSectorDistance81  " ";
CM_ SG_ 668 FLR_FreespaceSectorKinestate80  " ";
CM_ SG_ 668 FLR_FreespaceSectorConfidence80  " ";
CM_ SG_ 668 FLR_FreespaceSectorDistance80  " ";
CM_ SG_ 668 FLR_FreespaceSectorKinestate79  " ";
CM_ SG_ 668 FLR_FreespaceSectorConfidence79  " ";
CM_ SG_ 668 FLR_FreespaceSectorDistance79  " ";
CM_ SG_ 668 FLR_FreespaceSectorKinestate78  " ";
CM_ SG_ 668 FLR_FreespaceSectorConfidence78  " ";
CM_ SG_ 668 FLR_FreespaceSectorDistance78  " ";
CM_ SG_ 668 FLR_FreespaceSectorKinestate77  " ";
CM_ SG_ 668 FLR_FreespaceSectorConfidence77  " ";
CM_ SG_ 668 FLR_FreespaceSectorDistance77  " ";
CM_ SG_ 668 FLR_FreespaceSectorKinestate76  " ";
CM_ SG_ 668 FLR_FreespaceSectorConfidence76  " ";
CM_ SG_ 668 FLR_FreespaceSectorDistance76  " ";
CM_ SG_ 668 FLR_FreespaceSectorKinestate75  " ";
CM_ SG_ 668 FLR_FreespaceSectorConfidence75  " ";
CM_ SG_ 668 FLR_FreespaceSectorDistance75  " ";
CM_ SG_ 668 FLR_FreespaceSectorKinestate74  " ";
CM_ SG_ 668 FLR_FreespaceSectorConfidence74  " ";
CM_ SG_ 668 FLR_FreespaceSectorDistance74  " ";
CM_ SG_ 668 FLR_FreespaceSectorKinestate73  " ";
CM_ SG_ 668 FLR_FreespaceSectorConfidence73  " ";
CM_ SG_ 668 FLR_FreespaceSectorDistance73  " ";
CM_ SG_ 668 FLR_FreespaceSectorKinestate72  " ";
CM_ SG_ 668 FLR_FreespaceSectorConfidence72  " ";
CM_ SG_ 668 FLR_FreespaceSectorDistance72  " ";
CM_ SG_ 668 FLR_FreespaceSectorKinestate71  " ";
CM_ SG_ 668 FLR_FreespaceSectorConfidence71  " ";
CM_ SG_ 668 FLR_FreespaceSectorDistance71  " ";
CM_ SG_ 668 FLR_FreespaceSectorKinestate70  " ";
CM_ SG_ 668 FLR_FreespaceSectorConfidence70  " ";
CM_ SG_ 668 FLR_FreespaceSectorDistance70  " ";
CM_ SG_ 668 FLR_FreespaceSectorKinestate69  " ";
CM_ SG_ 668 FLR_FreespaceSectorConfidence69  " ";
CM_ SG_ 668 FLR_FreespaceSectorDistance69  " ";

BA_DEF_ SG_  "GenSigStartValue" INT 0 0;
BA_DEF_ SG_  "GenSigInvalidValue" STRING  ;
BA_DEF_ SG_  "GenSigCycleTime" INT 0 0;
BA_DEF_ SG_  "GenSigSendType" ENUM  "Cyclic","OnWrite","OnWriteWithRepetition","OnChange","OnChangeWithRepetition","IfActive","IfActiveWithRepetition","NoSigSendType","NotUsed","NotUsed","NotUsed","NotUsed","NotUsed";
BA_DEF_ BO_  "GenMsgSendType" ENUM  "Cyclic","Event","Direct","NotUsed","NotUsed","Cyclic","NotUsed","IfActive","NoMsgSendType","NotUsed";
BA_DEF_ BO_  "GenMsgILSupport" ENUM  "No","Yes";
BA_DEF_ BO_  "GenMsgCycleTime" INT 0 65535;
BA_DEF_ BO_  "CANFD_BRS" ENUM  "0","1";
BA_DEF_ BO_  "VFrameFormat" ENUM  "StandardCAN","ExtendedCAN","reserved","reserved","reserved","reserved","reserved","reserved","reserved","reserved","reserved","reserved","reserved","reserved","StandardCAN_FD","ExtendedCAN_FD";
BA_DEF_DEF_  "GenSigStartValue" 0;
BA_DEF_DEF_  "GenSigInvalidValue" "/";
BA_DEF_DEF_  "GenSigCycleTime" 0;
BA_DEF_DEF_  "GenSigSendType" "Cyclic";
BA_DEF_DEF_  "GenMsgSendType" "NoMsgSendType";
BA_DEF_DEF_  "GenMsgILSupport" "Yes";
BA_DEF_DEF_  "GenMsgCycleTime" 0;
BA_DEF_DEF_  "CANFD_BRS" "1";
BA_DEF_DEF_  "VFrameFormat" "StandardCAN";
BA_ "GenMsgCycleTime" BO_ 604 50;
BA_ "GenMsgSendType" BO_ 604 0;
BA_ "VFrameFormat" BO_ 604 14;
BA_ "GenMsgCycleTime" BO_ 605 50;
BA_ "GenMsgSendType" BO_ 605 0;
BA_ "VFrameFormat" BO_ 605 14;
BA_ "GenMsgCycleTime" BO_ 606 50;
BA_ "GenMsgSendType" BO_ 606 0;
BA_ "VFrameFormat" BO_ 606 14;
BA_ "GenMsgCycleTime" BO_ 607 50;
BA_ "GenMsgSendType" BO_ 607 0;
BA_ "VFrameFormat" BO_ 607 14;
BA_ "GenMsgCycleTime" BO_ 642 50;
BA_ "GenMsgSendType" BO_ 642 0;
BA_ "VFrameFormat" BO_ 642 14;
BA_ "GenMsgCycleTime" BO_ 687 1000;
BA_ "GenMsgSendType" BO_ 687 0;
BA_ "VFrameFormat" BO_ 687 14;
BA_ "GenMsgCycleTime" BO_ 690 50;
BA_ "GenMsgSendType" BO_ 690 0;
BA_ "VFrameFormat" BO_ 690 14;
BA_ "GenMsgCycleTime" BO_ 579 50;
BA_ "GenMsgSendType" BO_ 579 0;
BA_ "VFrameFormat" BO_ 579 14;
BA_ "GenMsgCycleTime" BO_ 589 50;
BA_ "GenMsgSendType" BO_ 589 0;
BA_ "VFrameFormat" BO_ 589 14;
BA_ "GenMsgCycleTime" BO_ 694 50;
BA_ "GenMsgSendType" BO_ 694 0;
BA_ "VFrameFormat" BO_ 694 14;
BA_ "GenMsgCycleTime" BO_ 585 50;
BA_ "GenMsgSendType" BO_ 585 0;
BA_ "VFrameFormat" BO_ 585 14;
BA_ "GenMsgCycleTime" BO_ 666 50;
BA_ "GenMsgSendType" BO_ 666 0;
BA_ "VFrameFormat" BO_ 666 14;
BA_ "GenMsgCycleTime" BO_ 667 50;
BA_ "GenMsgSendType" BO_ 667 0;
BA_ "VFrameFormat" BO_ 667 14;
BA_ "GenMsgCycleTime" BO_ 668 50;
BA_ "GenMsgSendType" BO_ 668 0;
BA_ "VFrameFormat" BO_ 668 14;

BA_ "GenSigCycleTime" SG_ 604 FLR_OBJ26_LostCnt 50;
BA_ "GenSigCycleTime" SG_ 604 FLR_OBJ25_LostCnt 50;
BA_ "GenSigCycleTime" SG_ 604 FLR_OBJ26_Dx 50;
BA_ "GenSigCycleTime" SG_ 604 FLR_OBJ26_Dy 50;
BA_ "GenSigCycleTime" SG_ 604 FLR_OBJ25_Dx 50;
BA_ "GenSigCycleTime" SG_ 604 FLR_OBJ25_Dy 50;
BA_ "GenSigCycleTime" SG_ 604 FLR_OBJ26_Vx 50;
BA_ "GenSigCycleTime" SG_ 604 FLR_OBJ26_Vy 50;
BA_ "GenSigCycleTime" SG_ 604 FLR_OBJ26_Convergence 50;
BA_ "GenSigCycleTime" SG_ 604 FLR_OBJ26_DelayTime 50;
BA_ "GenSigCycleTime" SG_ 604 FLR_OBJ26_HeightGround 50;
BA_ "GenSigCycleTime" SG_ 604 FLR_OBJ26_MotionStatus 50;
BA_ "GenSigCycleTime" SG_ 604 FLR_OBJ26_RelVx_std 50;
BA_ "GenSigInvalidValue" SG_ 604 FLR_OBJ26_RelVx_std "4095";
BA_ "GenSigCycleTime" SG_ 604 FLR_OBJ26_RelVy_std 50;
BA_ "GenSigInvalidValue" SG_ 604 FLR_OBJ26_RelVy_std "1023";
BA_ "GenSigCycleTime" SG_ 604 FLR_OBJ26_Dx_Vnce 50;
BA_ "GenSigInvalidValue" SG_ 604 FLR_OBJ26_Dx_Vnce "16383";
BA_ "GenSigCycleTime" SG_ 604 FLR_OBJ26_Dy_Vnce 50;
BA_ "GenSigInvalidValue" SG_ 604 FLR_OBJ26_Dy_Vnce "1023";
BA_ "GenSigCycleTime" SG_ 604 FLR_OBJ25_Vx 50;
BA_ "GenSigCycleTime" SG_ 604 FLR_OBJ25_Vy 50;
BA_ "GenSigCycleTime" SG_ 604 FLR_OBJ25_Convergence 50;
BA_ "GenSigCycleTime" SG_ 604 FLR_OBJ25_DelayTime 50;
BA_ "GenSigCycleTime" SG_ 604 FLR_OBJ25_HeightGround 50;
BA_ "GenSigCycleTime" SG_ 604 FLR_OBJ25_MotionStatus 50;
BA_ "GenSigCycleTime" SG_ 604 FLR_OBJ25_RelVx_std 50;
BA_ "GenSigInvalidValue" SG_ 604 FLR_OBJ25_RelVx_std "4095";
BA_ "GenSigCycleTime" SG_ 604 FLR_OBJ25_RelVy_std 50;
BA_ "GenSigInvalidValue" SG_ 604 FLR_OBJ25_RelVy_std "1023";
BA_ "GenSigCycleTime" SG_ 604 FLR_OBJ25_Dx_Vnce 50;
BA_ "GenSigInvalidValue" SG_ 604 FLR_OBJ25_Dx_Vnce "16383";
BA_ "GenSigCycleTime" SG_ 604 FLR_OBJ25_Dy_Vnce 50;
BA_ "GenSigInvalidValue" SG_ 604 FLR_OBJ25_Dy_Vnce "1023";
BA_ "GenSigCycleTime" SG_ 604 FLR_CRCCheck_25C 50;
BA_ "GenSigCycleTime" SG_ 604 FLR_RollingCounter_25C 50;
BA_ "GenSigCycleTime" SG_ 604 FLR_OBJ26_Track_Age 50;
BA_ "GenSigCycleTime" SG_ 604 FLR_OBJ26_RefPointLoc 50;
BA_ "GenSigCycleTime" SG_ 604 FLR_OBJ26_ObstacleProb 50;
BA_ "GenSigCycleTime" SG_ 604 FLR_OBJ26_Measured 50;
BA_ "GenSigInvalidValue" SG_ 604 FLR_OBJ26_Measured "0";
BA_ "GenSigCycleTime" SG_ 604 FLR_OBJ26_ExistProb 50;
BA_ "GenSigInvalidValue" SG_ 604 FLR_OBJ26_ExistProb "0";
BA_ "GenSigCycleTime" SG_ 604 FLR_OBJ26_Location 50;
BA_ "GenSigInvalidValue" SG_ 604 FLR_OBJ26_Location "0";
BA_ "GenSigCycleTime" SG_ 604 FLR_OBJ26_RelAx 50;
BA_ "GenSigCycleTime" SG_ 604 FLR_OBJ26_RelAy 50;
BA_ "GenSigCycleTime" SG_ 604 FLR_OBJ26_RelVx 50;
BA_ "GenSigCycleTime" SG_ 604 FLR_OBJ26_RelVy 50;
BA_ "GenSigCycleTime" SG_ 604 FLR_OBJ26_HeadingAngle 50;
BA_ "GenSigCycleTime" SG_ 604 FLR_OBJ26_Length 50;
BA_ "GenSigCycleTime" SG_ 604 FLR_OBJ26_Height 50;
BA_ "GenSigCycleTime" SG_ 604 FLR_OBJ26_Width 50;
BA_ "GenSigCycleTime" SG_ 604 FLR_OBJ26_Type 50;
BA_ "GenSigInvalidValue" SG_ 604 FLR_OBJ26_Type "0";
BA_ "GenSigCycleTime" SG_ 604 FLR_OBJ26_Track_ID 50;
BA_ "GenSigCycleTime" SG_ 604 FLR_OBJ25_Track_Age 50;
BA_ "GenSigCycleTime" SG_ 604 FLR_OBJ25_RefPointLoc 50;
BA_ "GenSigCycleTime" SG_ 604 FLR_OBJ25_ObstacleProb 50;
BA_ "GenSigCycleTime" SG_ 604 FLR_OBJ25_Measured 50;
BA_ "GenSigInvalidValue" SG_ 604 FLR_OBJ25_Measured "0";
BA_ "GenSigCycleTime" SG_ 604 FLR_OBJ25_ExistProb 50;
BA_ "GenSigInvalidValue" SG_ 604 FLR_OBJ25_ExistProb "0";
BA_ "GenSigCycleTime" SG_ 604 FLR_OBJ25_Location 50;
BA_ "GenSigInvalidValue" SG_ 604 FLR_OBJ25_Location "0";
BA_ "GenSigCycleTime" SG_ 604 FLR_OBJ25_RelAx 50;
BA_ "GenSigCycleTime" SG_ 604 FLR_OBJ25_RelAy 50;
BA_ "GenSigCycleTime" SG_ 604 FLR_OBJ25_RelVx 50;
BA_ "GenSigCycleTime" SG_ 604 FLR_OBJ25_RelVy 50;
BA_ "GenSigCycleTime" SG_ 604 FLR_OBJ25_HeadingAngle 50;
BA_ "GenSigCycleTime" SG_ 604 FLR_OBJ25_Length 50;
BA_ "GenSigCycleTime" SG_ 604 FLR_OBJ25_Height 50;
BA_ "GenSigCycleTime" SG_ 604 FLR_OBJ25_Width 50;
BA_ "GenSigCycleTime" SG_ 604 FLR_OBJ25_Type 50;
BA_ "GenSigInvalidValue" SG_ 604 FLR_OBJ25_Type "0";
BA_ "GenSigCycleTime" SG_ 604 FLR_OBJ25_Track_ID 50;

BA_ "GenSigCycleTime" SG_ 605 FLR_OBJ28_LostCnt 50;
BA_ "GenSigCycleTime" SG_ 605 FLR_OBJ27_LostCnt 50;
BA_ "GenSigCycleTime" SG_ 605 FLR_OBJ28_Dx 50;
BA_ "GenSigCycleTime" SG_ 605 FLR_OBJ28_Dy 50;
BA_ "GenSigCycleTime" SG_ 605 FLR_OBJ27_Dx 50;
BA_ "GenSigCycleTime" SG_ 605 FLR_OBJ27_Dy 50;
BA_ "GenSigCycleTime" SG_ 605 FLR_OBJ28_Vx 50;
BA_ "GenSigCycleTime" SG_ 605 FLR_OBJ28_Vy 50;
BA_ "GenSigCycleTime" SG_ 605 FLR_OBJ28_Convergence 50;
BA_ "GenSigCycleTime" SG_ 605 FLR_OBJ28_DelayTime 50;
BA_ "GenSigCycleTime" SG_ 605 FLR_OBJ28_HeightGround 50;
BA_ "GenSigCycleTime" SG_ 605 FLR_OBJ28_MotionStatus 50;
BA_ "GenSigCycleTime" SG_ 605 FLR_OBJ28_RelVx_std 50;
BA_ "GenSigInvalidValue" SG_ 605 FLR_OBJ28_RelVx_std "4095";
BA_ "GenSigCycleTime" SG_ 605 FLR_OBJ28_RelVy_std 50;
BA_ "GenSigInvalidValue" SG_ 605 FLR_OBJ28_RelVy_std "1023";
BA_ "GenSigCycleTime" SG_ 605 FLR_OBJ28_Dx_Vnce 50;
BA_ "GenSigInvalidValue" SG_ 605 FLR_OBJ28_Dx_Vnce "16383";
BA_ "GenSigCycleTime" SG_ 605 FLR_OBJ28_Dy_Vnce 50;
BA_ "GenSigInvalidValue" SG_ 605 FLR_OBJ28_Dy_Vnce "1023";
BA_ "GenSigCycleTime" SG_ 605 FLR_OBJ27_Vx 50;
BA_ "GenSigCycleTime" SG_ 605 FLR_OBJ27_Vy 50;
BA_ "GenSigCycleTime" SG_ 605 FLR_OBJ27_Convergence 50;
BA_ "GenSigCycleTime" SG_ 605 FLR_OBJ27_DelayTime 50;
BA_ "GenSigCycleTime" SG_ 605 FLR_OBJ27_HeightGround 50;
BA_ "GenSigCycleTime" SG_ 605 FLR_OBJ27_MotionStatus 50;
BA_ "GenSigCycleTime" SG_ 605 FLR_OBJ27_RelVx_std 50;
BA_ "GenSigInvalidValue" SG_ 605 FLR_OBJ27_RelVx_std "4095";
BA_ "GenSigCycleTime" SG_ 605 FLR_OBJ27_RelVy_std 50;
BA_ "GenSigInvalidValue" SG_ 605 FLR_OBJ27_RelVy_std "1023";
BA_ "GenSigCycleTime" SG_ 605 FLR_OBJ27_Dx_Vnce 50;
BA_ "GenSigInvalidValue" SG_ 605 FLR_OBJ27_Dx_Vnce "16383";
BA_ "GenSigCycleTime" SG_ 605 FLR_OBJ27_Dy_Vnce 50;
BA_ "GenSigInvalidValue" SG_ 605 FLR_OBJ27_Dy_Vnce "1023";
BA_ "GenSigCycleTime" SG_ 605 FLR_CRCCheck_25D 50;
BA_ "GenSigCycleTime" SG_ 605 FLR_RollingCounter_25D 50;
BA_ "GenSigCycleTime" SG_ 605 FLR_OBJ28_Track_Age 50;
BA_ "GenSigCycleTime" SG_ 605 FLR_OBJ28_RefPointLoc 50;
BA_ "GenSigCycleTime" SG_ 605 FLR_OBJ28_ObstacleProb 50;
BA_ "GenSigCycleTime" SG_ 605 FLR_OBJ28_Measured 50;
BA_ "GenSigInvalidValue" SG_ 605 FLR_OBJ28_Measured "0";
BA_ "GenSigCycleTime" SG_ 605 FLR_OBJ28_ExistProb 50;
BA_ "GenSigInvalidValue" SG_ 605 FLR_OBJ28_ExistProb "0";
BA_ "GenSigCycleTime" SG_ 605 FLR_OBJ28_Location 50;
BA_ "GenSigInvalidValue" SG_ 605 FLR_OBJ28_Location "0";
BA_ "GenSigCycleTime" SG_ 605 FLR_OBJ28_RelAx 50;
BA_ "GenSigCycleTime" SG_ 605 FLR_OBJ28_RelAy 50;
BA_ "GenSigCycleTime" SG_ 605 FLR_OBJ28_RelVx 50;
BA_ "GenSigCycleTime" SG_ 605 FLR_OBJ28_RelVy 50;
BA_ "GenSigCycleTime" SG_ 605 FLR_OBJ28_HeadingAngle 50;
BA_ "GenSigCycleTime" SG_ 605 FLR_OBJ28_Length 50;
BA_ "GenSigCycleTime" SG_ 605 FLR_OBJ28_Height 50;
BA_ "GenSigCycleTime" SG_ 605 FLR_OBJ28_Width 50;
BA_ "GenSigCycleTime" SG_ 605 FLR_OBJ28_Type 50;
BA_ "GenSigInvalidValue" SG_ 605 FLR_OBJ28_Type "0";
BA_ "GenSigCycleTime" SG_ 605 FLR_OBJ28_Track_ID 50;
BA_ "GenSigCycleTime" SG_ 605 FLR_OBJ27_Track_Age 50;
BA_ "GenSigCycleTime" SG_ 605 FLR_OBJ27_RefPointLoc 50;
BA_ "GenSigCycleTime" SG_ 605 FLR_OBJ27_ObstacleProb 50;
BA_ "GenSigCycleTime" SG_ 605 FLR_OBJ27_Measured 50;
BA_ "GenSigInvalidValue" SG_ 605 FLR_OBJ27_Measured "0";
BA_ "GenSigCycleTime" SG_ 605 FLR_OBJ27_ExistProb 50;
BA_ "GenSigInvalidValue" SG_ 605 FLR_OBJ27_ExistProb "0";
BA_ "GenSigCycleTime" SG_ 605 FLR_OBJ27_Location 50;
BA_ "GenSigInvalidValue" SG_ 605 FLR_OBJ27_Location "0";
BA_ "GenSigCycleTime" SG_ 605 FLR_OBJ27_RelAx 50;
BA_ "GenSigCycleTime" SG_ 605 FLR_OBJ27_RelAy 50;
BA_ "GenSigCycleTime" SG_ 605 FLR_OBJ27_RelVx 50;
BA_ "GenSigCycleTime" SG_ 605 FLR_OBJ27_RelVy 50;
BA_ "GenSigCycleTime" SG_ 605 FLR_OBJ27_HeadingAngle 50;
BA_ "GenSigCycleTime" SG_ 605 FLR_OBJ27_Length 50;
BA_ "GenSigCycleTime" SG_ 605 FLR_OBJ27_Height 50;
BA_ "GenSigCycleTime" SG_ 605 FLR_OBJ27_Width 50;
BA_ "GenSigCycleTime" SG_ 605 FLR_OBJ27_Type 50;
BA_ "GenSigInvalidValue" SG_ 605 FLR_OBJ27_Type "0";
BA_ "GenSigCycleTime" SG_ 605 FLR_OBJ27_Track_ID 50;

BA_ "GenSigCycleTime" SG_ 606 FLR_OBJ30_LostCnt 50;
BA_ "GenSigCycleTime" SG_ 606 FLR_OBJ29_LostCnt 50;
BA_ "GenSigCycleTime" SG_ 606 FLR_OBJ30_Dx 50;
BA_ "GenSigCycleTime" SG_ 606 FLR_OBJ30_Dy 50;
BA_ "GenSigCycleTime" SG_ 606 FLR_OBJ29_Dx 50;
BA_ "GenSigCycleTime" SG_ 606 FLR_OBJ29_Dy 50;
BA_ "GenSigCycleTime" SG_ 606 FLR_OBJ30_Vx 50;
BA_ "GenSigCycleTime" SG_ 606 FLR_OBJ30_Vy 50;
BA_ "GenSigCycleTime" SG_ 606 FLR_OBJ30_Convergence 50;
BA_ "GenSigCycleTime" SG_ 606 FLR_OBJ30_DelayTime 50;
BA_ "GenSigCycleTime" SG_ 606 FLR_OBJ30_HeightGround 50;
BA_ "GenSigCycleTime" SG_ 606 FLR_OBJ30_MotionStatus 50;
BA_ "GenSigCycleTime" SG_ 606 FLR_OBJ30_RelVx_std 50;
BA_ "GenSigInvalidValue" SG_ 606 FLR_OBJ30_RelVx_std "4095";
BA_ "GenSigCycleTime" SG_ 606 FLR_OBJ30_RelVy_std 50;
BA_ "GenSigInvalidValue" SG_ 606 FLR_OBJ30_RelVy_std "1023";
BA_ "GenSigCycleTime" SG_ 606 FLR_OBJ30_Dx_Vnce 50;
BA_ "GenSigInvalidValue" SG_ 606 FLR_OBJ30_Dx_Vnce "16383";
BA_ "GenSigCycleTime" SG_ 606 FLR_OBJ30_Dy_Vnce 50;
BA_ "GenSigInvalidValue" SG_ 606 FLR_OBJ30_Dy_Vnce "1023";
BA_ "GenSigCycleTime" SG_ 606 FLR_OBJ29_Vx 50;
BA_ "GenSigCycleTime" SG_ 606 FLR_OBJ29_Vy 50;
BA_ "GenSigCycleTime" SG_ 606 FLR_OBJ29_Convergence 50;
BA_ "GenSigCycleTime" SG_ 606 FLR_OBJ29_DelayTime 50;
BA_ "GenSigCycleTime" SG_ 606 FLR_OBJ29_HeightGround 50;
BA_ "GenSigCycleTime" SG_ 606 FLR_OBJ29_MotionStatus 50;
BA_ "GenSigCycleTime" SG_ 606 FLR_OBJ29_RelVx_std 50;
BA_ "GenSigInvalidValue" SG_ 606 FLR_OBJ29_RelVx_std "4095";
BA_ "GenSigCycleTime" SG_ 606 FLR_OBJ29_RelVy_std 50;
BA_ "GenSigInvalidValue" SG_ 606 FLR_OBJ29_RelVy_std "1023";
BA_ "GenSigCycleTime" SG_ 606 FLR_OBJ29_Dx_Vnce 50;
BA_ "GenSigInvalidValue" SG_ 606 FLR_OBJ29_Dx_Vnce "16383";
BA_ "GenSigCycleTime" SG_ 606 FLR_OBJ29_Dy_Vnce 50;
BA_ "GenSigInvalidValue" SG_ 606 FLR_OBJ29_Dy_Vnce "1023";
BA_ "GenSigCycleTime" SG_ 606 FLR_CRCCheck_25E 50;
BA_ "GenSigCycleTime" SG_ 606 FLR_RollingCounter_25E 50;
BA_ "GenSigCycleTime" SG_ 606 FLR_OBJ30_Track_Age 50;
BA_ "GenSigCycleTime" SG_ 606 FLR_OBJ30_RefPointLoc 50;
BA_ "GenSigCycleTime" SG_ 606 FLR_OBJ30_ObstacleProb 50;
BA_ "GenSigCycleTime" SG_ 606 FLR_OBJ30_Measured 50;
BA_ "GenSigInvalidValue" SG_ 606 FLR_OBJ30_Measured "0";
BA_ "GenSigCycleTime" SG_ 606 FLR_OBJ30_ExistProb 50;
BA_ "GenSigInvalidValue" SG_ 606 FLR_OBJ30_ExistProb "0";
BA_ "GenSigCycleTime" SG_ 606 FLR_OBJ30_Location 50;
BA_ "GenSigInvalidValue" SG_ 606 FLR_OBJ30_Location "0";
BA_ "GenSigCycleTime" SG_ 606 FLR_OBJ30_RelAx 50;
BA_ "GenSigCycleTime" SG_ 606 FLR_OBJ30_RelAy 50;
BA_ "GenSigCycleTime" SG_ 606 FLR_OBJ30_RelVx 50;
BA_ "GenSigCycleTime" SG_ 606 FLR_OBJ30_RelVy 50;
BA_ "GenSigCycleTime" SG_ 606 FLR_OBJ30_HeadingAngle 50;
BA_ "GenSigCycleTime" SG_ 606 FLR_OBJ30_Length 50;
BA_ "GenSigCycleTime" SG_ 606 FLR_OBJ30_Height 50;
BA_ "GenSigCycleTime" SG_ 606 FLR_OBJ30_Width 50;
BA_ "GenSigCycleTime" SG_ 606 FLR_OBJ30_Type 50;
BA_ "GenSigInvalidValue" SG_ 606 FLR_OBJ30_Type "0";
BA_ "GenSigCycleTime" SG_ 606 FLR_OBJ30_Track_ID 50;
BA_ "GenSigCycleTime" SG_ 606 FLR_OBJ29_Track_Age 50;
BA_ "GenSigCycleTime" SG_ 606 FLR_OBJ29_RefPointLoc 50;
BA_ "GenSigCycleTime" SG_ 606 FLR_OBJ29_ObstacleProb 50;
BA_ "GenSigCycleTime" SG_ 606 FLR_OBJ29_Measured 50;
BA_ "GenSigInvalidValue" SG_ 606 FLR_OBJ29_Measured "0";
BA_ "GenSigCycleTime" SG_ 606 FLR_OBJ29_ExistProb 50;
BA_ "GenSigInvalidValue" SG_ 606 FLR_OBJ29_ExistProb "0";
BA_ "GenSigCycleTime" SG_ 606 FLR_OBJ29_Location 50;
BA_ "GenSigInvalidValue" SG_ 606 FLR_OBJ29_Location "0";
BA_ "GenSigCycleTime" SG_ 606 FLR_OBJ29_RelAx 50;
BA_ "GenSigCycleTime" SG_ 606 FLR_OBJ29_RelAy 50;
BA_ "GenSigCycleTime" SG_ 606 FLR_OBJ29_RelVx 50;
BA_ "GenSigCycleTime" SG_ 606 FLR_OBJ29_RelVy 50;
BA_ "GenSigCycleTime" SG_ 606 FLR_OBJ29_HeadingAngle 50;
BA_ "GenSigCycleTime" SG_ 606 FLR_OBJ29_Length 50;
BA_ "GenSigCycleTime" SG_ 606 FLR_OBJ29_Height 50;
BA_ "GenSigCycleTime" SG_ 606 FLR_OBJ29_Width 50;
BA_ "GenSigCycleTime" SG_ 606 FLR_OBJ29_Type 50;
BA_ "GenSigInvalidValue" SG_ 606 FLR_OBJ29_Type "0";
BA_ "GenSigCycleTime" SG_ 606 FLR_OBJ29_Track_ID 50;

BA_ "GenSigCycleTime" SG_ 607 FLR_OBJ32_LostCnt 50;
BA_ "GenSigCycleTime" SG_ 607 FLR_OBJ31_LostCnt 50;
BA_ "GenSigCycleTime" SG_ 607 FLR_OBJ32_Dx 50;
BA_ "GenSigCycleTime" SG_ 607 FLR_OBJ32_Dy 50;
BA_ "GenSigCycleTime" SG_ 607 FLR_OBJ31_Dx 50;
BA_ "GenSigCycleTime" SG_ 607 FLR_OBJ31_Dy 50;
BA_ "GenSigCycleTime" SG_ 607 FLR_OBJ32_Vx 50;
BA_ "GenSigCycleTime" SG_ 607 FLR_OBJ32_Vy 50;
BA_ "GenSigCycleTime" SG_ 607 FLR_OBJ32_Convergence 50;
BA_ "GenSigCycleTime" SG_ 607 FLR_OBJ32_DelayTime 50;
BA_ "GenSigCycleTime" SG_ 607 FLR_OBJ32_HeightGround 50;
BA_ "GenSigCycleTime" SG_ 607 FLR_OBJ32_MotionStatus 50;
BA_ "GenSigCycleTime" SG_ 607 FLR_OBJ32_RelVx_std 50;
BA_ "GenSigInvalidValue" SG_ 607 FLR_OBJ32_RelVx_std "4095";
BA_ "GenSigCycleTime" SG_ 607 FLR_OBJ32_RelVy_std 50;
BA_ "GenSigInvalidValue" SG_ 607 FLR_OBJ32_RelVy_std "1023";
BA_ "GenSigCycleTime" SG_ 607 FLR_OBJ32_Dx_Vnce 50;
BA_ "GenSigInvalidValue" SG_ 607 FLR_OBJ32_Dx_Vnce "16383";
BA_ "GenSigCycleTime" SG_ 607 FLR_OBJ32_Dy_Vnce 50;
BA_ "GenSigInvalidValue" SG_ 607 FLR_OBJ32_Dy_Vnce "1023";
BA_ "GenSigCycleTime" SG_ 607 FLR_OBJ31_Vx 50;
BA_ "GenSigCycleTime" SG_ 607 FLR_OBJ31_Vy 50;
BA_ "GenSigCycleTime" SG_ 607 FLR_OBJ31_Convergence 50;
BA_ "GenSigCycleTime" SG_ 607 FLR_OBJ31_DelayTime 50;
BA_ "GenSigCycleTime" SG_ 607 FLR_OBJ31_HeightGround 50;
BA_ "GenSigCycleTime" SG_ 607 FLR_OBJ31_MotionStatus 50;
BA_ "GenSigCycleTime" SG_ 607 FLR_OBJ31_RelVx_std 50;
BA_ "GenSigInvalidValue" SG_ 607 FLR_OBJ31_RelVx_std "4095";
BA_ "GenSigCycleTime" SG_ 607 FLR_OBJ31_RelVy_std 50;
BA_ "GenSigInvalidValue" SG_ 607 FLR_OBJ31_RelVy_std "1023";
BA_ "GenSigCycleTime" SG_ 607 FLR_OBJ31_Dx_Vnce 50;
BA_ "GenSigInvalidValue" SG_ 607 FLR_OBJ31_Dx_Vnce "16383";
BA_ "GenSigCycleTime" SG_ 607 FLR_OBJ31_Dy_Vnce 50;
BA_ "GenSigInvalidValue" SG_ 607 FLR_OBJ31_Dy_Vnce "1023";
BA_ "GenSigCycleTime" SG_ 607 FLR_CRCCheck_25F 50;
BA_ "GenSigCycleTime" SG_ 607 FLR_RollingCounter_25F 50;
BA_ "GenSigCycleTime" SG_ 607 FLR_OBJ32_Track_Age 50;
BA_ "GenSigCycleTime" SG_ 607 FLR_OBJ32_RefPointLoc 50;
BA_ "GenSigCycleTime" SG_ 607 FLR_OBJ32_ObstacleProb 50;
BA_ "GenSigCycleTime" SG_ 607 FLR_OBJ32_Measured 50;
BA_ "GenSigInvalidValue" SG_ 607 FLR_OBJ32_Measured "0";
BA_ "GenSigCycleTime" SG_ 607 FLR_OBJ32_ExistProb 50;
BA_ "GenSigInvalidValue" SG_ 607 FLR_OBJ32_ExistProb "0";
BA_ "GenSigCycleTime" SG_ 607 FLR_OBJ32_Location 50;
BA_ "GenSigInvalidValue" SG_ 607 FLR_OBJ32_Location "0";
BA_ "GenSigCycleTime" SG_ 607 FLR_OBJ32_RelAx 50;
BA_ "GenSigCycleTime" SG_ 607 FLR_OBJ32_RelAy 50;
BA_ "GenSigCycleTime" SG_ 607 FLR_OBJ32_RelVx 50;
BA_ "GenSigCycleTime" SG_ 607 FLR_OBJ32_RelVy 50;
BA_ "GenSigCycleTime" SG_ 607 FLR_OBJ32_HeadingAngle 50;
BA_ "GenSigCycleTime" SG_ 607 FLR_OBJ32_Length 50;
BA_ "GenSigCycleTime" SG_ 607 FLR_OBJ32_Height 50;
BA_ "GenSigCycleTime" SG_ 607 FLR_OBJ32_Width 50;
BA_ "GenSigCycleTime" SG_ 607 FLR_OBJ32_Type 50;
BA_ "GenSigInvalidValue" SG_ 607 FLR_OBJ32_Type "0";
BA_ "GenSigCycleTime" SG_ 607 FLR_OBJ32_Track_ID 50;
BA_ "GenSigCycleTime" SG_ 607 FLR_OBJ31_Track_Age 50;
BA_ "GenSigCycleTime" SG_ 607 FLR_OBJ31_RefPointLoc 50;
BA_ "GenSigCycleTime" SG_ 607 FLR_OBJ31_ObstacleProb 50;
BA_ "GenSigCycleTime" SG_ 607 FLR_OBJ31_Measured 50;
BA_ "GenSigInvalidValue" SG_ 607 FLR_OBJ31_Measured "0";
BA_ "GenSigCycleTime" SG_ 607 FLR_OBJ31_ExistProb 50;
BA_ "GenSigInvalidValue" SG_ 607 FLR_OBJ31_ExistProb "0";
BA_ "GenSigCycleTime" SG_ 607 FLR_OBJ31_Location 50;
BA_ "GenSigInvalidValue" SG_ 607 FLR_OBJ31_Location "0";
BA_ "GenSigCycleTime" SG_ 607 FLR_OBJ31_RelAx 50;
BA_ "GenSigCycleTime" SG_ 607 FLR_OBJ31_RelAy 50;
BA_ "GenSigCycleTime" SG_ 607 FLR_OBJ31_RelVx 50;
BA_ "GenSigCycleTime" SG_ 607 FLR_OBJ31_RelVy 50;
BA_ "GenSigCycleTime" SG_ 607 FLR_OBJ31_HeadingAngle 50;
BA_ "GenSigCycleTime" SG_ 607 FLR_OBJ31_Length 50;
BA_ "GenSigCycleTime" SG_ 607 FLR_OBJ31_Height 50;
BA_ "GenSigCycleTime" SG_ 607 FLR_OBJ31_Width 50;
BA_ "GenSigCycleTime" SG_ 607 FLR_OBJ31_Type 50;
BA_ "GenSigInvalidValue" SG_ 607 FLR_OBJ31_Type "0";
BA_ "GenSigCycleTime" SG_ 607 FLR_OBJ31_Track_ID 50;

BA_ "GenSigCycleTime" SG_ 642 FRGuardrailReadyFlag 50;
BA_ "GenSigCycleTime" SG_ 642 FLGuardrailReadyFlag 50;
BA_ "GenSigCycleTime" SG_ 642 FLR_CRCCheck_282 50;
BA_ "GenSigCycleTime" SG_ 642 FLR_RollingCounter_282 50;
BA_ "GenSigCycleTime" SG_ 642 FLR_FrontRightGuardrailConfidenc 50;
BA_ "GenSigCycleTime" SG_ 642 FLR__FronRightGuardrail_End 50;
BA_ "GenSigCycleTime" SG_ 642 FLR__FronRightGuardrail_Start 50;
BA_ "GenSigCycleTime" SG_ 642 FLR_FrontRightGuardrailC3 50;
BA_ "GenSigStartValue" SG_ 642 FLR_FrontRightGuardrailC3 2047.000000;
BA_ "GenSigCycleTime" SG_ 642 FLR_FrontRightGuardrailC2 50;
BA_ "GenSigStartValue" SG_ 642 FLR_FrontRightGuardrailC2 2047.000000;
BA_ "GenSigCycleTime" SG_ 642 FLR_FrontRightGuardrailC1 50;
BA_ "GenSigStartValue" SG_ 642 FLR_FrontRightGuardrailC1 2047.000000;
BA_ "GenSigCycleTime" SG_ 642 FLR_FrontRightGuardrailC0 50;
BA_ "GenSigCycleTime" SG_ 642 FLR_FrontLeftGuardrailConfidence 50;
BA_ "GenSigCycleTime" SG_ 642 FLR__FrontLeftGuardrail_End 50;
BA_ "GenSigCycleTime" SG_ 642 FLR__FrontLeftGuardrail_Start 50;
BA_ "GenSigCycleTime" SG_ 642 FLR_FrontLeftGuardrailC3 50;
BA_ "GenSigStartValue" SG_ 642 FLR_FrontLeftGuardrailC3 2047.000000;
BA_ "GenSigCycleTime" SG_ 642 FLR_FrontLeftGuardrailC2 50;
BA_ "GenSigStartValue" SG_ 642 FLR_FrontLeftGuardrailC2 2047.000000;
BA_ "GenSigCycleTime" SG_ 642 FLR_FrontLeftGuardrailC1 50;
BA_ "GenSigStartValue" SG_ 642 FLR_FrontLeftGuardrailC1 2047.000000;
BA_ "GenSigCycleTime" SG_ 642 FLR_FrontLeftGuardrailC0 50;
BA_ "GenSigCycleTime" SG_ 642 FLR_LocHeader_RollingCounter 50;

BA_ "GenSigCycleTime" SG_ 687 FRR_HwVers6 1000;
BA_ "GenSigCycleTime" SG_ 687 FRR_HwVers5 1000;
BA_ "GenSigCycleTime" SG_ 687 FRR_HwVers4 1000;
BA_ "GenSigCycleTime" SG_ 687 FRR_HwVers3 1000;
BA_ "GenSigCycleTime" SG_ 687 FRR_HwVers2 1000;
BA_ "GenSigCycleTime" SG_ 687 FRR_HwVers1 1000;
BA_ "GenSigCycleTime" SG_ 687 FRR_HwVers0 1000;
BA_ "GenSigCycleTime" SG_ 687 FRR_SwVers6 1000;
BA_ "GenSigCycleTime" SG_ 687 FRR_SwVers5 1000;
BA_ "GenSigCycleTime" SG_ 687 FRR_SwVers4 1000;
BA_ "GenSigCycleTime" SG_ 687 FRR_SwVers3 1000;
BA_ "GenSigCycleTime" SG_ 687 FRR_SwVers2 1000;
BA_ "GenSigCycleTime" SG_ 687 FRR_SwVers1 1000;
BA_ "GenSigCycleTime" SG_ 687 FRR_SwVers0 1000;
BA_ "GenSigCycleTime" SG_ 687 FLR_HwVers6 1000;
BA_ "GenSigCycleTime" SG_ 687 FLR_HwVers5 1000;
BA_ "GenSigCycleTime" SG_ 687 FLR_HwVers4 1000;
BA_ "GenSigCycleTime" SG_ 687 FLR_HwVers3 1000;
BA_ "GenSigCycleTime" SG_ 687 FLR_HwVers2 1000;
BA_ "GenSigCycleTime" SG_ 687 FLR_HwVers1 1000;
BA_ "GenSigCycleTime" SG_ 687 FLR_HwVers0 1000;
BA_ "GenSigCycleTime" SG_ 687 FLR_SwVers6 1000;
BA_ "GenSigCycleTime" SG_ 687 FLR_SwVers5 1000;
BA_ "GenSigCycleTime" SG_ 687 FLR_SwVers4 1000;
BA_ "GenSigCycleTime" SG_ 687 FLR_SwVers3 1000;
BA_ "GenSigCycleTime" SG_ 687 FLR_SwVers2 1000;
BA_ "GenSigCycleTime" SG_ 687 FLR_SwVers1 1000;
BA_ "GenSigCycleTime" SG_ 687 FLR_SwVers0 1000;

BA_ "GenSigCycleTime" SG_ 690 RLR_CRCCheck_2B2 50;
BA_ "GenSigCycleTime" SG_ 690 RLR_RollingCounter_2B2 50;
BA_ "GenSigCycleTime" SG_ 690 FLR_ResetSts 50;
BA_ "GenSigInvalidValue" SG_ 690 FLR_ResetSts "7";
BA_ "GenSigCycleTime" SG_ 690 FuncDegradeType_FL 50;
BA_ "GenSigCycleTime" SG_ 690 FUSION_TimeoutCnt_FL 50;
BA_ "GenSigCycleTime" SG_ 690 VALIDATION_TimeoutCnt_FL 50;
BA_ "GenSigCycleTime" SG_ 690 CurFrameCycle_FL 50;
BA_ "GenSigCycleTime" SG_ 690 ProcessTimeoutCnt_FL 50;
BA_ "GenSigCycleTime" SG_ 690 RevFrameCnt_FL 50;
BA_ "GenSigCycleTime" SG_ 690 Local_Pointcloud_Number_FL 50;
BA_ "GenSigCycleTime" SG_ 690 RealTimeCal_PrcssBar_FL 50;
BA_ "GenSigCycleTime" SG_ 690 RealTimeCal_VelErrOutput_FL 50;
BA_ "GenSigCycleTime" SG_ 690 RealTimeCal_HoriMntErrOutput_FL 50;
BA_ "GenSigCycleTime" SG_ 690 RealTimeCal_FailReasonCode_FL 50;
BA_ "GenSigCycleTime" SG_ 690 RealTimeCal_Status_FL 50;
BA_ "GenSigCycleTime" SG_ 690 DiagCal_PrcssBar_FL 50;
BA_ "GenSigCycleTime" SG_ 690 DiagCal_VelErrOutput_FL 50;
BA_ "GenSigCycleTime" SG_ 690 DiagCal_HoriMntErrOutput_FL 50;
BA_ "GenSigCycleTime" SG_ 690 DiagCal_FailReasonCode_FL 50;
BA_ "GenSigCycleTime" SG_ 690 DiagCal_Status_FL 50;
BA_ "GenSigCycleTime" SG_ 690 EolCal_PrcssBar_FL 50;
BA_ "GenSigCycleTime" SG_ 690 EolCal_VelErrOutput_FL 50;
BA_ "GenSigCycleTime" SG_ 690 EolCal_HoriMntErrOutput_FL 50;
BA_ "GenSigCycleTime" SG_ 690 EolCal_FailReasonCode_FL 50;
BA_ "GenSigCycleTime" SG_ 690 EolCal_Status_FL 50;
BA_ "GenSigCycleTime" SG_ 690 PriCounter_FL 50;
BA_ "GenSigCycleTime" SG_ 690 MsgCounter_FL 50;

BA_ "GenSigCycleTime" SG_ 579 Transmitcnt6_F 50;
BA_ "GenSigCycleTime" SG_ 579 Transmitcnt5_F 50;
BA_ "GenSigCycleTime" SG_ 579 Transmitcnt4_F 50;
BA_ "GenSigCycleTime" SG_ 579 Transmitcnt3_F 50;
BA_ "GenSigCycleTime" SG_ 579 Transmitcnt2_F 50;
BA_ "GenSigCycleTime" SG_ 579 Transmitcnt1_F 50;
BA_ "GenSigCycleTime" SG_ 579 FLR_Track_ID_R 50;
BA_ "GenSigCycleTime" SG_ 579 FLR_Measured_R 50;
BA_ "GenSigCycleTime" SG_ 579 FLR_Location_R 50;
BA_ "GenSigCycleTime" SG_ 579 FLR_ClassComfrmFlg_R 50;
BA_ "GenSigCycleTime" SG_ 579 FLR_TrckrType_R 50;
BA_ "GenSigCycleTime" SG_ 579 FLR_TrckrAge_R 50;
BA_ "GenSigCycleTime" SG_ 579 FLR_MotionStatus_R 50;
BA_ "GenSigCycleTime" SG_ 579 FLR_AbsVy_R 50;
BA_ "GenSigCycleTime" SG_ 579 FLR_AbsoVx_R 50;
BA_ "GenSigCycleTime" SG_ 579 FLR_LocDx_R 50;
BA_ "GenSigCycleTime" SG_ 579 FLR_LocDy_R 50;
BA_ "GenSigCycleTime" SG_ 579 FLR_HeadingAngle_R 50;
BA_ "GenSigCycleTime" SG_ 579 FLR_Length_R 50;
BA_ "GenSigCycleTime" SG_ 579 FLR_Width_R 50;
BA_ "GenSigCycleTime" SG_ 579 FLR_Track_ID_L 50;
BA_ "GenSigCycleTime" SG_ 579 FLR_Measured_L 50;
BA_ "GenSigCycleTime" SG_ 579 FLR_Location_L 50;
BA_ "GenSigCycleTime" SG_ 579 FLR_ClassComfrmFlg_L 50;
BA_ "GenSigCycleTime" SG_ 579 FLR_TrckrType_L 50;
BA_ "GenSigCycleTime" SG_ 579 FLR_TrckrAge_L 50;
BA_ "GenSigCycleTime" SG_ 579 FLR_MotionStatus_L 50;
BA_ "GenSigCycleTime" SG_ 579 FLR_AbsVy_L 50;
BA_ "GenSigCycleTime" SG_ 579 FLR_AbsoVx_L 50;
BA_ "GenSigCycleTime" SG_ 579 FLR_LocDx_L 50;
BA_ "GenSigCycleTime" SG_ 579 FLR_LocDy_L 50;
BA_ "GenSigCycleTime" SG_ 579 FLR_HeadingAngle_L 50;
BA_ "GenSigCycleTime" SG_ 579 FLR_Length_L 50;
BA_ "GenSigCycleTime" SG_ 579 FLR_Width_L 50;
BA_ "GenSigCycleTime" SG_ 579 FLR_TrckrNum 50;
BA_ "GenSigCycleTime" SG_ 579 FLR_TrackerTimeStamp 50;

BA_ "GenSigCycleTime" SG_ 589 FRR_Right_FCTARAlert 50;
BA_ "GenSigCycleTime" SG_ 589 FRR_FCTBActive 50;
BA_ "GenSigCycleTime" SG_ 589 FRR_FCTBTargetDeceleration 50;
BA_ "GenSigStartValue" SG_ 589 FRR_FCTBTargetDeceleration 32000.000000;
BA_ "GenSigCycleTime" SG_ 589 FRR_EmergencyLightingRequest 50;
BA_ "GenSigCycleTime" SG_ 589 FRR_FCTBVehilceHoldReq 50;
BA_ "GenSigCycleTime" SG_ 589 FRR_FCTBStatus 50;
BA_ "GenSigInvalidValue" SG_ 589 FRR_FCTBStatus "3";
BA_ "GenSigCycleTime" SG_ 589 FRR_FCTAStatus 50;
BA_ "GenSigInvalidValue" SG_ 589 FRR_FCTAStatus "3";
BA_ "GenSigCycleTime" SG_ 589 FRR_Left_FCTALAlert 50;

BA_ "GenSigCycleTime" SG_ 694 RLR_CRCCheck_2B6 50;
BA_ "GenSigCycleTime" SG_ 694 RLR_RollingCounter_2B6 50;
BA_ "GenSigCycleTime" SG_ 694 FLR_OBJ32_lAy 50;
BA_ "GenSigInvalidValue" SG_ 694 FLR_OBJ32_lAy "NA";
BA_ "GenSigCycleTime" SG_ 694 FLR_OBJ31_lAy 50;
BA_ "GenSigInvalidValue" SG_ 694 FLR_OBJ31_lAy "NA";
BA_ "GenSigCycleTime" SG_ 694 FLR_OBJ30_lAy 50;
BA_ "GenSigInvalidValue" SG_ 694 FLR_OBJ30_lAy "NA";
BA_ "GenSigCycleTime" SG_ 694 FLR_OBJ29_lAy 50;
BA_ "GenSigInvalidValue" SG_ 694 FLR_OBJ29_lAy "NA";
BA_ "GenSigCycleTime" SG_ 694 FLR_OBJ28_lAy 50;
BA_ "GenSigInvalidValue" SG_ 694 FLR_OBJ28_lAy "NA";
BA_ "GenSigCycleTime" SG_ 694 FLR_OBJ27_lAy 50;
BA_ "GenSigInvalidValue" SG_ 694 FLR_OBJ27_lAy "NA";
BA_ "GenSigCycleTime" SG_ 694 FLR_OBJ26_lAy 50;
BA_ "GenSigInvalidValue" SG_ 694 FLR_OBJ26_lAy "NA";
BA_ "GenSigCycleTime" SG_ 694 FLR_OBJ25_lAy 50;
BA_ "GenSigInvalidValue" SG_ 694 FLR_OBJ25_lAy "NA";
BA_ "GenSigCycleTime" SG_ 694 FLR_OBJ24_lAy 50;
BA_ "GenSigInvalidValue" SG_ 694 FLR_OBJ24_lAy "NA";
BA_ "GenSigCycleTime" SG_ 694 FLR_OBJ23_lAy 50;
BA_ "GenSigInvalidValue" SG_ 694 FLR_OBJ23_lAy "NA";
BA_ "GenSigCycleTime" SG_ 694 FLR_OBJ22_lAy 50;
BA_ "GenSigInvalidValue" SG_ 694 FLR_OBJ22_lAy "NA";
BA_ "GenSigCycleTime" SG_ 694 FLR_OBJ21_lAy 50;
BA_ "GenSigInvalidValue" SG_ 694 FLR_OBJ21_lAy "NA";
BA_ "GenSigCycleTime" SG_ 694 FLR_OBJ20_lAy 50;
BA_ "GenSigInvalidValue" SG_ 694 FLR_OBJ20_lAy "NA";
BA_ "GenSigCycleTime" SG_ 694 FLR_OBJ19_lAy 50;
BA_ "GenSigInvalidValue" SG_ 694 FLR_OBJ19_lAy "NA";
BA_ "GenSigCycleTime" SG_ 694 FLR_OBJ18_lAy 50;
BA_ "GenSigInvalidValue" SG_ 694 FLR_OBJ18_lAy "NA";
BA_ "GenSigCycleTime" SG_ 694 FLR_OBJ17_lAy 50;
BA_ "GenSigInvalidValue" SG_ 694 FLR_OBJ17_lAy "NA";
BA_ "GenSigCycleTime" SG_ 694 FLR_OBJ16_lAy 50;
BA_ "GenSigInvalidValue" SG_ 694 FLR_OBJ16_lAy "NA";
BA_ "GenSigCycleTime" SG_ 694 FLR_OBJ15_lAy 50;
BA_ "GenSigInvalidValue" SG_ 694 FLR_OBJ15_lAy "NA";
BA_ "GenSigCycleTime" SG_ 694 FLR_OBJ14_lAy 50;
BA_ "GenSigInvalidValue" SG_ 694 FLR_OBJ14_lAy "NA";
BA_ "GenSigCycleTime" SG_ 694 FLR_OBJ13_lAy 50;
BA_ "GenSigInvalidValue" SG_ 694 FLR_OBJ13_lAy "NA";
BA_ "GenSigCycleTime" SG_ 694 FLR_OBJ12_lAy 50;
BA_ "GenSigInvalidValue" SG_ 694 FLR_OBJ12_lAy "NA";
BA_ "GenSigCycleTime" SG_ 694 FLR_OBJ11_lAy 50;
BA_ "GenSigInvalidValue" SG_ 694 FLR_OBJ11_lAy "NA";
BA_ "GenSigCycleTime" SG_ 694 FLR_OBJ10_lAy 50;
BA_ "GenSigInvalidValue" SG_ 694 FLR_OBJ10_lAy "NA";
BA_ "GenSigCycleTime" SG_ 694 FLR_OBJ9_lAy 50;
BA_ "GenSigInvalidValue" SG_ 694 FLR_OBJ9_lAy "NA";
BA_ "GenSigCycleTime" SG_ 694 FLR_OBJ8_lAy 50;
BA_ "GenSigInvalidValue" SG_ 694 FLR_OBJ8_lAy "NA";
BA_ "GenSigCycleTime" SG_ 694 FLR_OBJ7_lAy 50;
BA_ "GenSigInvalidValue" SG_ 694 FLR_OBJ7_lAy "NA";
BA_ "GenSigCycleTime" SG_ 694 FLR_OBJ6_lAy 50;
BA_ "GenSigInvalidValue" SG_ 694 FLR_OBJ6_lAy "NA";
BA_ "GenSigCycleTime" SG_ 694 FLR_OBJ5_lAy 50;
BA_ "GenSigInvalidValue" SG_ 694 FLR_OBJ5_lAy "NA";
BA_ "GenSigCycleTime" SG_ 694 FLR_OBJ4_lAy 50;
BA_ "GenSigInvalidValue" SG_ 694 FLR_OBJ4_lAy "NA";
BA_ "GenSigCycleTime" SG_ 694 FLR_OBJ3_lAy 50;
BA_ "GenSigInvalidValue" SG_ 694 FLR_OBJ3_lAy "NA";
BA_ "GenSigCycleTime" SG_ 694 FLR_OBJ2_lAy 50;
BA_ "GenSigInvalidValue" SG_ 694 FLR_OBJ2_lAy "NA";
BA_ "GenSigCycleTime" SG_ 694 FLR_OBJ1_lAy 50;
BA_ "GenSigInvalidValue" SG_ 694 FLR_OBJ1_lAy "NA";

BA_ "GenSigCycleTime" SG_ 585 FRR_Suppliers 50;
BA_ "GenSigCycleTime" SG_ 585 FRR_FS_TiOut 50;
BA_ "GenSigCycleTime" SG_ 585 FRR_FS_TiLeap 50;
BA_ "GenSigCycleTime" SG_ 585 FRR_FS_TiBas 50;
BA_ "GenSigCycleTime" SG_ 585 FRR_FS_TiStamp 50;
BA_ "GenSigCycleTime" SG_ 585 FRR_CRCCheck_249 50;
BA_ "GenSigCycleTime" SG_ 585 FRR_RollingCounter_249 50;
BA_ "GenSigCycleTime" SG_ 585 FRR_ECU_TiOut 50;
BA_ "GenSigCycleTime" SG_ 585 FRR_ECU_TiLeap 50;
BA_ "GenSigCycleTime" SG_ 585 FRR_ECU_TiBas 50;
BA_ "GenSigCycleTime" SG_ 585 FRR_ECU_TiStamp 50;
BA_ "GenSigCycleTime" SG_ 585 FRR_MCUTiStamp 50;
BA_ "GenSigCycleTime" SG_ 585 FRR_SyncTiStamp 50;
BA_ "GenSigCycleTime" SG_ 585 FRR_WorkMode 50;
BA_ "GenSigCycleTime" SG_ 585 FRR_ObjDelay 50;
BA_ "GenSigCycleTime" SG_ 585 FRR_SystemStatus 50;
BA_ "GenSigStartValue" SG_ 585 FRR_SystemStatus 1.000000;
BA_ "GenSigInvalidValue" SG_ 585 FRR_SystemStatus "7";

BA_ "GenSigCycleTime" SG_ 666 FLR_CRCCheck_29A 50;
BA_ "GenSigCycleTime" SG_ 666 FLR_RollingCounter_29A 50;
BA_ "GenSigCycleTime" SG_ 666 FLR_FreespaceSectorKinestate34 50;
BA_ "GenSigCycleTime" SG_ 666 FLR_FreespaceSectorConfidence34 50;
BA_ "GenSigCycleTime" SG_ 666 FLR_FreespaceSectorDistance34 50;
BA_ "GenSigCycleTime" SG_ 666 FLR_FreespaceSectorKinestate33 50;
BA_ "GenSigCycleTime" SG_ 666 FLR_FreespaceSectorConfidence33 50;
BA_ "GenSigCycleTime" SG_ 666 FLR_FreespaceSectorDistance33 50;
BA_ "GenSigCycleTime" SG_ 666 FLR_FreespaceSectorKinestate32 50;
BA_ "GenSigCycleTime" SG_ 666 FLR_FreespaceSectorConfidence32 50;
BA_ "GenSigCycleTime" SG_ 666 FLR_FreespaceSectorDistance32 50;
BA_ "GenSigCycleTime" SG_ 666 FLR_FreespaceSectorKinestate31 50;
BA_ "GenSigCycleTime" SG_ 666 FLR_FreespaceSectorConfidence31 50;
BA_ "GenSigCycleTime" SG_ 666 FLR_FreespaceSectorDistance31 50;
BA_ "GenSigCycleTime" SG_ 666 FLR_FreespaceSectorKinestate30 50;
BA_ "GenSigCycleTime" SG_ 666 FLR_FreespaceSectorConfidence30 50;
BA_ "GenSigCycleTime" SG_ 666 FLR_FreespaceSectorDistance30 50;
BA_ "GenSigCycleTime" SG_ 666 FLR_FreespaceSectorKinestate29 50;
BA_ "GenSigCycleTime" SG_ 666 FLR_FreespaceSectorConfidence29 50;
BA_ "GenSigCycleTime" SG_ 666 FLR_FreespaceSectorDistance29 50;
BA_ "GenSigCycleTime" SG_ 666 FLR_FreespaceSectorKinestate28 50;
BA_ "GenSigCycleTime" SG_ 666 FLR_FreespaceSectorConfidence28 50;
BA_ "GenSigCycleTime" SG_ 666 FLR_FreespaceSectorDistance28 50;
BA_ "GenSigCycleTime" SG_ 666 FLR_FreespaceSectorKinestate27 50;
BA_ "GenSigCycleTime" SG_ 666 FLR_FreespaceSectorConfidence27 50;
BA_ "GenSigCycleTime" SG_ 666 FLR_FreespaceSectorDistance27 50;
BA_ "GenSigCycleTime" SG_ 666 FLR_FreespaceSectorKinestate26 50;
BA_ "GenSigCycleTime" SG_ 666 FLR_FreespaceSectorConfidence26 50;
BA_ "GenSigCycleTime" SG_ 666 FLR_FreespaceSectorDistance26 50;
BA_ "GenSigCycleTime" SG_ 666 FLR_FreespaceSectorKinestate25 50;
BA_ "GenSigCycleTime" SG_ 666 FLR_FreespaceSectorConfidence25 50;
BA_ "GenSigCycleTime" SG_ 666 FLR_FreespaceSectorDistance25 50;
BA_ "GenSigCycleTime" SG_ 666 FLR_FreespaceSectorKinestate24 50;
BA_ "GenSigCycleTime" SG_ 666 FLR_FreespaceSectorConfidence24 50;
BA_ "GenSigCycleTime" SG_ 666 FLR_FreespaceSectorDistance24 50;
BA_ "GenSigCycleTime" SG_ 666 FLR_FreespaceSectorKinestate23 50;
BA_ "GenSigCycleTime" SG_ 666 FLR_FreespaceSectorConfidence23 50;
BA_ "GenSigCycleTime" SG_ 666 FLR_FreespaceSectorDistance23 50;
BA_ "GenSigCycleTime" SG_ 666 FLR_FreespaceSectorKinestate22 50;
BA_ "GenSigCycleTime" SG_ 666 FLR_FreespaceSectorConfidence22 50;
BA_ "GenSigCycleTime" SG_ 666 FLR_FreespaceSectorDistance22 50;
BA_ "GenSigCycleTime" SG_ 666 FLR_FreespaceSectorKinestate21 50;
BA_ "GenSigCycleTime" SG_ 666 FLR_FreespaceSectorConfidence21 50;
BA_ "GenSigCycleTime" SG_ 666 FLR_FreespaceSectorDistance21 50;
BA_ "GenSigCycleTime" SG_ 666 FLR_FreespaceSectorKinestate20 50;
BA_ "GenSigCycleTime" SG_ 666 FLR_FreespaceSectorConfidence20 50;
BA_ "GenSigCycleTime" SG_ 666 FLR_FreespaceSectorDistance20 50;
BA_ "GenSigCycleTime" SG_ 666 FLR_FreespaceSectorKinestate19 50;
BA_ "GenSigCycleTime" SG_ 666 FLR_FreespaceSectorConfidence19 50;
BA_ "GenSigCycleTime" SG_ 666 FLR_FreespaceSectorDistance19 50;
BA_ "GenSigCycleTime" SG_ 666 FLR_FreespaceSectorKinestate18 50;
BA_ "GenSigCycleTime" SG_ 666 FLR_FreespaceSectorConfidence18 50;
BA_ "GenSigCycleTime" SG_ 666 FLR_FreespaceSectorDistance18 50;
BA_ "GenSigCycleTime" SG_ 666 FLR_FreespaceSectorKinestate17 50;
BA_ "GenSigCycleTime" SG_ 666 FLR_FreespaceSectorConfidence17 50;
BA_ "GenSigCycleTime" SG_ 666 FLR_FreespaceSectorDistance17 50;
BA_ "GenSigCycleTime" SG_ 666 FLR_FreespaceSectorKinestate16 50;
BA_ "GenSigCycleTime" SG_ 666 FLR_FreespaceSectorConfidence16 50;
BA_ "GenSigCycleTime" SG_ 666 FLR_FreespaceSectorDistance16 50;
BA_ "GenSigCycleTime" SG_ 666 FLR_FreespaceSectorKinestate15 50;
BA_ "GenSigCycleTime" SG_ 666 FLR_FreespaceSectorConfidence15 50;
BA_ "GenSigCycleTime" SG_ 666 FLR_FreespaceSectorDistance15 50;
BA_ "GenSigCycleTime" SG_ 666 FLR_FreespaceSectorKinestate14 50;
BA_ "GenSigCycleTime" SG_ 666 FLR_FreespaceSectorConfidence14 50;
BA_ "GenSigCycleTime" SG_ 666 FLR_FreespaceSectorDistance14 50;
BA_ "GenSigCycleTime" SG_ 666 FLR_FreespaceSectorKinestate13 50;
BA_ "GenSigCycleTime" SG_ 666 FLR_FreespaceSectorConfidence13 50;
BA_ "GenSigCycleTime" SG_ 666 FLR_FreespaceSectorDistance13 50;
BA_ "GenSigCycleTime" SG_ 666 FLR_FreespaceSectorKinestate12 50;
BA_ "GenSigCycleTime" SG_ 666 FLR_FreespaceSectorConfidence12 50;
BA_ "GenSigCycleTime" SG_ 666 FLR_FreespaceSectorDistance12 50;
BA_ "GenSigCycleTime" SG_ 666 FLR_FreespaceSectorKinestate11 50;
BA_ "GenSigCycleTime" SG_ 666 FLR_FreespaceSectorConfidence11 50;
BA_ "GenSigCycleTime" SG_ 666 FLR_FreespaceSectorDistance11 50;
BA_ "GenSigCycleTime" SG_ 666 FLR_FreespaceSectorKinestate10 50;
BA_ "GenSigCycleTime" SG_ 666 FLR_FreespaceSectorConfidence10 50;
BA_ "GenSigCycleTime" SG_ 666 FLR_FreespaceSectorDistance10 50;
BA_ "GenSigCycleTime" SG_ 666 FLR_FreespaceSectorKinestate9 50;
BA_ "GenSigCycleTime" SG_ 666 FLR_FreespaceSectorConfidence9 50;
BA_ "GenSigCycleTime" SG_ 666 FLR_FreespaceSectorDistance9 50;
BA_ "GenSigCycleTime" SG_ 666 FLR_FreespaceSectorKinestate8 50;
BA_ "GenSigCycleTime" SG_ 666 FLR_FreespaceSectorConfidence8 50;
BA_ "GenSigCycleTime" SG_ 666 FLR_FreespaceSectorDistance8 50;
BA_ "GenSigCycleTime" SG_ 666 FLR_FreespaceSectorKinestate7 50;
BA_ "GenSigCycleTime" SG_ 666 FLR_FreespaceSectorConfidence7 50;
BA_ "GenSigCycleTime" SG_ 666 FLR_FreespaceSectorDistance7 50;
BA_ "GenSigCycleTime" SG_ 666 FLR_FreespaceSectorKinestate6 50;
BA_ "GenSigCycleTime" SG_ 666 FLR_FreespaceSectorConfidence6 50;
BA_ "GenSigCycleTime" SG_ 666 FLR_FreespaceSectorDistance6 50;
BA_ "GenSigCycleTime" SG_ 666 FLR_FreespaceSectorKinestate5 50;
BA_ "GenSigCycleTime" SG_ 666 FLR_FreespaceSectorConfidence5 50;
BA_ "GenSigCycleTime" SG_ 666 FLR_FreespaceSectorDistance5 50;
BA_ "GenSigCycleTime" SG_ 666 FLR_FreespaceSectorKinestate4 50;
BA_ "GenSigCycleTime" SG_ 666 FLR_FreespaceSectorConfidence4 50;
BA_ "GenSigCycleTime" SG_ 666 FLR_FreespaceSectorDistance4 50;
BA_ "GenSigCycleTime" SG_ 666 FLR_FreespaceSectorKinestate3 50;
BA_ "GenSigCycleTime" SG_ 666 FLR_FreespaceSectorConfidence3 50;
BA_ "GenSigCycleTime" SG_ 666 FLR_FreespaceSectorDistance3 50;
BA_ "GenSigCycleTime" SG_ 666 FLR_FreespaceSectorKinestate2 50;
BA_ "GenSigCycleTime" SG_ 666 FLR_FreespaceSectorConfidence2 50;
BA_ "GenSigCycleTime" SG_ 666 FLR_FreespaceSectorDistance2 50;
BA_ "GenSigCycleTime" SG_ 666 FLR_FreespaceSectorKinestate1 50;
BA_ "GenSigCycleTime" SG_ 666 FLR_FreespaceSectorConfidence1 50;
BA_ "GenSigCycleTime" SG_ 666 FLR_FreespaceSectorDistance1 50;

BA_ "GenSigCycleTime" SG_ 667 FLR_CRCCheck_29B 50;
BA_ "GenSigCycleTime" SG_ 667 FLR_RollingCounter_29B 50;
BA_ "GenSigCycleTime" SG_ 667 FLR_FreespaceSectorKinestate68 50;
BA_ "GenSigCycleTime" SG_ 667 FLR_FreespaceSectorConfidence68 50;
BA_ "GenSigCycleTime" SG_ 667 FLR_FreespaceSectorDistance68 50;
BA_ "GenSigCycleTime" SG_ 667 FLR_FreespaceSectorKinestate67 50;
BA_ "GenSigCycleTime" SG_ 667 FLR_FreespaceSectorConfidence67 50;
BA_ "GenSigCycleTime" SG_ 667 FLR_FreespaceSectorDistance67 50;
BA_ "GenSigCycleTime" SG_ 667 FLR_FreespaceSectorKinestate66 50;
BA_ "GenSigCycleTime" SG_ 667 FLR_FreespaceSectorConfidence66 50;
BA_ "GenSigCycleTime" SG_ 667 FLR_FreespaceSectorDistance66 50;
BA_ "GenSigCycleTime" SG_ 667 FLR_FreespaceSectorKinestate65 50;
BA_ "GenSigCycleTime" SG_ 667 FLR_FreespaceSectorConfidence65 50;
BA_ "GenSigCycleTime" SG_ 667 FLR_FreespaceSectorDistance65 50;
BA_ "GenSigCycleTime" SG_ 667 FLR_FreespaceSectorKinestate64 50;
BA_ "GenSigCycleTime" SG_ 667 FLR_FreespaceSectorConfidence64 50;
BA_ "GenSigCycleTime" SG_ 667 FLR_FreespaceSectorDistance64 50;
BA_ "GenSigCycleTime" SG_ 667 FLR_FreespaceSectorKinestate63 50;
BA_ "GenSigCycleTime" SG_ 667 FLR_FreespaceSectorConfidence63 50;
BA_ "GenSigCycleTime" SG_ 667 FLR_FreespaceSectorDistance63 50;
BA_ "GenSigCycleTime" SG_ 667 FLR_FreespaceSectorKinestate62 50;
BA_ "GenSigCycleTime" SG_ 667 FLR_FreespaceSectorConfidence62 50;
BA_ "GenSigCycleTime" SG_ 667 FLR_FreespaceSectorDistance62 50;
BA_ "GenSigCycleTime" SG_ 667 FLR_FreespaceSectorKinestate61 50;
BA_ "GenSigCycleTime" SG_ 667 FLR_FreespaceSectorConfidence61 50;
BA_ "GenSigCycleTime" SG_ 667 FLR_FreespaceSectorDistance61 50;
BA_ "GenSigCycleTime" SG_ 667 FLR_FreespaceSectorKinestate60 50;
BA_ "GenSigCycleTime" SG_ 667 FLR_FreespaceSectorConfidence60 50;
BA_ "GenSigCycleTime" SG_ 667 FLR_FreespaceSectorDistance60 50;
BA_ "GenSigCycleTime" SG_ 667 FLR_FreespaceSectorKinestate59 50;
BA_ "GenSigCycleTime" SG_ 667 FLR_FreespaceSectorConfidence59 50;
BA_ "GenSigCycleTime" SG_ 667 FLR_FreespaceSectorDistance59 50;
BA_ "GenSigCycleTime" SG_ 667 FLR_FreespaceSectorKinestate58 50;
BA_ "GenSigCycleTime" SG_ 667 FLR_FreespaceSectorConfidence58 50;
BA_ "GenSigCycleTime" SG_ 667 FLR_FreespaceSectorDistance58 50;
BA_ "GenSigCycleTime" SG_ 667 FLR_FreespaceSectorKinestate57 50;
BA_ "GenSigCycleTime" SG_ 667 FLR_FreespaceSectorConfidence57 50;
BA_ "GenSigCycleTime" SG_ 667 FLR_FreespaceSectorDistance57 50;
BA_ "GenSigCycleTime" SG_ 667 FLR_FreespaceSectorKinestate56 50;
BA_ "GenSigCycleTime" SG_ 667 FLR_FreespaceSectorConfidence56 50;
BA_ "GenSigCycleTime" SG_ 667 FLR_FreespaceSectorDistance56 50;
BA_ "GenSigCycleTime" SG_ 667 FLR_FreespaceSectorKinestate55 50;
BA_ "GenSigCycleTime" SG_ 667 FLR_FreespaceSectorConfidence55 50;
BA_ "GenSigCycleTime" SG_ 667 FLR_FreespaceSectorDistance55 50;
BA_ "GenSigCycleTime" SG_ 667 FLR_FreespaceSectorKinestate54 50;
BA_ "GenSigCycleTime" SG_ 667 FLR_FreespaceSectorConfidence54 50;
BA_ "GenSigCycleTime" SG_ 667 FLR_FreespaceSectorDistance54 50;
BA_ "GenSigCycleTime" SG_ 667 FLR_FreespaceSectorKinestate53 50;
BA_ "GenSigCycleTime" SG_ 667 FLR_FreespaceSectorConfidence53 50;
BA_ "GenSigCycleTime" SG_ 667 FLR_FreespaceSectorDistance53 50;
BA_ "GenSigCycleTime" SG_ 667 FLR_FreespaceSectorKinestate52 50;
BA_ "GenSigCycleTime" SG_ 667 FLR_FreespaceSectorConfidence52 50;
BA_ "GenSigCycleTime" SG_ 667 FLR_FreespaceSectorDistance52 50;
BA_ "GenSigCycleTime" SG_ 667 FLR_FreespaceSectorKinestate51 50;
BA_ "GenSigCycleTime" SG_ 667 FLR_FreespaceSectorConfidence51 50;
BA_ "GenSigCycleTime" SG_ 667 FLR_FreespaceSectorDistance51 50;
BA_ "GenSigCycleTime" SG_ 667 FLR_FreespaceSectorKinestate50 50;
BA_ "GenSigCycleTime" SG_ 667 FLR_FreespaceSectorConfidence50 50;
BA_ "GenSigCycleTime" SG_ 667 FLR_FreespaceSectorDistance50 50;
BA_ "GenSigCycleTime" SG_ 667 FLR_FreespaceSectorKinestate49 50;
BA_ "GenSigCycleTime" SG_ 667 FLR_FreespaceSectorConfidence49 50;
BA_ "GenSigCycleTime" SG_ 667 FLR_FreespaceSectorDistance49 50;
BA_ "GenSigCycleTime" SG_ 667 FLR_FreespaceSectorKinestate48 50;
BA_ "GenSigCycleTime" SG_ 667 FLR_FreespaceSectorConfidence48 50;
BA_ "GenSigCycleTime" SG_ 667 FLR_FreespaceSectorDistance48 50;
BA_ "GenSigCycleTime" SG_ 667 FLR_FreespaceSectorKinestate47 50;
BA_ "GenSigCycleTime" SG_ 667 FLR_FreespaceSectorConfidence47 50;
BA_ "GenSigCycleTime" SG_ 667 FLR_FreespaceSectorDistance47 50;
BA_ "GenSigCycleTime" SG_ 667 FLR_FreespaceSectorKinestate46 50;
BA_ "GenSigCycleTime" SG_ 667 FLR_FreespaceSectorConfidence46 50;
BA_ "GenSigCycleTime" SG_ 667 FLR_FreespaceSectorDistance46 50;
BA_ "GenSigCycleTime" SG_ 667 FLR_FreespaceSectorKinestate45 50;
BA_ "GenSigCycleTime" SG_ 667 FLR_FreespaceSectorConfidence45 50;
BA_ "GenSigCycleTime" SG_ 667 FLR_FreespaceSectorDistance45 50;
BA_ "GenSigCycleTime" SG_ 667 FLR_FreespaceSectorKinestate44 50;
BA_ "GenSigCycleTime" SG_ 667 FLR_FreespaceSectorConfidence44 50;
BA_ "GenSigCycleTime" SG_ 667 FLR_FreespaceSectorDistance44 50;
BA_ "GenSigCycleTime" SG_ 667 FLR_FreespaceSectorKinestate43 50;
BA_ "GenSigCycleTime" SG_ 667 FLR_FreespaceSectorConfidence43 50;
BA_ "GenSigCycleTime" SG_ 667 FLR_FreespaceSectorDistance43 50;
BA_ "GenSigCycleTime" SG_ 667 FLR_FreespaceSectorKinestate42 50;
BA_ "GenSigCycleTime" SG_ 667 FLR_FreespaceSectorConfidence42 50;
BA_ "GenSigCycleTime" SG_ 667 FLR_FreespaceSectorDistance42 50;
BA_ "GenSigCycleTime" SG_ 667 FLR_FreespaceSectorKinestate41 50;
BA_ "GenSigCycleTime" SG_ 667 FLR_FreespaceSectorConfidence41 50;
BA_ "GenSigCycleTime" SG_ 667 FLR_FreespaceSectorDistance41 50;
BA_ "GenSigCycleTime" SG_ 667 FLR_FreespaceSectorKinestate40 50;
BA_ "GenSigCycleTime" SG_ 667 FLR_FreespaceSectorConfidence40 50;
BA_ "GenSigCycleTime" SG_ 667 FLR_FreespaceSectorDistance40 50;
BA_ "GenSigCycleTime" SG_ 667 FLR_FreespaceSectorKinestate39 50;
BA_ "GenSigCycleTime" SG_ 667 FLR_FreespaceSectorConfidence39 50;
BA_ "GenSigCycleTime" SG_ 667 FLR_FreespaceSectorDistance39 50;
BA_ "GenSigCycleTime" SG_ 667 FLR_FreespaceSectorKinestate38 50;
BA_ "GenSigCycleTime" SG_ 667 FLR_FreespaceSectorConfidence38 50;
BA_ "GenSigCycleTime" SG_ 667 FLR_FreespaceSectorDistance38 50;
BA_ "GenSigCycleTime" SG_ 667 FLR_FreespaceSectorKinestate37 50;
BA_ "GenSigCycleTime" SG_ 667 FLR_FreespaceSectorConfidence37 50;
BA_ "GenSigCycleTime" SG_ 667 FLR_FreespaceSectorDistance37 50;
BA_ "GenSigCycleTime" SG_ 667 FLR_FreespaceSectorKinestate36 50;
BA_ "GenSigCycleTime" SG_ 667 FLR_FreespaceSectorConfidence36 50;
BA_ "GenSigCycleTime" SG_ 667 FLR_FreespaceSectorDistance36 50;
BA_ "GenSigCycleTime" SG_ 667 FLR_FreespaceSectorKinestate35 50;
BA_ "GenSigCycleTime" SG_ 667 FLR_FreespaceSectorConfidence35 50;
BA_ "GenSigCycleTime" SG_ 667 FLR_FreespaceSectorDistance35 50;

BA_ "GenSigCycleTime" SG_ 668 FLR_CRCCheck_29C 50;
BA_ "GenSigCycleTime" SG_ 668 FLR_RollingCounter_29C 50;
BA_ "GenSigCycleTime" SG_ 668 FLR_FreespaceSectorKinestate102 50;
BA_ "GenSigCycleTime" SG_ 668 FLR_FreespaceSectorConfidence102 50;
BA_ "GenSigCycleTime" SG_ 668 FLR_FreespaceSectorDistance102 50;
BA_ "GenSigCycleTime" SG_ 668 FLR_FreespaceSectorKinestate101 50;
BA_ "GenSigCycleTime" SG_ 668 FLR_FreespaceSectorConfidence101 50;
BA_ "GenSigCycleTime" SG_ 668 FLR_FreespaceSectorDistance101 50;
BA_ "GenSigCycleTime" SG_ 668 FLR_FreespaceSectorKinestate100 50;
BA_ "GenSigCycleTime" SG_ 668 FLR_FreespaceSectorConfidence100 50;
BA_ "GenSigCycleTime" SG_ 668 FLR_FreespaceSectorDistance100 50;
BA_ "GenSigCycleTime" SG_ 668 FLR_FreespaceSectorKinestate99 50;
BA_ "GenSigCycleTime" SG_ 668 FLR_FreespaceSectorConfidence99 50;
BA_ "GenSigCycleTime" SG_ 668 FLR_FreespaceSectorDistance99 50;
BA_ "GenSigCycleTime" SG_ 668 FLR_FreespaceSectorKinestate98 50;
BA_ "GenSigCycleTime" SG_ 668 FLR_FreespaceSectorConfidence98 50;
BA_ "GenSigCycleTime" SG_ 668 FLR_FreespaceSectorDistance98 50;
BA_ "GenSigCycleTime" SG_ 668 FLR_FreespaceSectorKinestate97 50;
BA_ "GenSigCycleTime" SG_ 668 FLR_FreespaceSectorConfidence97 50;
BA_ "GenSigCycleTime" SG_ 668 FLR_FreespaceSectorDistance97 50;
BA_ "GenSigCycleTime" SG_ 668 FLR_FreespaceSectorKinestate96 50;
BA_ "GenSigCycleTime" SG_ 668 FLR_FreespaceSectorConfidence96 50;
BA_ "GenSigCycleTime" SG_ 668 FLR_FreespaceSectorDistance96 50;
BA_ "GenSigCycleTime" SG_ 668 FLR_FreespaceSectorKinestate95 50;
BA_ "GenSigCycleTime" SG_ 668 FLR_FreespaceSectorConfidence95 50;
BA_ "GenSigCycleTime" SG_ 668 FLR_FreespaceSectorDistance95 50;
BA_ "GenSigCycleTime" SG_ 668 FLR_FreespaceSectorKinestate94 50;
BA_ "GenSigCycleTime" SG_ 668 FLR_FreespaceSectorConfidence94 50;
BA_ "GenSigCycleTime" SG_ 668 FLR_FreespaceSectorDistance94 50;
BA_ "GenSigCycleTime" SG_ 668 FLR_FreespaceSectorKinestate93 50;
BA_ "GenSigCycleTime" SG_ 668 FLR_FreespaceSectorConfidence93 50;
BA_ "GenSigCycleTime" SG_ 668 FLR_FreespaceSectorDistance93 50;
BA_ "GenSigCycleTime" SG_ 668 FLR_FreespaceSectorKinestate92 50;
BA_ "GenSigCycleTime" SG_ 668 FLR_FreespaceSectorConfidence92 50;
BA_ "GenSigCycleTime" SG_ 668 FLR_FreespaceSectorDistance92 50;
BA_ "GenSigCycleTime" SG_ 668 FLR_FreespaceSectorKinestate91 50;
BA_ "GenSigCycleTime" SG_ 668 FLR_FreespaceSectorConfidence91 50;
BA_ "GenSigCycleTime" SG_ 668 FLR_FreespaceSectorDistance91 50;
BA_ "GenSigCycleTime" SG_ 668 FLR_FreespaceSectorKinestate90 50;
BA_ "GenSigCycleTime" SG_ 668 FLR_FreespaceSectorConfidence90 50;
BA_ "GenSigCycleTime" SG_ 668 FLR_FreespaceSectorDistance90 50;
BA_ "GenSigCycleTime" SG_ 668 FLR_FreespaceSectorKinestate89 50;
BA_ "GenSigCycleTime" SG_ 668 FLR_FreespaceSectorConfidence89 50;
BA_ "GenSigCycleTime" SG_ 668 FLR_FreespaceSectorDistance89 50;
BA_ "GenSigCycleTime" SG_ 668 FLR_FreespaceSectorKinestate88 50;
BA_ "GenSigCycleTime" SG_ 668 FLR_FreespaceSectorConfidence88 50;
BA_ "GenSigCycleTime" SG_ 668 FLR_FreespaceSectorDistance88 50;
BA_ "GenSigCycleTime" SG_ 668 FLR_FreespaceSectorKinestate87 50;
BA_ "GenSigCycleTime" SG_ 668 FLR_FreespaceSectorConfidence87 50;
BA_ "GenSigCycleTime" SG_ 668 FLR_FreespaceSectorDistance87 50;
BA_ "GenSigCycleTime" SG_ 668 FLR_FreespaceSectorKinestate86 50;
BA_ "GenSigCycleTime" SG_ 668 FLR_FreespaceSectorConfidence86 50;
BA_ "GenSigCycleTime" SG_ 668 FLR_FreespaceSectorDistance86 50;
BA_ "GenSigCycleTime" SG_ 668 FLR_FreespaceSectorKinestate85 50;
BA_ "GenSigCycleTime" SG_ 668 FLR_FreespaceSectorConfidence85 50;
BA_ "GenSigCycleTime" SG_ 668 FLR_FreespaceSectorDistance85 50;
BA_ "GenSigCycleTime" SG_ 668 FLR_FreespaceSectorKinestate84 50;
BA_ "GenSigCycleTime" SG_ 668 FLR_FreespaceSectorConfidence84 50;
BA_ "GenSigCycleTime" SG_ 668 FLR_FreespaceSectorDistance84 50;
BA_ "GenSigCycleTime" SG_ 668 FLR_FreespaceSectorKinestate83 50;
BA_ "GenSigCycleTime" SG_ 668 FLR_FreespaceSectorConfidence83 50;
BA_ "GenSigCycleTime" SG_ 668 FLR_FreespaceSectorDistance83 50;
BA_ "GenSigCycleTime" SG_ 668 FLR_FreespaceSectorKinestate82 50;
BA_ "GenSigCycleTime" SG_ 668 FLR_FreespaceSectorConfidence82 50;
BA_ "GenSigCycleTime" SG_ 668 FLR_FreespaceSectorDistance82 50;
BA_ "GenSigCycleTime" SG_ 668 FLR_FreespaceSectorKinestate81 50;
BA_ "GenSigCycleTime" SG_ 668 FLR_FreespaceSectorConfidence81 50;
BA_ "GenSigCycleTime" SG_ 668 FLR_FreespaceSectorDistance81 50;
BA_ "GenSigCycleTime" SG_ 668 FLR_FreespaceSectorKinestate80 50;
BA_ "GenSigCycleTime" SG_ 668 FLR_FreespaceSectorConfidence80 50;
BA_ "GenSigCycleTime" SG_ 668 FLR_FreespaceSectorDistance80 50;
BA_ "GenSigCycleTime" SG_ 668 FLR_FreespaceSectorKinestate79 50;
BA_ "GenSigCycleTime" SG_ 668 FLR_FreespaceSectorConfidence79 50;
BA_ "GenSigCycleTime" SG_ 668 FLR_FreespaceSectorDistance79 50;
BA_ "GenSigCycleTime" SG_ 668 FLR_FreespaceSectorKinestate78 50;
BA_ "GenSigCycleTime" SG_ 668 FLR_FreespaceSectorConfidence78 50;
BA_ "GenSigCycleTime" SG_ 668 FLR_FreespaceSectorDistance78 50;
BA_ "GenSigCycleTime" SG_ 668 FLR_FreespaceSectorKinestate77 50;
BA_ "GenSigCycleTime" SG_ 668 FLR_FreespaceSectorConfidence77 50;
BA_ "GenSigCycleTime" SG_ 668 FLR_FreespaceSectorDistance77 50;
BA_ "GenSigCycleTime" SG_ 668 FLR_FreespaceSectorKinestate76 50;
BA_ "GenSigCycleTime" SG_ 668 FLR_FreespaceSectorConfidence76 50;
BA_ "GenSigCycleTime" SG_ 668 FLR_FreespaceSectorDistance76 50;
BA_ "GenSigCycleTime" SG_ 668 FLR_FreespaceSectorKinestate75 50;
BA_ "GenSigCycleTime" SG_ 668 FLR_FreespaceSectorConfidence75 50;
BA_ "GenSigCycleTime" SG_ 668 FLR_FreespaceSectorDistance75 50;
BA_ "GenSigCycleTime" SG_ 668 FLR_FreespaceSectorKinestate74 50;
BA_ "GenSigCycleTime" SG_ 668 FLR_FreespaceSectorConfidence74 50;
BA_ "GenSigCycleTime" SG_ 668 FLR_FreespaceSectorDistance74 50;
BA_ "GenSigCycleTime" SG_ 668 FLR_FreespaceSectorKinestate73 50;
BA_ "GenSigCycleTime" SG_ 668 FLR_FreespaceSectorConfidence73 50;
BA_ "GenSigCycleTime" SG_ 668 FLR_FreespaceSectorDistance73 50;
BA_ "GenSigCycleTime" SG_ 668 FLR_FreespaceSectorKinestate72 50;
BA_ "GenSigCycleTime" SG_ 668 FLR_FreespaceSectorConfidence72 50;
BA_ "GenSigCycleTime" SG_ 668 FLR_FreespaceSectorDistance72 50;
BA_ "GenSigCycleTime" SG_ 668 FLR_FreespaceSectorKinestate71 50;
BA_ "GenSigCycleTime" SG_ 668 FLR_FreespaceSectorConfidence71 50;
BA_ "GenSigCycleTime" SG_ 668 FLR_FreespaceSectorDistance71 50;
BA_ "GenSigCycleTime" SG_ 668 FLR_FreespaceSectorKinestate70 50;
BA_ "GenSigCycleTime" SG_ 668 FLR_FreespaceSectorConfidence70 50;
BA_ "GenSigCycleTime" SG_ 668 FLR_FreespaceSectorDistance70 50;
BA_ "GenSigCycleTime" SG_ 668 FLR_FreespaceSectorKinestate69 50;
BA_ "GenSigCycleTime" SG_ 668 FLR_FreespaceSectorConfidence69 50;
BA_ "GenSigCycleTime" SG_ 668 FLR_FreespaceSectorDistance69 50;

VAL_ 604 FLR_OBJ26_Convergence 0 "╩╒┴▓
0x1=▓╗╩╒┴▓";
VAL_ 604 FLR_OBJ26_MotionStatus 0 "unknown" 1 "moving " 2 "stopped" 3 "stationary" 4 "crossing" 5 "reserve;";
VAL_ 604 FLR_OBJ25_Convergence 0 "╩╒┴▓
0x1=▓╗╩╒┴▓";
VAL_ 604 FLR_OBJ25_MotionStatus 0 "unknown" 1 "moving " 2 "stopped" 3 "stationary" 4 "crossing" 5 "reserve;";
VAL_ 604 FLR_OBJ26_Measured 0 "unknown" 1 "Measured" 2 "Predicted" 3 "Reserved";
VAL_ 604 FLR_OBJ26_Location 0 "unknown" 1 "Left Lane" 2 "Right  Lane" 3 "Ego Lane";
VAL_ 604 FLR_OBJ26_Type 0 "Not Detected" 1 "car" 2 "truck" 3 "bicycle/motorbike" 4 "pedestrian" 5 "general" 6 "animal" 7 "uncertain";
VAL_ 604 FLR_OBJ25_Measured 0 "unknown" 1 "Measured" 2 "Predicted" 3 "Reserved";
VAL_ 604 FLR_OBJ25_Location 0 "unknown" 1 "Left Lane" 2 "Right  Lane" 3 "Ego Lane";
VAL_ 604 FLR_OBJ25_Type 0 "Not Detected" 1 "car" 2 "truck" 3 "bicycle/motorbike" 4 "pedestrian" 5 "general" 6 "animal" 7 "uncertain";

VAL_ 605 FLR_OBJ28_Convergence 0 "╩╒┴▓
0x1=▓╗╩╒┴▓";
VAL_ 605 FLR_OBJ28_MotionStatus 0 "unknown" 1 "moving " 2 "stopped" 3 "stationary" 4 "crossing" 5 "reserve;";
VAL_ 605 FLR_OBJ27_Convergence 0 "╩╒┴▓
0x1=▓╗╩╒┴▓";
VAL_ 605 FLR_OBJ27_MotionStatus 0 "unknown" 1 "moving " 2 "stopped" 3 "stationary" 4 "crossing" 5 "reserve;";
VAL_ 605 FLR_OBJ28_Measured 0 "unknown" 1 "Measured" 2 "Predicted" 3 "Reserved";
VAL_ 605 FLR_OBJ28_Location 0 "unknown" 1 "Left Lane" 2 "Right  Lane" 3 "Ego Lane";
VAL_ 605 FLR_OBJ28_Type 0 "Not Detected" 1 "car" 2 "truck" 3 "bicycle/motorbike" 4 "pedestrian" 5 "general" 6 "animal" 7 "uncertain";
VAL_ 605 FLR_OBJ27_Measured 0 "unknown" 1 "Measured" 2 "Predicted" 3 "Reserved";
VAL_ 605 FLR_OBJ27_Location 0 "unknown" 1 "Left Lane" 2 "Right  Lane" 3 "Ego Lane";
VAL_ 605 FLR_OBJ27_Type 0 "Not Detected" 1 "car" 2 "truck" 3 "bicycle/motorbike" 4 "pedestrian" 5 "general" 6 "animal" 7 "uncertain";

VAL_ 606 FLR_OBJ30_Convergence 0 "╩╒┴▓
0x1=▓╗╩╒┴▓";
VAL_ 606 FLR_OBJ30_MotionStatus 0 "unknown" 1 "moving " 2 "stopped" 3 "stationary" 4 "crossing" 5 "reserve;";
VAL_ 606 FLR_OBJ29_Convergence 0 "╩╒┴▓
0x1=▓╗╩╒┴▓";
VAL_ 606 FLR_OBJ29_MotionStatus 0 "unknown" 1 "moving " 2 "stopped" 3 "stationary" 4 "crossing" 5 "reserve;";
VAL_ 606 FLR_OBJ30_Measured 0 "unknown" 1 "Measured" 2 "Predicted" 3 "Reserved";
VAL_ 606 FLR_OBJ30_Location 0 "unknown" 1 "Left Lane" 2 "Right  Lane" 3 "Ego Lane";
VAL_ 606 FLR_OBJ30_Type 0 "Not Detected" 1 "car" 2 "truck" 3 "bicycle/motorbike" 4 "pedestrian" 5 "general" 6 "animal" 7 "uncertain";
VAL_ 606 FLR_OBJ29_Measured 0 "unknown" 1 "Measured" 2 "Predicted" 3 "Reserved";
VAL_ 606 FLR_OBJ29_Location 0 "unknown" 1 "Left Lane" 2 "Right  Lane" 3 "Ego Lane";
VAL_ 606 FLR_OBJ29_Type 0 "Not Detected" 1 "car" 2 "truck" 3 "bicycle/motorbike" 4 "pedestrian" 5 "general" 6 "animal" 7 "uncertain";

VAL_ 607 FLR_OBJ32_Convergence 0 "╩╒┴▓
0x1=▓╗╩╒┴▓";
VAL_ 607 FLR_OBJ32_MotionStatus 0 "unknown" 1 "moving " 2 "stopped" 3 "stationary" 4 "crossing" 5 "reserve;";
VAL_ 607 FLR_OBJ31_Convergence 0 "╩╒┴▓
0x1=▓╗╩╒┴▓";
VAL_ 607 FLR_OBJ31_MotionStatus 0 "unknown" 1 "moving " 2 "stopped" 3 "stationary" 4 "crossing" 5 "reserve;";
VAL_ 607 FLR_OBJ32_Measured 0 "unknown" 1 "Measured" 2 "Predicted" 3 "Reserved";
VAL_ 607 FLR_OBJ32_Location 0 "unknown" 1 "Left Lane" 2 "Right  Lane" 3 "Ego Lane";
VAL_ 607 FLR_OBJ32_Type 0 "Not Detected" 1 "car" 2 "truck" 3 "bicycle/motorbike" 4 "pedestrian" 5 "general" 6 "animal" 7 "uncertain";
VAL_ 607 FLR_OBJ31_Measured 0 "unknown" 1 "Measured" 2 "Predicted" 3 "Reserved";
VAL_ 607 FLR_OBJ31_Location 0 "unknown" 1 "Left Lane" 2 "Right  Lane" 3 "Ego Lane";
VAL_ 607 FLR_OBJ31_Type 0 "Not Detected" 1 "car" 2 "truck" 3 "bicycle/motorbike" 4 "pedestrian" 5 "general" 6 "animal" 7 "uncertain";

VAL_ 687 FRR_HwVers6 48 "0" 49 "1" 50 "2" 51 "3" 52 "4" 53 "5" 54 "6" 55 "7" 56 "8" 57 "9" 65 "A" 66 "B" 67 "C" 68 "D" 69 "E" 70 "F" 71 "G" 72 "H" 73 "I" 74 "J" 75 "K" 76 "L" 77 "M" 78 "N" 79 "O" 80 "P" 81 "Q" 82 "R" 83 "S" 84 "T" 85 "U" 86 "V" 87 "W" 88 "X" 89 "Y" 90 "Z";
VAL_ 687 FRR_HwVers5 46 ".";
VAL_ 687 FRR_HwVers4 48 "0" 49 "1" 50 "2" 51 "3" 52 "4" 53 "5" 54 "6" 55 "7" 56 "8" 57 "9" 65 "A" 66 "B" 67 "C" 68 "D" 69 "E" 70 "F" 71 "G" 72 "H" 73 "I" 74 "J" 75 "K" 76 "L" 77 "M" 78 "N" 79 "O" 80 "P" 81 "Q" 82 "R" 83 "S" 84 "T" 85 "U" 86 "V" 87 "W" 88 "X" 89 "Y" 90 "Z";
VAL_ 687 FRR_HwVers3 46 ".";
VAL_ 687 FRR_HwVers2 48 "0" 49 "1" 50 "2" 51 "3" 52 "4" 53 "5" 54 "6" 55 "7" 56 "8" 57 "9" 65 "A" 66 "B" 67 "C" 68 "D" 69 "E" 70 "F" 71 "G" 72 "H" 73 "I" 74 "J" 75 "K" 76 "L" 77 "M" 78 "N" 79 "O" 80 "P" 81 "Q" 82 "R" 83 "S" 84 "T" 85 "U" 86 "V" 87 "W" 88 "X" 89 "Y" 90 "Z";
VAL_ 687 FRR_HwVers1 87 "W";
VAL_ 687 FRR_HwVers0 72 "H";
VAL_ 687 FRR_SwVers6 48 "0" 49 "1" 50 "2" 51 "3" 52 "4" 53 "5" 54 "6" 55 "7" 56 "8" 57 "9" 65 "A" 66 "B" 67 "C" 68 "D" 69 "E" 70 "F" 71 "G" 72 "H" 73 "I" 74 "J" 75 "K" 76 "L" 77 "M" 78 "N" 79 "O" 80 "P" 81 "Q" 82 "R" 83 "S" 84 "T" 85 "U" 86 "V" 87 "W" 88 "X" 89 "Y" 90 "Z";
VAL_ 687 FRR_SwVers5 46 ".";
VAL_ 687 FRR_SwVers4 48 "0" 49 "1" 50 "2" 51 "3" 52 "4" 53 "5" 54 "6" 55 "7" 56 "8" 57 "9" 65 "A" 66 "B" 67 "C" 68 "D" 69 "E" 70 "F" 71 "G" 72 "H" 73 "I" 74 "J" 75 "K" 76 "L" 77 "M" 78 "N" 79 "O" 80 "P" 81 "Q" 82 "R" 83 "S" 84 "T" 85 "U" 86 "V" 87 "W" 88 "X" 89 "Y" 90 "Z";
VAL_ 687 FRR_SwVers3 46 ".";
VAL_ 687 FRR_SwVers2 48 "0" 49 "1" 50 "2" 51 "3" 52 "4" 53 "5" 54 "6" 55 "7" 56 "8" 57 "9" 65 "A" 66 "B" 67 "C" 68 "D" 69 "E" 70 "F" 71 "G" 72 "H" 73 "I" 74 "J" 75 "K" 76 "L" 77 "M" 78 "N" 79 "O" 80 "P" 81 "Q" 82 "R" 83 "S" 84 "T" 85 "U" 86 "V" 87 "W" 88 "X" 89 "Y" 90 "Z";
VAL_ 687 FRR_SwVers1 87 "W";
VAL_ 687 FRR_SwVers0 83 "S";
VAL_ 687 FLR_HwVers6 48 "0" 49 "1" 50 "2" 51 "3" 52 "4" 53 "5" 54 "6" 55 "7" 56 "8" 57 "9" 65 "A" 66 "B" 67 "C" 68 "D" 69 "E" 70 "F" 71 "G" 72 "H" 73 "I" 74 "J" 75 "K" 76 "L" 77 "M" 78 "N" 79 "O" 80 "P" 81 "Q" 82 "R" 83 "S" 84 "T" 85 "U" 86 "V" 87 "W" 88 "X" 89 "Y" 90 "Z";
VAL_ 687 FLR_HwVers5 46 ".";
VAL_ 687 FLR_HwVers4 48 "0" 49 "1" 50 "2" 51 "3" 52 "4" 53 "5" 54 "6" 55 "7" 56 "8" 57 "9" 65 "A" 66 "B" 67 "C" 68 "D" 69 "E" 70 "F" 71 "G" 72 "H" 73 "I" 74 "J" 75 "K" 76 "L" 77 "M" 78 "N" 79 "O" 80 "P" 81 "Q" 82 "R" 83 "S" 84 "T" 85 "U" 86 "V" 87 "W" 88 "X" 89 "Y" 90 "Z";
VAL_ 687 FLR_HwVers3 46 ".";
VAL_ 687 FLR_HwVers2 48 "0" 49 "1" 50 "2" 51 "3" 52 "4" 53 "5" 54 "6" 55 "7" 56 "8" 57 "9" 65 "A" 66 "B" 67 "C" 68 "D" 69 "E" 70 "F" 71 "G" 72 "H" 73 "I" 74 "J" 75 "K" 76 "L" 77 "M" 78 "N" 79 "O" 80 "P" 81 "Q" 82 "R" 83 "S" 84 "T" 85 "U" 86 "V" 87 "W" 88 "X" 89 "Y" 90 "Z";
VAL_ 687 FLR_HwVers1 87 "W";
VAL_ 687 FLR_HwVers0 72 "H";
VAL_ 687 FLR_SwVers6 48 "0" 49 "1" 50 "2" 51 "3" 52 "4" 53 "5" 54 "6" 55 "7" 56 "8" 57 "9" 65 "A" 66 "B" 67 "C" 68 "D" 69 "E" 70 "F" 71 "G" 72 "H" 73 "I" 74 "J" 75 "K" 76 "L" 77 "M" 78 "N" 79 "O" 80 "P" 81 "Q" 82 "R" 83 "S" 84 "T" 85 "U" 86 "V" 87 "W" 88 "X" 89 "Y" 90 "Z";
VAL_ 687 FLR_SwVers5 46 ".";
VAL_ 687 FLR_SwVers4 48 "0" 49 "1" 50 "2" 51 "3" 52 "4" 53 "5" 54 "6" 55 "7" 56 "8" 57 "9" 65 "A" 66 "B" 67 "C" 68 "D" 69 "E" 70 "F" 71 "G" 72 "H" 73 "I" 74 "J" 75 "K" 76 "L" 77 "M" 78 "N" 79 "O" 80 "P" 81 "Q" 82 "R" 83 "S" 84 "T" 85 "U" 86 "V" 87 "W" 88 "X" 89 "Y" 90 "Z";
VAL_ 687 FLR_SwVers3 46 ".";
VAL_ 687 FLR_SwVers2 48 "0" 49 "1" 50 "2" 51 "3" 52 "4" 53 "5" 54 "6" 55 "7" 56 "8" 57 "9" 65 "A" 66 "B" 67 "C" 68 "D" 69 "E" 70 "F" 71 "G" 72 "H" 73 "I" 74 "J" 75 "K" 76 "L" 77 "M" 78 "N" 79 "O" 80 "P" 81 "Q" 82 "R" 83 "S" 84 "T" 85 "U" 86 "V" 87 "W" 88 "X" 89 "Y" 90 "Z";
VAL_ 687 FLR_SwVers1 87 "W";
VAL_ 687 FLR_SwVers0 83 "S";

VAL_ 690 FLR_ResetSts 0 "Valid" 1 "GW╟ы╟є╕┤╬╗" 2 "╫╘╔э┼╨╢╧╕┤╬╗" 3 "▓╗┬·╫у╕┤╬╗╠ї╝■" 4 "Reserve" 7 "Invalid";
VAL_ 690 RealTimeCal_Status_FL 0 "╬┤┐к╩╝
0x1=┐к╩╝
0x2=│╔╣ж
0x3=╩з░▄
0x4= ╚╦╣д╚б╧√";
VAL_ 690 DiagCal_Status_FL 0 "╬┤┐к╩╝
0x1=┐к╩╝
0x2=│╔╣ж
0x3=╩з░▄
0x4= ╚╦╣д╚б╧√";
VAL_ 690 EolCal_Status_FL 0 "╬┤┐к╩╝
0x1=┐к╩╝
0x2=│╔╣ж
0x3=╩з░▄
0x4= ╚╦╣д╚б╧√";

VAL_ 579 FLR_Measured_R 0 "unknown" 1 "Measured" 2 "Predicted" 3 "Reserved";
VAL_ 579 FLR_Location_R 0 "unknown" 1 "Left Lane" 2 "Right  Lane" 3 "Ego Lane";
VAL_ 579 FLR_ClassComfrmFlg_R 0 "╬┤╚╖╚╧" 1 "╥╤╚╖╚╧;";
VAL_ 579 FLR_TrckrType_R 0 "Not Detected" 1 "car" 2 "truck" 3 "bicycle/motorbike" 4 "pedestrian" 5 "general" 6 "animal" 7 "uncertain";
VAL_ 579 FLR_MotionStatus_R 0 "unknown" 1 "moving " 2 "stopped" 3 "stationary" 4 "crossing" 5 "reserve;";
VAL_ 579 FLR_Measured_L 0 "unknown" 1 "Measured" 2 "Predicted" 3 "Reserved";
VAL_ 579 FLR_Location_L 0 "unknown" 1 "Left Lane" 2 "Right  Lane" 3 "Ego Lane";
VAL_ 579 FLR_ClassComfrmFlg_L 0 "╬┤╚╖╚╧" 1 "╥╤╚╖╚╧;";
VAL_ 579 FLR_TrckrType_L 0 "Not Detected" 1 "car" 2 "truck" 3 "bicycle/motorbike" 4 "pedestrian" 5 "general" 6 "animal" 7 "uncertain";
VAL_ 579 FLR_MotionStatus_L 0 "unknown" 1 "moving " 2 "stopped" 3 "stationary" 4 "crossing" 5 "reserve;";

VAL_ 589 FRR_Right_FCTARAlert 0 "No FCTA warning" 1 "FCTA warning Level1" 2 "FCTA warning Level2" 3 "FCTA warning Level3";
VAL_ 589 FRR_FCTBActive 0 "not Active" 1 "Active.";
VAL_ 589 FRR_EmergencyLightingRequest 0 "no request" 1 "Level1" 2 "Level2" 3 "OFF";
VAL_ 589 FRR_FCTBVehilceHoldReq 0 " No hold" 1 " hold";
VAL_ 589 FRR_FCTBStatus 0 "OFF(╣╪▒╒)" 1 "Inactive(╬┤╝д╗ю)" 2 "Active" 3 "Failure";
VAL_ 589 FRR_FCTAStatus 0 "OFF(╣╪▒╒)" 1 "Inactive(╬┤╝д╗ю)" 2 "Active" 3 "Failure";
VAL_ 589 FRR_Left_FCTALAlert 0 "No FCTA warning" 1 "FCTA warning Level1" 2 "FCTA warning Level2" 3 "FCTA warning Level3";

VAL_ 585 FRR_Suppliers 0 " ZM
0x1 = SSTK
0x2~0x15=Reserve";
VAL_ 585 FRR_FS_TiOut 0 "no timeout" 1 "timeout";
VAL_ 585 FRR_ECU_TiOut 0 "no timeout" 1 "timeout";
VAL_ 585 FRR_WorkMode 0 "Initial Value" 1 "╨╨│╡─г╩╜" 2 "▓┤│╡─г╩╜" 3 "╟╨╗╗╓╨";
VAL_ 585 FRR_SystemStatus 0 "╡═╣ж║─╫┤╠м" 1 "StartUp" 2 "Running" 3 "Blocked" 4 "Calibration" 5 "ShutDown" 6 "Hot" 7 "Failure";
